VERSION ""

NS_ :

BS_:

BU_: RFA_BLEM TCU GWM _delete GENERIC TSTR

BO_ 966 Body_Info_14_FD2: 16 GWM
 SG_ NfcDevcAuthrzT_B_Rq : 33|1@0+ (1,0) [0|1] "SED"  GENERIC,_delete
 SG_ NfcDevc_D_Dsply : 47|4@0+ (1,0) [0|15] "SED"  GENERIC
 SG_ PwTrnkFrntRelay_B_Stat : 34|1@0+ (1,0) [0|1] "SED"  GENERIC
 SG_ PwTrnkFrontRleas_D_Src : 38|4@0+ (1,0) [0|15] "SED"  GENERIC
 SG_ TrnkFrontScnd_B_Falt : 39|1@0+ (1,0) [0|1] "SED"  GENERIC
 SG_ ExtLghtRear_D_RqBody : 25|2@0+ (1,0) [0|3] "SED"  GENERIC
 SG_ TrnkFrontInhbt_B_Stat : 26|1@0+ (1,0) [0|1] "SED"  GENERIC
 SG_ TrnkFrontRleas_D_Src : 20|3@0+ (1,0) [0|7] "SED"  GENERIC
 SG_ TrunkFrontRolCd_No_Actl : 7|16@0+ (1,0) [0|65535] "unitless"  GENERIC
 SG_ TrunkFrontOpen_No_Actl : 23|3@0+ (1,0) [0|7] "unitless"  GENERIC
 SG_ ScrtyHornActv_B_Rq : 27|1@0+ (1,0) [0|1] "SED"  GENERIC
 SG_ VehHorn_D_RqAlrt : 17|2@0+ (1,0) [0|3] "SED"  GENERIC
 SG_ VehHorn_D_Rq : 31|4@0+ (1,0) [0|15] "SED"  GENERIC

BO_ 119 BrakeSnData_3_FD2: 16 GWM
 SG_ VehTrvlDir_D_Stat : 23|3@0+ (1,0) [0|7] "SED"  GENERIC
 SG_ VehOverGnd_V_Est : 7|16@0+ (0.01,0) [0|655.33] "kph"  GENERIC
 SG_ VehLongComp_A_Actl : 49|10@0+ (0.035,-17.9) [-17.9|17.835] "m/s^2"  GENERIC,_delete,TCU
 SG_ VehLatComp_A_Actl : 43|10@0+ (0.035,-17.9) [-17.9|17.835] "m/s^2"  GENERIC
 SG_ VehYawComp_W_Actl : 19|12@0+ (0.03663,-75) [-75|74.92659] "deg/s"  GENERIC
 SG_ PrplWhlPrim_Tq_RqMx : 39|12@0+ (8,0) [0|32760] "Nm"  GENERIC

BO_ 517 PowertrainData_6_FD2: 16 GWM
 SG_ FapLc_B_Err : 10|1@0+ (1,0) [0|1] "SED"  GENERIC,RFA_BLEM,_delete
 SG_ BrkTot_Tq_RqFapLc : 7|13@0+ (4,0) [0|32764] "Nm"  GENERIC,_delete
 SG_ TrnAin_Pc_RqDrv : 9|10@0+ (0.1,0) [0|102.3] "percent"  GENERIC,_delete

BO_ 985 IPMA_Data2_FD2: 16 GWM
 SG_ LongCtrlEnblDRq_No_Cs : 63|8@0+ (1,0) [0|255] "Unitless"  GENERIC,RFA_BLEM,_delete
 SG_ LongCtrlEnblDRq_No_Cnt : 29|4@0+ (1,0) [0|15] "Unitless"  GENERIC,RFA_BLEM,_delete
 SG_ ClrExitAsst_D_Stat : 39|2@0+ (1,0) [0|3] "SED"  GENERIC,_delete
 SG_ ClrExitAsstMsgTxt_D_Rq : 52|4@0+ (1,0) [0|15] "SED"  GENERIC,_delete
 SG_ ClrExitAsstChime_D_Rq : 55|3@0+ (1,0) [0|7] "SED"  GENERIC,_delete
 SG_ PwSustnAdas_B_Rq : 48|1@0+ (1,0) [0|1] "SED"  GENERIC,_delete
 SG_ AdbDrvSide_B_Stat : 35|1@0+ (1,0) [0|1] "SED"  GENERIC,_delete
 SG_ LcwaMsgTxt_D_Stat : 37|2@0+ (1,0) [0|3] "SED"  GENERIC,_delete
 SG_ AdbDividedRoad_B_Stat : 30|1@0+ (1,0) [0|1] "SED"  GENERIC,_delete
 SG_ IsaVLimUnit_D_Rq : 15|2@0+ (1,0) [0|3] "SED"  GENERIC,_delete
 SG_ SblmYieldScnr_B_Stat : 31|1@0+ (1,0) [0|1] "SED"  GENERIC,_delete
 SG_ SblmStopScnr_B_Stat : 8|1@0+ (1,0) [0|1] "SED"  GENERIC,_delete
 SG_ IsaVLim_D_Rq : 7|8@0+ (1,0) [0|255] "SED"  GENERIC,_delete
 SG_ IaccVLimUnit_D_Rq : 11|2@0+ (1,0) [0|3] "SED"  GENERIC
 SG_ IaccVLim_D_Rq : 23|8@0+ (1,0) [0|255] "SED"  GENERIC
 SG_ DasAlrtInfo_D_Dsply : 13|2@0+ (1,0) [0|3] "SED"  GENERIC,_delete
 SG_ SblmRndAbtScnr_B_Stat : 9|1@0+ (1,0) [0|1] "SED"  GENERIC,_delete
 SG_ LongCtrlEnbl_D_Rq : 42|3@0+ (1,0) [0|7] "SED"  GENERIC,RFA_BLEM,_delete
 SG_ SblmPedCrossScnr_B_Stat : 33|1@0+ (1,0) [0|1] "SED"  GENERIC,_delete
 SG_ TsrRegionTxt_D_Stat : 47|5@0+ (1,0) [0|31] "SED"  GENERIC
 SG_ LongCtrlBrk_D_Rq : 25|2@0+ (1,0) [0|3] "SED"  GENERIC,_delete
 SG_ LdwChime_B_Rq : 34|1@0+ (1,0) [0|1] "SED"  GENERIC,_delete

BO_ 1927 TesterPhysicalReqWBCM: 64 TSTR
 SG_ TesterPhysicalReqWBCM : 7|64@0+ (1,0) [0|1.84467E+019] "unitless"  GENERIC

BO_ 942 ParkAid_Data2_FD2: 16 GWM
 SG_ ApaOffOptnSel_B_Avail : 51|1@0+ (1,0) [0|1] "SED"  GENERIC,_delete
 SG_ ApaSlotOption_B_Avail : 43|1@0+ (1,0) [0|1] "SED"  GENERIC,_delete
 SG_ ApaSlotAlrtSet_B_Stat : 44|1@0+ (1,0) [0|1] "SED"  GENERIC,_delete
 SG_ ApaSlotAlrt_B_Rq : 45|1@0+ (1,0) [0|1] "SED"  GENERIC,_delete
 SG_ ApaRmtFeatSel_B_Avail : 46|1@0+ (1,0) [0|1] "SED"  GENERIC,_delete
 SG_ ApaParkOutSel_B_Avail : 47|1@0+ (1,0) [0|1] "SED"  GENERIC,_delete
 SG_ ApaSys_D2_Stat : 35|4@0+ (1,0) [0|15] "SED"  GENERIC,_delete
 SG_ ApaSlotTrgt_D_Stat : 39|4@0+ (1,0) [0|15] "SED"  GENERIC,_delete
 SG_ ApaParkInSel_B_Avail : 24|1@0+ (1,0) [0|1] "SED"  GENERIC,_delete
 SG_ ApaMsgTxt_D2_Stat : 28|4@0+ (1,0) [0|15] "SED"  GENERIC,_delete
 SG_ ApaDynmcSlot_B_Stat : 29|1@0+ (1,0) [0|1] "SED"  GENERIC,_delete
 SG_ ApaDisplayMode_D_Stat : 31|2@0+ (1,0) [0|3] "SED"  GENERIC,_delete
 SG_ ApaControlMode_D_Stat : 16|1@0+ (1,0) [0|1] "SED"  GENERIC,_delete
 SG_ PrkBrkElRleas_B_RqApa : 50|1@0+ (1,0) [0|1] "SED"  GENERIC,_delete
 SG_ PrkAidAcsyRear_D_Stat : 18|2@0+ (1,0) [0|3] "SED"  GENERIC,_delete
 SG_ PrkAidAcsyFront_D_Stat : 20|2@0+ (1,0) [0|3] "SED"  GENERIC,_delete
 SG_ PrkAidRdiusRight_L_Dsply : 15|8@0+ (1,0) [0|255] "unitless"  GENERIC,_delete
 SG_ PrkAidRdiusLeft_L_Dsply : 7|8@0+ (1,0) [0|255] "unitless"  GENERIC,_delete
 SG_ PrkAidDrvDir_D_Stat : 23|3@0+ (1,0) [0|7] "SED"  GENERIC,_delete
 SG_ ApaDrvRq2MsgTxt_D_Rq : 55|4@0+ (1,0) [0|15] "SED"  GENERIC,_delete
 SG_ ApaDrvRq1MsgTxt_D_Rq : 42|3@0+ (1,0) [0|7] "SED"  GENERIC,RFA_BLEM,_delete

BO_ 1734 TesterPhysicalReqNFAM: 64 TSTR
 SG_ TesterPhysicalReqNFAM : 7|64@0+ (1,0) [0|1.84467E+019] "unitless"  GENERIC

BO_ 367 Av_ECGtoDAP: 64 GWM
 SG_ AuthctnStatIndx_No_Actl : 127|6@0+ (1,0) [0|63] "unitless"  GENERIC,_delete
 SG_ AuthctnStatId_No_Actl : 63|32@0+ (1,0) [0|4294967295] "unitless"  GENERIC,_delete
 SG_ AuthctnInfoLoc_D_Stat : 47|3@0+ (1,0) [0|7] "SED"  GENERIC,_delete
 SG_ AuthctnInfo_D_Stat : 33|2@0+ (1,0) [0|3] "SED"  GENERIC,_delete
 SG_ AuthctnInfoIndx_No_Actl : 39|6@0+ (1,0) [0|63] "unitless"  GENERIC,_delete
 SG_ AuthctnInfoId_No_Actl : 7|32@0+ (1,0) [0|4294967295] "unitless"  GENERIC,_delete
 SG_ HashNonce2_No_Res : 375|64@0+ (1,0) [0|1.84467440737096E+019] "unitless"  GENERIC,_delete
 SG_ HashNonce1_No_Res : 311|64@0+ (1,0) [0|1.84467440737096E+019] "unitless"  GENERIC,_delete
 SG_ HashSalt2_No_Res : 247|64@0+ (1,0) [0|1.84467440737096E+019] "unitless"  GENERIC,_delete
 SG_ HashSalt1_No_Res : 183|64@0+ (1,0) [0|1.84467440737096E+019] "unitless"  GENERIC,_delete
 SG_ HashIndx_D_Stat : 169|2@0+ (1,0) [0|3] "SED"  GENERIC,_delete
 SG_ HashIndx_No_Actl : 175|6@0+ (1,0) [0|63] "unitless"  GENERIC,_delete
 SG_ HashId_No_Actl : 143|32@0+ (1,0) [0|4294967295] "unitless"  GENERIC,_delete
 SG_ ApnlPsswrdType_D_Stat : 121|4@0+ (1,0) [0|15] "SED"  GENERIC,_delete
 SG_ ApnlPsswrdIndx_No_Actl : 133|6@0+ (1,0) [0|63] "unitless"  GENERIC,_delete
 SG_ ApnlPsswrdId_No_Actl : 95|32@0+ (1,0) [0|4294967295] "unitless"  GENERIC,_delete
 SG_ AuthctnStatRtry_No_Actl : 55|4@0+ (1,0) [0|15] "unitless"  GENERIC,_delete
 SG_ AuthctnStatChnl_D_Stat : 51|4@0+ (1,0) [0|15] "SED"  GENERIC,_delete
 SG_ AuthctnStat_D_Stat : 44|2@0+ (1,0) [0|3] "SED"  GENERIC,_delete

BO_ 1203 Av_PartName: 64 GWM
 SG_ ApnlNameTxt18_No_Actl : 143|8@0+ (1,0) [0|255] "unitless"  GENERIC,_delete
 SG_ ApnlNameTxt17_No_Actl : 135|8@0+ (1,0) [0|255] "unitless"  GENERIC,_delete
 SG_ ApnlNameTxt16_No_Actl : 127|8@0+ (1,0) [0|255] "unitless"  GENERIC,_delete
 SG_ ApnlNameTxt15_No_Actl : 119|8@0+ (1,0) [0|255] "unitless"  GENERIC,_delete
 SG_ ApnlNameTxt14_No_Actl : 111|8@0+ (1,0) [0|255] "unitless"  GENERIC,_delete
 SG_ ApnlNameTxt13_No_Actl : 103|8@0+ (1,0) [0|255] "unitless"  GENERIC,_delete
 SG_ ApnlNameTxt12_No_Actl : 95|8@0+ (1,0) [0|255] "unitless"  GENERIC,_delete
 SG_ ApnlNameTxt11_No_Actl : 87|8@0+ (1,0) [0|255] "unitless"  GENERIC,_delete
 SG_ ApnlNameTxt10_No_Actl : 79|8@0+ (1,0) [0|255] "unitless"  GENERIC,_delete
 SG_ ApnlNameTxt09_No_Actl : 71|8@0+ (1,0) [0|255] "unitless"  GENERIC,_delete
 SG_ ApnlNameTxt08_No_Actl : 63|8@0+ (1,0) [0|255] "unitless"  GENERIC,_delete
 SG_ ApnlNameTxt07_No_Actl : 55|8@0+ (1,0) [0|255] "unitless"  GENERIC,_delete
 SG_ ApnlNameTxt06_No_Actl : 47|8@0+ (1,0) [0|255] "unitless"  GENERIC,_delete
 SG_ ApnlNameTxt05_No_Actl : 39|8@0+ (1,0) [0|255] "unitless"  GENERIC,_delete
 SG_ ApnlNameTxt04_No_Actl : 31|8@0+ (1,0) [0|255] "unitless"  GENERIC,_delete
 SG_ ApnlNameTxt03_No_Actl : 23|8@0+ (1,0) [0|255] "unitless"  GENERIC,_delete
 SG_ ApnlNameTxt02_No_Actl : 15|8@0+ (1,0) [0|255] "unitless"  GENERIC,_delete
 SG_ ApnlNameTxt01_No_Actl : 7|8@0+ (1,0) [0|255] "unitless"  GENERIC,_delete

BO_ 948 Tire_Pressure_Stat_FD2: 16 GWM
 SG_ TlghtTestPrecnd_D2_Stat : 52|3@0+ (1,0) [0|7] "SED"  GENERIC,_delete
 SG_ TlghtTestLght_D2_Stat : 55|3@0+ (1,0) [0|7] "SED"  GENERIC,_delete
 SG_ Tire_Press_Placrd_Rear : 47|8@0+ (1,0) [0|255] "pounds/inch^2"  GENERIC,_delete
 SG_ Tire_Press_Placrd_Frnt : 39|8@0+ (1,0) [0|255] "pounds/inch^2"  GENERIC,_delete
 SG_ Tire_Press_ILR_Stat : 27|4@0+ (1,0) [0|15] "SED"  GENERIC,TCU,_delete
 SG_ Tire_Press_IRR_Stat : 31|4@0+ (1,0) [0|15] "SED"  GENERIC,TCU,_delete
 SG_ Tire_Press_LR_OLR_Stat : 19|4@0+ (1,0) [0|15] "SED"  GENERIC,TCU,_delete
 SG_ Tire_Press_RR_ORR_Stat : 23|4@0+ (1,0) [0|15] "SED"  GENERIC,TCU,_delete
 SG_ Tire_Press_RF_Stat : 11|4@0+ (1,0) [0|15] "SED"  GENERIC,TCU,_delete
 SG_ Tire_Press_LF_Stat : 15|4@0+ (1,0) [0|15] "SED"  GENERIC,TCU,_delete
 SG_ Tire_Press_System_Stat : 7|4@0+ (1,0) [0|15] "SED"  GENERIC,_delete
 SG_ Tire_Press_Telltale : 3|2@0+ (1,0) [0|3] "SED"  GENERIC,_delete
 SG_ TirePReset_D_Stat : 1|2@0+ (1,0) [0|3] "Discrete"  GENERIC,_delete

BO_ 131 Steering_Data_FD2: 8 GWM
 SG_ TurnLghtSwtch_D_Arb : 55|4@0+ (1,0) [0|15] "SED"  GENERIC
 SG_ ElPwAsstSte_B_RqDactv : 7|1@0+ (1,0) [0|1] "SED"  GENERIC
 SG_ HeadLghtHiCtrl_D_RqAhb : 43|3@0+ (1,0) [0|7] "SED"  GENERIC,_delete
 SG_ AhbStat_B_Dsply : 33|1@0+ (1,0) [0|1] "SED"  GENERIC,_delete
 SG_ WiprFrontSwtch_D_Stat : 47|4@0+ (1,0) [0|15] "SED"  GENERIC,_delete
 SG_ HeadLghtHiOn_B_StatAhb : 34|1@0+ (1,0) [0|1] "SED"  GENERIC,_delete
 SG_ HeadLghtHiFlash_D_Actl : 36|2@0+ (1,0) [0|3] "SED"  GENERIC,_delete
 SG_ TjaButtnOnOffPress : 40|1@0+ (1,0) [0|1] "SED"  GENERIC,_delete
 SG_ AccButtnGapTogglePress : 32|1@0+ (1,0) [0|1] "SED"  GENERIC,_delete
 SG_ WiprFront_D_Stat : 3|4@0+ (1,0) [0|15] "SED"  GENERIC,TCU,_delete
 SG_ TurnLghtSwtch_D_Stat : 5|2@0+ (1,0) [0|3] "SED"  GENERIC,_delete
 SG_ LghtAmb_D_Sns : 15|3@0+ (1,0) [0|7] "SED"  GENERIC,_delete
 SG_ AccButtnGapIncPress : 11|1@0+ (1,0) [0|1] "SED"  GENERIC,_delete
 SG_ AccButtnGapDecPress : 12|1@0+ (1,0) [0|1] "SED"  GENERIC,_delete
 SG_ AslButtnOnOffPress : 9|1@0+ (1,0) [0|1] "SED"  GENERIC,_delete
 SG_ AslButtnOnOffCnclPress : 10|1@0+ (1,0) [0|1] "SED"  GENERIC,_delete
 SG_ CcButtnOnPress : 37|1@0+ (1,0) [0|1] "SED"  GENERIC,_delete
 SG_ CcButtnOnOffPress : 38|1@0+ (1,0) [0|1] "SED"  GENERIC,_delete
 SG_ CcButtnOnOffCnclPress : 39|1@0+ (1,0) [0|1] "SED"  GENERIC,_delete
 SG_ CcButtnOffPress : 24|1@0+ (1,0) [0|1] "SED"  GENERIC,_delete
 SG_ CcAsllButtnResPress : 25|1@0+ (1,0) [0|1] "SED"  GENERIC,_delete
 SG_ CcAslButtnSetPress : 26|1@0+ (1,0) [0|1] "SED"  GENERIC,_delete
 SG_ CcAslButtnSetIncPress : 27|1@0+ (1,0) [0|1] "SED"  GENERIC,_delete
 SG_ CcAslButtnSetDecPress : 28|1@0+ (1,0) [0|1] "SED"  GENERIC,_delete
 SG_ CcAslButtnResIncPress : 29|1@0+ (1,0) [0|1] "SED"  GENERIC,_delete
 SG_ CcAslButtnResDecPress : 30|1@0+ (1,0) [0|1] "SED"  GENERIC,_delete
 SG_ CcAslButtnOnPress : 31|1@0+ (1,0) [0|1] "SED"  GENERIC,_delete
 SG_ CcAslButtnOnOffCncl : 16|1@0+ (1,0) [0|1] "SED"  GENERIC,_delete
 SG_ CcAslButtnOffCnclPress : 17|1@0+ (1,0) [0|1] "SED"  GENERIC,_delete
 SG_ CcAslButtnIndxIncPress : 18|1@0+ (1,0) [0|1] "SED"  GENERIC,_delete
 SG_ CcAslButtnIndxDecPress : 19|1@0+ (1,0) [0|1] "SED"  GENERIC,_delete
 SG_ CcAslButtnDeny_B_Actl : 20|1@0+ (1,0) [0|1] "SED"  GENERIC,_delete
 SG_ CcAslButtnCnclResPress : 21|1@0+ (1,0) [0|1] "SED"  GENERIC,_delete
 SG_ CcAslButtnCnclPress : 8|1@0+ (1,0) [0|1] "SED"  GENERIC,_delete
 SG_ LaSwtchPos_D_Stat : 23|2@0+ (1,0) [0|3] "SED"  GENERIC,_delete

BO_ 963 BCM_Lamp_Stat_FD2: 16 GWM
 SG_ Illuminated_Entry_Stat : 63|2@0+ (1,0) [0|3] "SED"  GENERIC,_delete
 SG_ Dr_Courtesy_Light_Stat : 49|2@0+ (1,0) [0|3] "SED"  GENERIC,_delete
 SG_ Courtesy_Delay_Status : 51|2@0+ (1,0) [0|3] "SED"  GENERIC,_delete
 SG_ ImpactEvntFdbck_D_Stat : 53|2@0+ (1,0) [0|3] "SED"  GENERIC,_delete
 SG_ WrlssAcsyChrgInhbt_B_Rq : 40|1@0+ (1,0) [0|1] "SED"  GENERIC,_delete
 SG_ PudLampPsngr_D_Rq : 57|2@0+ (1,0) [0|3] "SED"  GENERIC
 SG_ HeadLampLoOut_B_Stat : 32|1@0+ (1,0) [0|1] "SED"  GENERIC,_delete
 SG_ CrnrLghtRight_Pc_Rq : 47|7@0+ (1,0) [0|100] "percent"  GENERIC,_delete
 SG_ CrnrLghtLeft_Pc_Rq : 39|7@0+ (1,0) [0|100] "percent"  GENERIC,_delete
 SG_ HeadLghtHiFdbck_D_Stat : 55|2@0+ (1,0) [0|3] "SED"  GENERIC,_delete
 SG_ PudLampDrv_D_Rq : 59|2@0+ (1,0) [0|3] "SED"  GENERIC
 SG_ TrnNotInPrkChime_B_Rq : 24|1@0+ (1,0) [0|1] "SED"  GENERIC,_delete
 SG_ PrkLightChime_B_Rq : 25|1@0+ (1,0) [0|1] "SED"  GENERIC,_delete
 SG_ KeyInIgnWarn_B_Cmd : 27|1@0+ (1,0) [0|1] "SED"  GENERIC,_delete
 SG_ HomeSafeLtChime_B_Rq : 28|1@0+ (1,0) [0|1] "SED"  GENERIC,_delete
 SG_ StopLghtOn_B_Stat : 8|1@0+ (1,0) [0|1] "SED"  GENERIC,_delete
 SG_ RvrseLghtOn_B_Stat : 9|1@0+ (1,0) [0|1] "SED"  GENERIC,_delete
 SG_ PrkLght_D_Stat : 13|2@0+ (1,0) [0|3] "SED"  GENERIC,_delete
 SG_ HeadLghtSwtch_D_Stat : 15|2@0+ (1,0) [0|3] "SED"  GENERIC,_delete
 SG_ HeadLampLoFrOn_B_Stat : 2|1@0+ (1,0) [0|1] "SED"  GENERIC,_delete
 SG_ HeadLampLoFlOn_B_Stat : 3|1@0+ (1,0) [0|1] "SED"  GENERIC,_delete
 SG_ HeadLampLoActv_B_Stat : 4|1@0+ (1,0) [0|1] "SED"  GENERIC,TCU,_delete
 SG_ Headlamp_On_Wrning_Cmd : 29|1@0+ (1,0) [0|1] "SED"  GENERIC,_delete
 SG_ Park_Brake_Chime_Rqst : 26|1@0+ (1,0) [0|1] "SED"  GENERIC,_delete
 SG_ HeadLghtHiOn_B_Stat : 1|1@0+ (1,0) [0|1] "SED"  GENERIC,TCU,_delete
 SG_ BrkWarnInd_B_Rq : 20|1@0+ (1,0) [0|1] "SED"  GENERIC,_delete
 SG_ Brk_Fluid_Lvl_Low : 31|2@0+ (1,0) [0|3] "SED"  GENERIC,_delete
 SG_ ReducedGuard_D_Stat : 19|2@0+ (1,0) [0|3] "SED"  GENERIC,_delete
 SG_ Perimeter_Alarm_Status : 17|2@0+ (1,0) [0|3] "SED"  GENERIC,_delete
 SG_ Courtesy_BSave_Stat : 7|2@0+ (1,0) [0|3] "SED"  GENERIC,_delete
 SG_ DrTgateLck_D_Stat : 61|2@0+ (1,0) [0|3] "SED"  GENERIC,_delete
 SG_ WndwGlbl_D_Cmd : 23|3@0+ (1,0) [0|7] "SED"  GENERIC,_delete
 SG_ PudLamp_D_Rq : 11|2@0+ (1,0) [0|3] "SED"  GENERIC
 SG_ DayRnngLampOn_B_Stat : 5|1@0+ (1,0) [0|1] "SED"  GENERIC,TCU,_delete
 SG_ PerimeterAlarmChimeRq : 0|1@0+ (1,0) [0|1] "SED"  GENERIC,_delete

BO_ 908 DisplayFileID: 8 GWM
 SG_ ApnlLogoId_No_Actl : 7|56@0+ (1,0) [0|7.20575940379279E+016] "unitless"  GENERIC,_delete

BO_ 2609983704 OTAPhysGWM_ECGtoRFA_BLEM: 64 GWM
 SG_ OTAPhysGWM_ECGtoRFA_BLEM : 7|29@0+ (1,0) [0|536870911] "unitless"  GENERIC,RFA_BLEM

BO_ 2610126924 OTAPhysRFA_BLEMtoGWM_ECG: 64 RFA_BLEM
 SG_ OTAPhysRFA_BLEMtoGWM_ECG : 7|29@0+ (1,0) [0|536870911] "unitless"  GENERIC,GWM

BO_ 2611032280 PARSEDPhysGWM_ECGtoRFA_BLEM: 64 GWM
 SG_ PARSEDPhysGWM_ECGtoRFA_BLEM : 7|29@0+ (1,0) [0|536870911] "unitless"  GENERIC,RFA_BLEM

BO_ 2611175500 PARSEDPhysRFA_BLEMtoGWM_ECG: 64 RFA_BLEM
 SG_ PARSEDPhysRFA_BLEMtoGWM_ECG : 7|29@0+ (1,0) [0|536870911] "unitless"  GENERIC,GWM

BO_ 2612080856 PARSEDPushFcGWM_ECGtoRFA_BLEM: 8 GWM
 SG_ PARSEDPushFcGWM_ECGtoRFA_BLEM : 7|29@0+ (1,0) [0|536870911] "unitless"  GENERIC,RFA_BLEM

BO_ 2612224076 PARSEDPushRFA_BLEMtoGWM_ECG: 8 RFA_BLEM
 SG_ PARSEDPushRFA_BLEMtoGWM_ECG : 7|29@0+ (1,0) [0|536870911] "unitless"  GENERIC,GWM

BO_ 2613129432 SymKeyPhysGWM_ECGtoRFA_BLEM: 64 GWM
 SG_ SymKeyPhysGWM_ECGtoRFA_BLEM : 7|29@0+ (1,0) [0|536870911] "unitless"  GENERIC,RFA_BLEM

BO_ 2613272652 SymKeyPhysRFA_BLEMtoGWM_ECG: 64 RFA_BLEM
 SG_ SymKeyPhysRFA_BLEMtoGWM_ECG : 7|29@0+ (1,0) [0|536870911] "unitless"  GENERIC,GWM

BO_ 932 Body_Info_13_FD2: 16 GWM
 SG_ CanMsg3A4_UNUSED_8bit_4 : 63|8@0+ (1,0) [255|255] "unitless"  GENERIC
 SG_ CanMsg3A4_UNUSED_8bit_3 : 55|8@0+ (1,0) [255|255] "unitless"  GENERIC
 SG_ CanMsg3A4_UNUSED_8bit_2 : 47|8@0+ (1,0) [255|255] "unitless"  GENERIC
 SG_ CanMsg3A4_UNUSED_8bit_1 : 39|8@0+ (1,0) [255|255] "unitless"  GENERIC
 SG_ CanMsg3A4_UNUSED_7bit_1 : 30|7@0+ (1,0) [127|127] "unitless"  GENERIC
 SG_ RmtCtlBattMntr_B_Falt : 31|1@0+ (1,0) [0|1] "SED"  GENERIC,RFA_BLEM
 SG_ VehStrtInhbt_D_Stat : 23|1@0+ (1,0) [0|1] "SED"  GENERIC
 SG_ VehOnCtl_D_Stat : 22|2@0+ (1,0) [0|3] "SED"  GENERIC
 SG_ VehOnSrc2_D_Stat : 15|4@0+ (1,0) [0|15] "SED"  GENERIC
 SG_ CanMsg3A4_No_Crc : 7|8@0+ (1,0) [0|255] "unitless"  GENERIC
 SG_ CanMsg3A4_No_Cnt : 11|4@0+ (1,0) [0|15] "unitless"  GENERIC
 SG_ VehInhbtMde_D_Stat : 20|3@0+ (1,0) [0|7] "SED"  GENERIC
 SG_ ChildLck_D_Dsply : 17|2@0+ (1,0) [0|3] "SED"  GENERIC,_delete

BO_ 118 BrakeSnData_5_FD2: 16 GWM
 SG_ BrkCtrFnd_B_Stat : 39|1@0+ (1,0) [0|1] "SED"  GENERIC,_delete
 SG_ BrkTerrMdeChng_D_Rdy : 54|3@0+ (1,0) [0|7] "SED"  GENERIC,_delete
 SG_ BrkTerrMde_D_Actl : 38|3@0+ (1,0) [0|7] "SED"  GENERIC,_delete
 SG_ DrvSte_D_Stat : 19|4@0+ (1,0) [0|15] "SED"  GENERIC,_delete
 SG_ DrvSte_Tq_Rq : 31|8@0+ (0.0625,-8) [-8|7.8125] "Nm"  GENERIC,_delete
 SG_ EmgcyBrkLamp_D_Rq : 21|2@0+ (1,0) [0|3] "SED"  GENERIC,_delete
 SG_ StopLamp_B_RqBrk : 7|1@0+ (1,0) [0|1] "SED"  GENERIC,_delete
 SG_ SteWhlCompAnEst_D_Qf : 23|2@0+ (1,0) [0|3] "SED"  GENERIC
 SG_ SteWhlComp_An_Est : 6|15@0+ (0.1,-1600) [-1600|1676.7] "degrees"  GENERIC

BO_ 1968 TesterPhysicalReqRDAPM: 64 TSTR
 SG_ TesterPhysicalReqRDAPM : 7|64@0+ (1,0) [0|1.84467E+019] "unitless"  GENERIC

BO_ 1936 TesterPhysicalReqLDAPM: 64 TSTR
 SG_ TesterPhysicalReqLDAPM : 7|64@0+ (1,0) [0|1.84467E+019] "unitless"  GENERIC

BO_ 132 GlobalClock_Data_FD2: 16 GWM
 SG_ GlblClkYr_No_Actl : 7|8@0+ (1,2000) [2000|2255] "year"  GENERIC,TCU
 SG_ GlblClkScnd_No_Actl : 47|8@0+ (1,0) [0|255] "second"  GENERIC,TCU
 SG_ GlblClkMnte_No_Actl : 39|8@0+ (1,0) [0|255] "minute"  GENERIC,TCU
 SG_ GlblClkHr_No_Actl : 55|8@0+ (1,0) [0|255] "hour"  GENERIC,TCU
 SG_ GlblClkDay_No_Actl : 23|16@0+ (1,0) [0|65535] "julian day"  GENERIC,TCU

BO_ 1045 BrakeSysFeatures_FD2: 16 GWM
 SG_ VehStab_D_Stat : 55|4@0+ (1,0) [0|15] "SED"  GENERIC,_delete
 SG_ BrkFluidLvl_D_Stat : 17|2@0+ (1,0) [0|3] "SED"  GENERIC,_delete
 SG_ LsmcBrkDecel_D_Stat : 39|3@0+ (1,0) [0|7] "SED"  GENERIC
 SG_ VehYawNonLin_W_Rq : 51|12@0+ (0.03663,-75) [-75|74.92659] "deg/s"  GENERIC,_delete
 SG_ VehYawLin_W_Rq : 35|12@0+ (0.03663,-75) [-75|74.92659] "deg/s"  GENERIC,_delete
 SG_ VehVActlBrk_No_Cs : 31|8@0+ (1,0) [0|255] "unitless"  GENERIC,RFA_BLEM
 SG_ Veh_V_ActlBrk : 7|16@0+ (0.01,0) [0|655.35] "kph"  GENERIC,RFA_BLEM
 SG_ VehVActlBrk_No_Cnt : 21|4@0+ (1,0) [0|15] "unitless"  GENERIC,RFA_BLEM
 SG_ VehVActlBrk_D_Qf : 23|2@0+ (1,0) [0|3] "SED"  GENERIC,RFA_BLEM

BO_ 947 BodyInfo_3_FD2: 16 GWM
 SG_ ValetMode_D_Mem : 16|1@0+ (1,0) [0|1] "SED"  GENERIC
 SG_ DimmingLvlEvnt_No_Actl : 18|2@0+ (1,0) [0|3] "unitless"  GENERIC
 SG_ DrStatDrvErrCnt_B_Stat : 19|1@0+ (1,0) [0|1] "SED"  GENERIC
 SG_ TurnLghtRight_D_Rq : 63|2@0+ (1,0) [0|3] "SED"  GENERIC,TCU
 SG_ TurnLghtRightOn_B_Stat : 35|1@0+ (1,0) [0|1] "SED"  GENERIC,TCU,_delete
 SG_ TurnLghtLeftOn_B_Stat : 54|1@0+ (1,0) [0|1] "SED"  GENERIC,TCU,_delete
 SG_ FogLghtRearOn_B_Stat : 1|1@0+ (1,0) [0|1] "SED"  GENERIC,TCU,_delete
 SG_ Backlit_LED_Status : 23|4@0+ (1,0) [0|15] "SED"  GENERIC
 SG_ TurnLghtLeft_D_Rq : 9|2@0+ (1,0) [0|3] "SED"  GENERIC,TCU
 SG_ FogLghtFrontOn_B_Stat : 56|1@0+ (1,0) [0|1] "SED"  GENERIC,TCU,_delete
 SG_ IgnKeyType_D_Actl : 39|4@0+ (1,0) [0|15] "SED"  GENERIC
 SG_ Parklamp_Status : 3|2@0+ (1,0) [0|3] "SED"  GENERIC,TCU
 SG_ Litval : 47|8@0+ (1,0) [0|253] "SED"  GENERIC
 SG_ Key_In_Ignition_Stat : 11|1@0+ (1,0) [0|1] "SED"  GENERIC
 SG_ Ignition_Status : 7|4@0+ (1,0) [0|15] "SED"  GENERIC,RFA_BLEM,TCU
 SG_ Dimming_Lvl : 31|8@0+ (1,0) [0|253] "SED"  GENERIC,TCU
 SG_ Day_Night_Status : 15|2@0+ (1,0) [0|3] "SED"  GENERIC,TCU
 SG_ Remote_Start_Status : 13|2@0+ (1,0) [0|3] "SED"  GENERIC,RFA_BLEM
 SG_ DrStatTgate_B_Actl : 0|1@0+ (1,0) [0|1] "SED"  GENERIC,TCU,RFA_BLEM
 SG_ DrStatRr_B_Actl : 49|1@0+ (1,0) [0|1] "SED"  GENERIC,TCU,RFA_BLEM
 SG_ DrStatRl_B_Actl : 48|1@0+ (1,0) [0|1] "SED"  GENERIC,TCU,RFA_BLEM
 SG_ DrStatPsngr_B_Actl : 60|1@0+ (1,0) [0|1] "SED"  GENERIC,TCU,RFA_BLEM
 SG_ DrStatInnrTgate_B_Actl : 58|1@0+ (1,0) [0|1] "SED"  GENERIC,TCU,RFA_BLEM
 SG_ DrStatHood_B_Actl : 59|1@0+ (1,0) [0|1] "SED"  GENERIC,TCU,RFA_BLEM
 SG_ DrStatDrv_B_Actl : 61|1@0+ (1,0) [0|1] "SED"  GENERIC,TCU,RFA_BLEM
 SG_ PrkBrkActv_B_Actl : 55|1@0+ (1,0) [0|1] "SED"  GENERIC,TCU,_delete
 SG_ LifeCycMde_D_Actl : 53|4@0+ (1,0) [0|15] "SED"  GENERIC,RFA_BLEM,TCU
 SG_ Delay_Accy : 57|1@0+ (1,0) [0|1] "SED"  GENERIC,TCU
 SG_ CrashEvnt_D_Stat : 34|2@0+ (1,0) [0|3] "SED"  GENERIC
 SG_ FuelPmpInhbt_B_Stat : 32|1@0+ (1,0) [0|1] "SED"  GENERIC
 SG_ BodySrvcRqd_B_Rq : 10|1@0+ (1,0) [0|1] "SED"  GENERIC

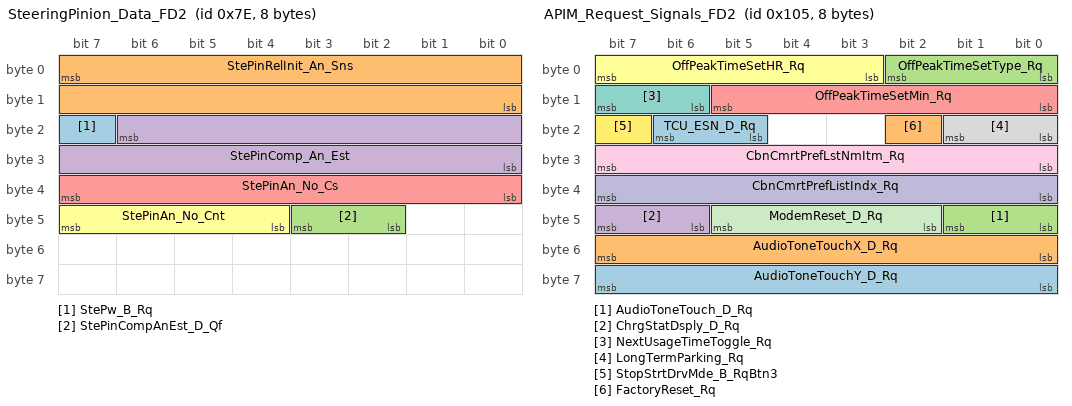
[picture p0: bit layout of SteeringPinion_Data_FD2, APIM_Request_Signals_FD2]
BO_ 126 SteeringPinion_Data_FD2: 8 GWM
 SG_ StePw_B_Rq : 23|1@0+ (1,0) [0|1] "SED"  GENERIC,_delete
 SG_ StePinRelInit_An_Sns : 7|16@0+ (0.1,-3200) [-3200|3353.3] "degrees"  GENERIC,_delete
 SG_ StePinCompAnEst_D_Qf : 43|2@0+ (1,0) [0|3] "SED"  GENERIC,_delete
 SG_ StePinComp_An_Est : 22|15@0+ (0.1,-1600) [-1600|1676.7] "degrees"  GENERIC,TCU,_delete
 SG_ StePinAn_No_Cs : 39|8@0+ (1,0) [0|255] "unitless"  GENERIC,_delete
 SG_ StePinAn_No_Cnt : 47|4@0+ (1,0) [0|15] "unitless"  GENERIC,_delete

BO_ 1766 TesterPhysicalReqTCUB: 64 TSTR
 SG_ TesterPhysicalReqTCUB : 7|64@0+ (1,0) [0|1.84467E+019] "unitless"  GENERIC

BO_ 357 EngBrakeData_FD2: 16 GWM
 SG_ BPedDrvAppl_D_Qf : 15|2@0+ (1,0) [0|3] "SED"  GENERIC,_delete
 SG_ CmbbDeny_B_ActlPrpl : 3|1@0+ (1,0) [0|1] "SED"  GENERIC,_delete
 SG_ BpedDrvAppl_No_Cs : 31|8@0+ (1,0) [0|255] "unitless"  GENERIC,_delete
 SG_ PrplTqMnSat_B_Actl : 41|1@0+ (1,0) [0|1] "SED"  GENERIC,_delete
 SG_ VehStrtStop_D_Rq : 44|2@0+ (1,0) [0|3] "SED"  GENERIC,_delete
 SG_ BpedDrvAppl_No_Cnt : 35|4@0+ (1,0) [0|15] "unitless"  GENERIC,_delete
 SG_ BpedDrvAppl_D_Actl : 5|2@0+ (1,0) [0|3] "SED"  GENERIC,TCU,RFA_BLEM
 SG_ CmbbEngTqMn_B_Actl : 7|1@0+ (1,0) [0|1] "SED"  GENERIC,_delete
 SG_ Veh_V_DsplyCcSet : 23|8@0+ (1,0) [0|253] "unitless"  GENERIC
 SG_ AccEngStat_D_Actl : 2|3@0+ (1,0) [0|7] "SED"  GENERIC,_delete
 SG_ CcMde_D_Actl : 13|3@0+ (1,0) [0|7] "SED"  GENERIC,_delete
 SG_ CcStat_D_Actl : 10|3@0+ (1,0) [0|7] "SED"  GENERIC
 SG_ EngAout_N_MnAllw : 52|13@0+ (2,0) [0|16382] "rpm"  GENERIC,_delete
 SG_ CcOvrrdActv_B_Actl : 6|1@0+ (1,0) [0|1] "SED"  GENERIC
 SG_ AccStopMde_D_Rq : 39|2@0+ (1,0) [0|3] "SED"  GENERIC,_delete

BO_ 651 TCU_Send_Signals: 16 TCU
 SG_ CrnkInhbtSrvcHlth_B_St : 36|1@0+ (1,0) [0|1] "SED"  GENERIC,GWM
 SG_ TelematicsSrvc_D_St : 47|3@0+ (1,0) [0|7] "SED"  GENERIC,GWM
 SG_ EmgcyCallMute_D_Stat : 39|3@0+ (1,0) [0|7] "SED"  GENERIC,GWM

BO_ 261 APIM_Request_Signals_FD2: 8 GWM
 SG_ AudioToneTouchY_D_Rq : 63|8@0+ (1,0) [0|255] "SED"  GENERIC
 SG_ AudioToneTouchX_D_Rq : 55|8@0+ (1,0) [0|255] "SED"  GENERIC
 SG_ AudioToneTouch_D_Rq : 41|2@0+ (1,0) [0|3] "SED"  GENERIC
 SG_ ChrgStatDsply_D_Rq : 47|2@0+ (1,0) [0|3] "SED"  GENERIC
 SG_ OffPeakTimeSetMin_Rq : 13|6@0+ (1,0) [0|63] "unitless"  GENERIC
 SG_ OffPeakTimeSetHR_Rq : 7|5@0+ (1,0) [0|31] "unitless"  GENERIC
 SG_ NextUsageTimeToggle_Rq : 15|2@0+ (1,0) [0|3] "SED"  GENERIC
 SG_ LongTermParking_Rq : 17|2@0+ (1,0) [0|3] "SED"  GENERIC
 SG_ CbnCmrtPrefLstNmItm_Rq : 31|8@0+ (1,0) [0|255] "unitless"  GENERIC
 SG_ CbnCmrtPrefListIndx_Rq : 39|8@0+ (1,0) [0|255] "unitless"  GENERIC
 SG_ ModemReset_D_Rq : 45|4@0+ (1,0) [0|15] "SED"  GENERIC,RFA_BLEM
 SG_ StopStrtDrvMde_B_RqBtn3 : 23|1@0+ (1,0) [0|1] "SED"  GENERIC
 SG_ TCU_ESN_D_Rq : 22|2@0+ (1,0) [0|3] "SED"  GENERIC,TCU
 SG_ FactoryReset_Rq : 18|1@0+ (1,0) [0|1] "SED"  GENERIC,RFA_BLEM
 SG_ OffPeakTimeSetType_Rq : 2|3@0+ (1,0) [0|7] "SED"  GENERIC

BO_ 600 APIM_RFA_BLEM_Tx_FD2: 8 GWM
 SG_ APIM_RFA_BLEM_Tx : 7|64@0+ (1,0) [0|1.84467440737096E+019] "unitless"  GENERIC,_delete,RFA_BLEM

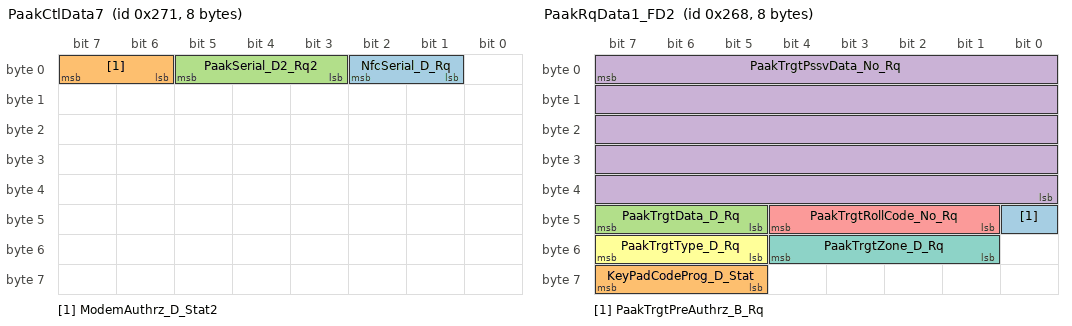
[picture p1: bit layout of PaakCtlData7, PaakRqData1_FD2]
BO_ 625 PaakCtlData7: 8 GWM
 SG_ NfcSerial_D_Rq : 2|2@0+ (1,0) [0|3] "SED"  GENERIC,_delete
 SG_ ModemAuthrz_D_Stat2 : 7|2@0+ (1,0) [0|3] "SED"  GENERIC,_delete,RFA_BLEM
 SG_ PaakSerial_D2_Rq2 : 5|3@0+ (1,0) [0|7] "SED"  GENERIC,_delete,RFA_BLEM

BO_ 616 PaakRqData1_FD2: 8 GWM
 SG_ PaakTrgtPreAuthrz_B_Rq : 40|1@0+ (1,0) [0|1] "SED"  GENERIC,_delete,RFA_BLEM
 SG_ KeyPadCodeProg_D_Stat : 63|3@0+ (1,0) [0|7] "SED"  GENERIC,_delete,RFA_BLEM
 SG_ PaakTrgtData_D_Rq : 47|3@0+ (1,0) [0|7] "SED"  GENERIC,_delete,RFA_BLEM
 SG_ PaakTrgtPssvData_No_Rq : 7|40@0+ (1,0) [0|1099511627775] "unitless"  GENERIC,_delete,RFA_BLEM
 SG_ PaakTrgtRollCode_No_Rq : 44|4@0+ (1,0) [0|15] "unitless"  GENERIC,_delete,RFA_BLEM
 SG_ PaakTrgtType_D_Rq : 55|3@0+ (1,0) [0|7] "SED"  GENERIC,_delete,RFA_BLEM
 SG_ PaakTrgtZone_D_Rq : 52|4@0+ (1,0) [0|15] "SED"  GENERIC,_delete,RFA_BLEM

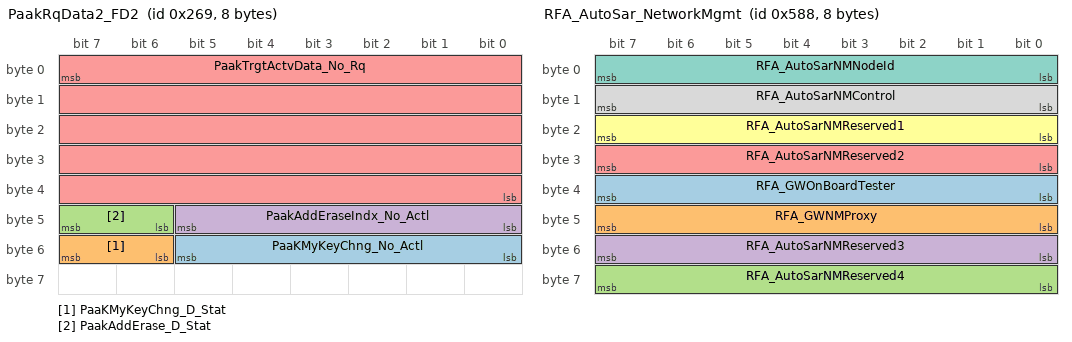
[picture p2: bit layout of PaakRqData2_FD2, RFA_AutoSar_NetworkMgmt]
BO_ 617 PaakRqData2_FD2: 8 GWM
 SG_ PaaKMyKeyChng_No_Actl : 53|6@0+ (1,0) [0|63] "unitless"  GENERIC,RFA_BLEM,_delete
 SG_ PaaKMyKeyChng_D_Stat : 55|2@0+ (1,0) [0|3] "SED"  GENERIC,RFA_BLEM,_delete
 SG_ PaakAddErase_D_Stat : 47|2@0+ (1,0) [0|3] "SED"  GENERIC,_delete,RFA_BLEM
 SG_ PaakAddEraseIndx_No_Actl : 45|6@0+ (1,0) [0|63] "unitless"  GENERIC,_delete,RFA_BLEM
 SG_ PaakTrgtActvData_No_Rq : 7|40@0+ (1,0) [0|1099511627775] "unitless"  GENERIC,_delete,RFA_BLEM

BO_ 1119 LocationServices_Data2_FD2: 8 GWM
 SG_ LocationServices_2 : 7|64@0+ (1,0) [0|1.84467440737096E+019] "unitless"  GENERIC,_delete,RFA_BLEM

BO_ 622 Body_Info_12_FD2: 16 GWM
 SG_ FobCtlType_D_Stat : 43|2@0+ (1,0) [0|3] "SED"  GENERIC,_delete,RFA_BLEM
 SG_ FobCtlRollCode_No_Stat : 47|4@0+ (1,0) [0|15] "unitless"  GENERIC,_delete,RFA_BLEM
 SG_ FobCtlPssvData_No_Actl : 7|40@0+ (1,0) [0|1099511627775] "Encrypted"  GENERIC,_delete,RFA_BLEM

BO_ 1118 LocationServices_Data1_FD2: 8 GWM
 SG_ LocationServices_1 : 7|64@0+ (1,0) [0|1.84467440737096E+019] "unitless"  GENERIC,TCU,RFA_BLEM

BO_ 592 RFA_BLEM_APIM_Tx: 8 RFA_BLEM
 SG_ RFA_BLEM_APIM_Tx : 7|64@0+ (1,0) [0|1.84467440737096E+019] "unitless"  GENERIC,GWM

BO_ 895 RemoteParkAssistReq: 16 RFA_BLEM
 SG_ TurnLght_D_RqRmtCtl : 1|2@0+ (1,0) [0|3] "SED"  GENERIC,GWM
 SG_ RmtCtlRngSet_D_Rq : 3|2@0+ (1,0) [0|3] "SED"  GENERIC,GWM
 SG_ RmtCtlRes_D_Stat : 31|40@0+ (1,0) [0|1099511627775] "unitless"  GENERIC,GWM
 SG_ RmtCtlKeyPoll_D_Rq : 18|2@0+ (1,0) [0|3] "SED"  GENERIC,GWM
 SG_ RmtCtlDStat_No_Cs : 15|8@0+ (1,0) [0|255] "unitless"  GENERIC,GWM
 SG_ RmtCtlDStat_No_Cnt : 23|4@0+ (1,0) [0|15] "unitless"  GENERIC,GWM
 SG_ RmtCtlCntnsIn_B_Stat : 19|1@0+ (1,0) [0|1] "SED"  GENERIC,GWM
 SG_ RmtCtl_D_Stat : 7|4@0+ (1,0) [0|15] "SED"  GENERIC,GWM

BO_ 1416 RFA_AutoSar_NetworkMgmt: 8 RFA_BLEM
 SG_ RFA_GWOnBoardTester : 39|8@0+ (1,0) [0|255] "unitless"  GENERIC
 SG_ RFA_GWNMProxy : 47|8@0+ (1,0) [0|255] "unitless"  GENERIC
 SG_ RFA_AutoSarNMReserved4 : 63|8@0+ (1,0) [0|255] "unitless"  GENERIC
 SG_ RFA_AutoSarNMReserved3 : 55|8@0+ (1,0) [0|255] "unitless"  GENERIC
 SG_ RFA_AutoSarNMReserved2 : 31|8@0+ (1,0) [0|255] "unitless"  GENERIC
 SG_ RFA_AutoSarNMReserved1 : 23|8@0+ (1,0) [0|255] "unitless"  GENERIC
 SG_ RFA_AutoSarNMNodeId : 7|8@0+ (1,0) [0|255] "unitless"  GENERIC
 SG_ RFA_AutoSarNMControl : 15|8@0+ (1,0) [0|255] "unitless"  GENERIC

BO_ 1849 TesterPhysicalResRFA_FD2: 64 RFA_BLEM
 SG_ TesterPhysicalResRFA : 7|64@0+ (1,0) [0|1.84467E+019] "unitless"  GENERIC,TSTR

BO_ 624 PaakCtlData6: 8 RFA_BLEM
 SG_ PaakAddEraseIndx_No_Rq : 5|6@0+ (1,0) [0|63] "unitless"  GENERIC,GWM
 SG_ PaakAddErase_D_Rq : 7|2@0+ (1,0) [0|3] "SED"  GENERIC,GWM

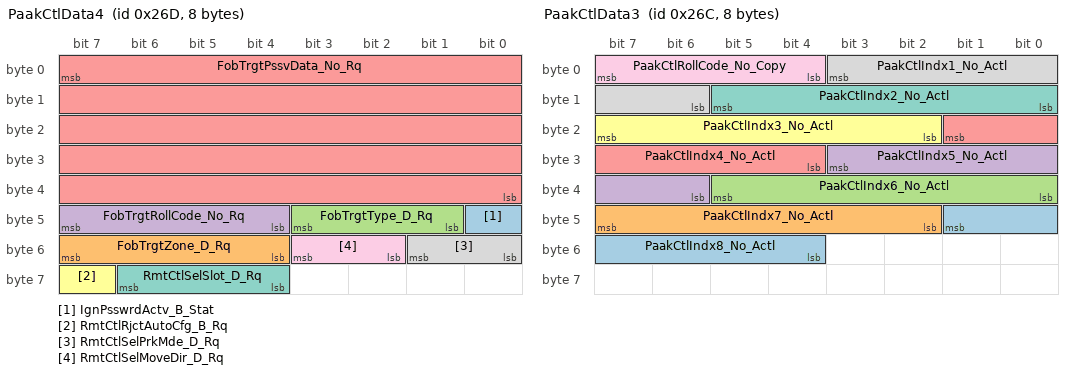
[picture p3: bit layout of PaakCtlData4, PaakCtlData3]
BO_ 621 PaakCtlData4: 8 RFA_BLEM
 SG_ IgnPsswrdActv_B_Stat : 40|1@0+ (1,0) [0|1] "SED"  GENERIC,GWM
 SG_ FobTrgtZone_D_Rq : 55|4@0+ (1,0) [0|15] "SED"  GENERIC,GWM
 SG_ FobTrgtType_D_Rq : 43|3@0+ (1,0) [0|7] "SED"  GENERIC,GWM
 SG_ FobTrgtRollCode_No_Rq : 47|4@0+ (1,0) [0|15] "unitless"  GENERIC,GWM
 SG_ FobTrgtPssvData_No_Rq : 7|40@0+ (1,0) [0|1099511627775] "Encrypted"  GENERIC,GWM
 SG_ RmtCtlRjctAutoCfg_B_Rq : 63|1@0+ (1,0) [0|1] "SED"  GENERIC,_delete,GWM
 SG_ RmtCtlSelSlot_D_Rq : 62|3@0+ (1,0) [0|7] "SED"  GENERIC,_delete,GWM
 SG_ RmtCtlSelPrkMde_D_Rq : 49|2@0+ (1,0) [0|3] "SED"  GENERIC,_delete,GWM
 SG_ RmtCtlSelMoveDir_D_Rq : 51|2@0+ (1,0) [0|3] "SED"  GENERIC,_delete,GWM

BO_ 620 PaakCtlData3: 8 RFA_BLEM
 SG_ PaakCtlIndx8_No_Actl : 41|6@0+ (1,0) [0|63] "unitless"  GENERIC,GWM
 SG_ PaakCtlIndx7_No_Actl : 47|6@0+ (1,0) [0|63] "unitless"  GENERIC,GWM
 SG_ PaakCtlIndx6_No_Actl : 37|6@0+ (1,0) [0|63] "unitless"  GENERIC,GWM
 SG_ PaakCtlIndx5_No_Actl : 27|6@0+ (1,0) [0|63] "unitless"  GENERIC,GWM
 SG_ PaakCtlIndx4_No_Actl : 17|6@0+ (1,0) [0|63] "unitless"  GENERIC,GWM
 SG_ PaakCtlIndx3_No_Actl : 23|6@0+ (1,0) [0|63] "unitless"  GENERIC,GWM
 SG_ PaakCtlIndx2_No_Actl : 13|6@0+ (1,0) [0|63] "unitless"  GENERIC,GWM
 SG_ PaakCtlIndx1_No_Actl : 3|6@0+ (1,0) [0|63] "unitless"  GENERIC,GWM
 SG_ PaakCtlRollCode_No_Copy : 7|4@0+ (1,0) [0|15] "unitless"  GENERIC,GWM

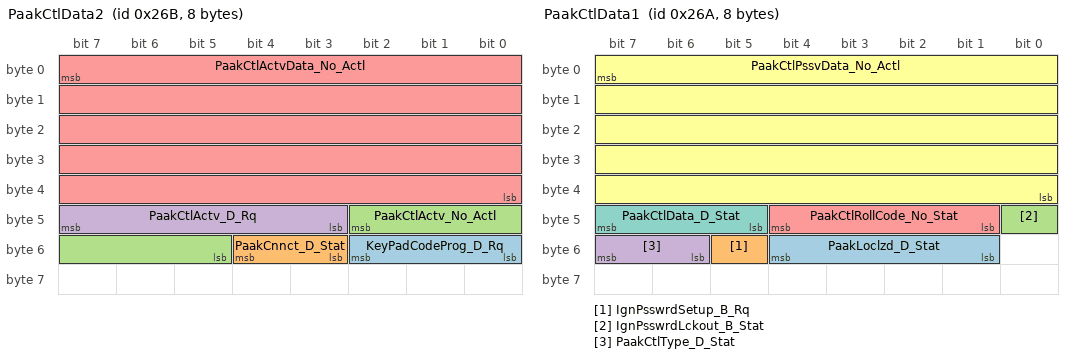
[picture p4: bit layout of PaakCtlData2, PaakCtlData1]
BO_ 619 PaakCtlData2: 8 RFA_BLEM
 SG_ KeyPadCodeProg_D_Rq : 50|3@0+ (1,0) [0|7] "SED"  GENERIC,GWM
 SG_ PaakCnnct_D_Stat : 52|2@0+ (1,0) [0|3] "SED"  GENERIC,GWM
 SG_ PaakCtlActv_No_Actl : 42|6@0+ (1,0) [0|63] "unitless"  GENERIC,GWM
 SG_ PaakCtlActv_D_Rq : 47|5@0+ (1,0) [0|31] "SED"  GENERIC,GWM
 SG_ PaakCtlActvData_No_Actl : 7|40@0+ (1,0) [0|1099511627775] "unitless"  GENERIC,GWM

BO_ 618 PaakCtlData1: 8 RFA_BLEM
 SG_ PaakLoclzd_D_Stat : 52|4@0+ (1,0) [0|15] "SED"  GENERIC,GWM
 SG_ IgnPsswrdSetup_B_Rq : 53|1@0+ (1,0) [0|1] "SED"  GENERIC,GWM
 SG_ IgnPsswrdLckout_B_Stat : 40|1@0+ (1,0) [0|1] "SED"  GENERIC,GWM
 SG_ PaakCtlType_D_Stat : 55|2@0+ (1,0) [0|3] "SED"  GENERIC,GWM
 SG_ PaakCtlRollCode_No_Stat : 44|4@0+ (1,0) [0|15] "unitless"  GENERIC,GWM
 SG_ PaakCtlPssvData_No_Actl : 7|40@0+ (1,0) [0|1099511627775] "unitless"  GENERIC,GWM
 SG_ PaakCtlData_D_Stat : 47|3@0+ (1,0) [0|7] "SED"  GENERIC,GWM

BO_ 154 TripResetSyncMessage_FD2: 12 GWM
 SG_ TronTripCnt_No_Actl : 7|23@0+ (1,0) [0|8388605] "unitless"  GENERIC,TCU,RFA_BLEM
 SG_ TronResetCnt_No_Actl : 16|22@0+ (1,0) [0|4194301] "unitless"  GENERIC,TCU,RFA_BLEM

BO_ 2614099160 SymKeyFuncGWM_ECG_FD2: 64 GWM
 SG_ SymKeyFuncGWM_ECG : 7|29@0+ (1,0) [0|536870911] "unitless"  GENERIC,RFA_BLEM,TCU

BO_ 2613272721 SymKeyPhysTCUtoGWM_ECG: 64 TCU
 SG_ SymKeyPhysTCUtoGWM_ECG : 7|29@0+ (1,0) [0|536870911] "unitless"  GENERIC,GWM

BO_ 2613200088 SymKeyPhysGWM_ECGtoTCU: 64 GWM
 SG_ SymKeyPhysGWM_ECGtoTCU : 7|29@0+ (1,0) [0|536870911] "unitless"  GENERIC,TCU

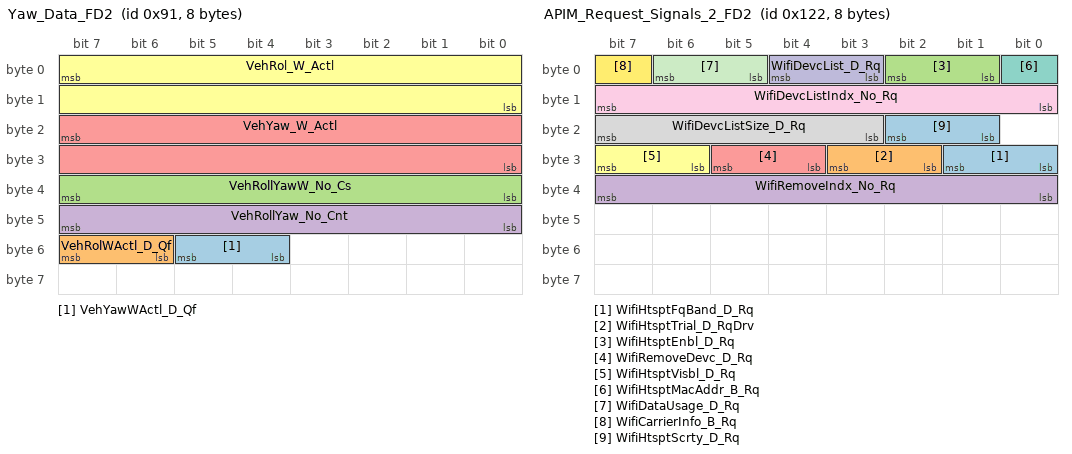
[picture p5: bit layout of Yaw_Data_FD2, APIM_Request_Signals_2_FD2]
BO_ 145 Yaw_Data_FD2: 8 GWM
 SG_ VehYawWActl_D_Qf : 53|2@0+ (1,0) [0|3] "SED"  GENERIC,TCU
 SG_ VehRolWActl_D_Qf : 55|2@0+ (1,0) [0|3] "SED"  GENERIC,_delete
 SG_ VehRollYawW_No_Cs : 39|8@0+ (1,0) [0|255] "unitless"  GENERIC,_delete
 SG_ VehRollYaw_No_Cnt : 47|8@0+ (1,0) [0|255] "unitless"  GENERIC,TCU
 SG_ VehYaw_W_Actl : 23|16@0+ (0.0002,-6.5) [-6.5|6.6066] "rad/s"  GENERIC,TCU
 SG_ VehRol_W_Actl : 7|16@0+ (0.0002,-6.5) [-6.5|6.6066] "rad/s"  GENERIC,_delete,TCU

BO_ 1090 MtrTrac_Data2_FD2: 16 GWM
 SG_ VehElRnge_L_Dsply : 28|12@0+ (0.1,0) [0|409.3] "kilometer"  GENERIC,TCU
 SG_ Mtr2State_D_ActlMntr : 31|3@0+ (1,0) [0|7] "SED"  GENERIC,_delete
 SG_ Inv1Ain_I_ActlMntr : 7|15@0+ (0.1,-1000) [-1000|2276.5] "ampere"  GENERIC,_delete
 SG_ HybVehMde_D_ActlMntr : 20|3@0+ (1,0) [0|7] "SED"  GENERIC,_delete
 SG_ ChrgStat_D_ActlMntr : 23|3@0+ (1,0) [0|7] "SED"  GENERIC,_delete
 SG_ MtrTotNum_No_ActlMntr : 63|3@0+ (1,0) [0|7] "unitless"  GENERIC,_delete

BO_ 2612224145 PARSEDPushTCUtoGWM_ECG: 8 TCU
 SG_ PARSEDPushTCUtoGWM_ECG : 7|29@0+ (1,0) [0|536870911] "unitless"  GENERIC,_delete,GWM

BO_ 1192 APIM_TCU_Word_Tx_FD2: 8 GWM
 SG_ APIM_TCU_Word_Tx : 7|64@0+ (1,0) [0|1.84467440737096E+019] "unitless"  GENERIC,TCU

BO_ 2611175569 PARSEDPhysTCUtoGWM_ECG: 64 TCU
 SG_ PARSEDPhysTCUtoGWM_ECG : 7|29@0+ (1,0) [0|536870911] "unitless"  GENERIC,_delete,GWM

BO_ 2611102936 PARSEDPhysGWM_ECGtoTCU: 64 GWM
 SG_ PARSEDPhysGWM_ECGtoTCU : 7|29@0+ (1,0) [0|536870911] "unitless"  GENERIC,TCU

BO_ 2610126993 OTAPhysTCUtoGWM_ECG: 64 TCU
 SG_ OTAPhysTCUtoGWM_ECG : 7|29@0+ (1,0) [0|536870911] "unitless"  GENERIC,_delete,GWM

BO_ 2610054360 OTAPhysGWM_ECGtoTCU: 64 GWM
 SG_ OTAPhysGWM_ECGtoTCU : 7|29@0+ (1,0) [0|536870911] "unitless"  GENERIC,TCU

BO_ 589 TRAFFIC_RDISP_WORD_Rx_FD2: 8 GWM
 SG_ TRAFFIC_RDISP_WORD_Rx : 7|64@0+ (1,0) [0|1.84467440737096E+019] "unitless"  GENERIC,TCU,_delete

BO_ 2612151512 PARSEDPushFcGWM_ECGtoTCU: 8 GWM
 SG_ PARSEDPushFcGWM_ECGtoTCU : 7|29@0+ (1,0) [0|536870911] "unitless"  GENERIC,TCU

BO_ 945 Body_Info_7_FD2: 16 GWM
 SG_ PaseKeySearch_Stat : 62|1@0+ (1,0) [0|1] "SED"  GENERIC
 SG_ DelvrAsstMsgTxt_D_Rq : 51|4@0+ (1,0) [0|15] "SED"  GENERIC
 SG_ AdasRelay_B_Stat2 : 35|1@0+ (1,0) [0|1] "SED"  GENERIC
 SG_ StrtrMtrCtlMsgTxt_D_Rq2 : 55|4@0+ (1,0) [0|15] "SED"  GENERIC,_delete
 SG_ PrkLckCtlMsgTxt_D2_Rq : 2|3@0+ (1,0) [0|7] "SED"  GENERIC
 SG_ PwLoApim_T_Actl : 34|11@0+ (1,0) [0|2047] "minute"  GENERIC,_delete
 SG_ KeyOffMde_D_Actl : 7|4@0+ (1,0) [0|15] "SED"  GENERIC,RFA_BLEM,TCU
 SG_ PrkLckCtlLatch_B_Rq : 3|1@0+ (1,0) [0|1] "SED"  GENERIC
 SG_ KeyPadCodeDgt7_D_Dsply : 39|4@0+ (1,0) [0|15] "SED"  GENERIC
 SG_ KeyPadCodeDgt6_D_Dsply : 27|4@0+ (1,0) [0|15] "SED"  GENERIC
 SG_ KeyPadCodeDgt5_D_Dsply : 31|4@0+ (1,0) [0|15] "SED"  GENERIC
 SG_ KeyPadCodeDgt4_D_Dsply : 19|4@0+ (1,0) [0|15] "SED"  GENERIC
 SG_ KeyPadCodeDgt3_D_Dsply : 23|4@0+ (1,0) [0|15] "SED"  GENERIC
 SG_ KeyPadCodeDgt2_D_Dsply : 11|4@0+ (1,0) [0|15] "SED"  GENERIC
 SG_ KeyPadCodeDgt1_D_Dsply : 15|4@0+ (1,0) [0|15] "SED"  GENERIC

BO_ 290 APIM_Request_Signals_2_FD2: 8 GWM
 SG_ WifiHtsptFqBand_D_Rq : 25|2@0+ (1,0) [0|3] "SED"  GENERIC,TCU
 SG_ WifiHtsptTrial_D_RqDrv : 27|2@0+ (1,0) [0|3] "SED"  GENERIC,TCU
 SG_ WifiHtsptEnbl_D_Rq : 2|2@0+ (1,0) [0|3] "SED"  GENERIC,TCU
 SG_ WifiRemoveIndx_No_Rq : 39|8@0+ (1,0) [0|255] "unitless"  GENERIC,TCU
 SG_ WifiRemoveDevc_D_Rq : 29|2@0+ (1,0) [0|3] "SED"  GENERIC,TCU
 SG_ WifiHtsptVisbl_D_Rq : 31|2@0+ (1,0) [0|3] "SED"  GENERIC,TCU
 SG_ WifiHtsptMacAddr_B_Rq : 0|1@0+ (1,0) [0|1] "SED"  GENERIC,TCU
 SG_ WifiDevcListSize_D_Rq : 23|5@0+ (1,0) [0|31] "unitless"  GENERIC,TCU
 SG_ WifiDevcListIndx_No_Rq : 15|8@0+ (1,0) [0|255] "unitless"  GENERIC,TCU
 SG_ WifiDevcList_D_Rq : 4|2@0+ (1,0) [0|3] "SED"  GENERIC,TCU
 SG_ WifiDataUsage_D_Rq : 6|2@0+ (1,0) [0|3] "SED"  GENERIC,TCU
 SG_ WifiCarrierInfo_B_Rq : 7|1@0+ (1,0) [0|1] "SED"  GENERIC,TCU
 SG_ WifiHtsptScrty_D_Rq : 18|2@0+ (1,0) [0|3] "SED"  GENERIC,TCU

BO_ 542 LocationServices_3: 8 TCU
 SG_ LocationServices_3 : 7|64@0+ (1,0) [0|1.84467440737096E+019] "unitless"  GENERIC,RFA_BLEM,GWM

BO_ 636 TCU_Send_Signals_3: 8 TCU
 SG_ WifiHtsptFqBand_D_Stat : 60|2@0+ (1,0) [0|3] "SED"  GENERIC,GWM
 SG_ WifiHtspt_D_Falt : 51|4@0+ (1,0) [0|15] "SED"  GENERIC,GWM
 SG_ WifiNoDevcCnnct_No_Actl : 47|8@0+ (1,0) [0|255] "unitless"  GENERIC,GWM
 SG_ WifiHtsptCnnct_D_Stat : 26|2@0+ (1,0) [0|3] "SED"  GENERIC,GWM
 SG_ Telematics_D_Falt : 39|3@0+ (1,0) [0|7] "SED"  GENERIC,GWM
 SG_ WifiEnbl_D_Stat : 4|2@0+ (1,0) [0|3] "SED"  GENERIC,GWM
 SG_ WifiHtsptVisbl_D_Stat : 13|2@0+ (1,0) [0|3] "SED"  GENERIC,GWM
 SG_ WifiHtsptScrty_D_Stat : 15|2@0+ (1,0) [0|3] "SED"  GENERIC,GWM
 SG_ WifiHtsptEnbl_D_Stat : 2|2@0+ (1,0) [0|3] "SED"  GENERIC,GWM
 SG_ WifiDevcListNew_B_Stat : 5|1@0+ (1,0) [0|1] "SED"  GENERIC,GWM
 SG_ WifiDataUsage_Pc_Actl : 20|4@0+ (5,50) [50|125] "percent"  GENERIC,GWM
 SG_ WifiDataUsage_D_Stat : 7|2@0+ (1,0) [0|3] "SED"  GENERIC,GWM
 SG_ ModemSigStren_D_Stat : 11|3@0+ (1,0) [0|7] "SED"  GENERIC,GWM
 SG_ WifiHtsptCrdntl_B_Stat : 0|1@0+ (1,0) [0|1] "SED"  GENERIC,GWM
 SG_ WifiHtsptFq_D_Avail : 63|3@0+ (1,0) [0|7] "SED"  GENERIC,GWM
 SG_ WifiDataUsageOn_D_Stat : 28|2@0+ (1,0) [0|3] "SED"  GENERIC,GWM
 SG_ ModemTechnology_D2_Stat : 31|3@0+ (1,0) [0|7] "SED"  GENERIC,GWM

BO_ 1087 Powertrain_Data_5_FD2: 16 GWM
 SG_ CrnkInhbtActv_B_Stat : 11|1@0+ (1,0) [0|1] "SED"  GENERIC
 SG_ CrnkInhbtHlthRate_B_Rq : 10|1@0+ (1,0) [0|1] "SED"  GENERIC,TCU
 SG_ TrlrRngeDsply_B_Stat : 16|1@0+ (1,0) [0|1] "SED"  GENERIC
 SG_ StopStrtImccTxt_D_Dspl : 63|4@0+ (1,0) [0|15] "SED"  GENERIC
 SG_ StopStrtImccTxt_D_Rq : 55|3@0+ (1,0) [0|7] "SED"  GENERIC
 SG_ StopStrtImccActv_D_St : 52|3@0+ (1,0) [0|7] "SED"  GENERIC
 SG_ EngIdlShutDownT_D_Stat : 47|8@0+ (1,0) [0|255] "SED"  GENERIC
 SG_ StopStrtCstm_D_Stat : 26|2@0+ (1,0) [0|3] "SED"  GENERIC,_delete
 SG_ SelDrvMdeCstmPt_D_Stat : 31|5@0+ (1,0) [0|31] "SED"  GENERIC,_delete
 SG_ RepaLcGrdInhbt_B_Stat : 17|1@0+ (1,0) [0|1] "SED"  GENERIC,_delete,RFA_BLEM
 SG_ FapLcInhbt_B_Rq : 1|1@0+ (1,0) [0|1] "SED"  GENERIC,_delete
 SG_ StrtInGearMsgTxt_D_Rq : 23|4@0+ (1,0) [0|15] "SED"  GENERIC,_delete
 SG_ IgnOffInhbt_B_Stat : 9|1@0+ (1,0) [0|1] "SED"  GENERIC,_delete
 SG_ FapLcStopHold_B_Rq : 2|1@0+ (1,0) [0|1] "SED"  GENERIC,_delete
 SG_ FapLcPrchgBrk_B_Rq : 3|1@0+ (1,0) [0|1] "SED"  GENERIC,_delete
 SG_ FapLcObstcl_B_Stat : 4|1@0+ (1,0) [0|1] "SED"  GENERIC,_delete
 SG_ FapLcMaxGrdInhbt_B_Stat : 5|1@0+ (1,0) [0|1] "SED"  GENERIC,_delete
 SG_ FapLcMaxGrdAbrt_B_Stat : 6|1@0+ (1,0) [0|1] "SED"  GENERIC,_delete,RFA_BLEM
 SG_ FapLcActv_B_Stat : 7|1@0+ (1,0) [0|1] "SED"  GENERIC,_delete,RFA_BLEM
 SG_ BattRgenLoDChrg_D_RqEng : 13|2@0+ (1,0) [0|3] "SED"  GENERIC,_delete
 SG_ BattRgenLoChrg_D_RqEng : 15|2@0+ (1,0) [0|3] "SED"  GENERIC,_delete
 SG_ AdasLcObtclAbrt_B_Stat : 0|1@0+ (1,0) [0|1] "SED"  GENERIC,_delete,RFA_BLEM

BO_ 831 Pass_Mirror_Sw_StatM_FD2: 16 GWM
 SG_ MirrorTelescopic_D_Rq : 9|2@0+ (1,0) [0|3] "SED"  GENERIC,RFA_BLEM
 SG_ RearPassWindowLockCmd : 0|1@0+ (1,0) [0|1] "SED"  GENERIC,_delete
 SG_ RearPassWindowCmd : 20|3@0+ (1,0) [0|7] "SED"  GENERIC,_delete
 SG_ PassWindowCmd : 12|3@0+ (1,0) [0|7] "SED"  GENERIC,_delete
 SG_ PassMirrorCmd : 15|3@0+ (1,0) [0|7] "SED"  GENERIC,_delete
 SG_ DipMirrorPosPassenger : 4|1@0+ (1,0) [0|1] "SED"  GENERIC,_delete
 SG_ ActiveStoragePassenger : 7|3@0+ (1,0) [0|7] "SED"  GENERIC,_delete
 SG_ RearDriverWindowPos : 23|3@0+ (1,0) [0|7] "SED"  GENERIC,_delete
 SG_ DriverWindowPosition : 3|3@0+ (1,0) [0|7] "SED"  GENERIC

CM_ SG_ 985 LongCtrlEnblDRq_No_Cs "Signal not transmitted on gas and diesel variants.";
CM_ SG_ 985 LongCtrlEnblDRq_No_Cnt "Signal not transmitted on gas and diesel variants.";
CM_ SG_ 942 PrkAidRdiusRight_L_Dsply "MSGDCR 679, set all signals to OnChange";
CM_ SG_ 942 PrkAidRdiusLeft_L_Dsply "MSGDCR 679, set all signals to OnChange";
CM_ SG_ 942 PrkAidDrvDir_D_Stat "MSGDCR 679, set all signals to OnChange";
CM_ BO_ 948 "$3B4 used by CGEA SPDJB";
CM_ BO_ 932 "NOTE: START BITS 8-11 MUST BE OPEN SPEC REQUIREMENT";
CM_ SG_ 932 CanMsg3A4_No_Crc "Signal not transmitted on gas and HEV variants.";
CM_ SG_ 932 CanMsg3A4_No_Cnt "Signal not transmitted on gas and HEV variants.";
CM_ SG_ 118 SteWhlCompAnEst_D_Qf "Legacy signal not supported, reserving bit locations for commodity BCM, PAM, RCM, APIM dbc files.  GWM to Tx Init value, no valid data. ";
CM_ SG_ 118 SteWhlComp_An_Est "Legacy signal not supported, reserving bit locations for commodity BCM, PAM, RCM, APIM dbc files.  GWM to Tx Init value, no valid data. ";
CM_ SG_ 947 Dimming_Lvl "Refer to Vehicle Interior Illum Dimming Ctrl Sys Eng Spec, Table 2

";
CM_ SG_ 947 PrkBrkActv_B_Actl "Signal not transmitted on vehicles with electric park brake. ";
CM_ SG_ 126 StePinRelInit_An_Sns "SASM will transmit these signals on vehicles with SASM and without PSCM.  SCCM will not Tx this signal when SASM is present.";
CM_ SG_ 126 StePinAn_No_Cs "Signal not transmitted on gas variants.";
CM_ SG_ 357 BpedDrvAppl_D_Actl "CCMGenSigTimeoutTime=1000";
CM_ SG_ 357 CcStat_D_Actl "ABSGenSigTimeoutTime=1000";
CM_ SG_ 357 AccStopMde_D_Rq "ABSGenSigTimeoutTime=1000";
CM_ BO_ 651 "TCU CPPM Tx";
CM_ SG_ 261 OffPeakTimeSetType_Rq "Object:OffPeakTimeSet_Rq";
CM_ BO_ 600 "Tx by HS3 APIM";
CM_ SG_ 600 APIM_RFA_BLEM_Tx "Tx by HS3 APIM";
CM_ SG_ 616 PaakTrgtPssvData_No_Rq "Not transmitted on all vehicle variants";
CM_ SG_ 617 PaakTrgtActvData_No_Rq "Not transmitted on all vehicle variants";
CM_ SG_ 1119 LocationServices_2 "Tx by HS3 APIM";
CM_ SG_ 1118 LocationServices_1 "Tx by HS3 APIM";
CM_ SG_ 619 PaakCtlActvData_No_Actl "Not transmitted on all vehicle variants";
CM_ SG_ 618 IgnPsswrdSetup_B_Rq "ABSGenSigTimeoutTime=1000";
CM_ SG_ 618 IgnPsswrdLckout_B_Stat "ABSGenSigTimeoutTime=1000";
CM_ SG_ 618 PaakCtlPssvData_No_Actl "Not transmitted on all vehicle variants";
CM_ SG_ 145 VehYaw_W_Actl "CCMGenSigTimeoutTime=1000";
CM_ BO_ 1192 "TP message";
CM_ SG_ 1192 APIM_TCU_Word_Tx "Tx by HS3 APIM";
CM_ SG_ 542 LocationServices_3 "Tx by HS3 APIM";
BA_DEF_ BO_  "VFrameFormat" ENUM  "StandardCAN","ExtendedCAN","reserved","reserved","reserved","reserved","reserved","reserved","reserved","reserved","reserved","reserved","reserved","reserved","StandardCAN_FD","ExtendedCAN_FD";
BA_DEF_ BO_  "FrameRouting" STRING ;
BA_DEF_ BO_  "NetworkInitialization" ENUM  "No","Yes";
BA_DEF_ BO_  "GenMsgStartDelayTime" INT 0 10000;
BA_DEF_ BO_  "GenMsgNrOfRepetition" INT 0 100;
BA_DEF_ BO_  "GenMsgDelayTime" INT 0 1000;
BA_DEF_ BO_  "GenMsgCycleTime" INT 0 100000;
BA_DEF_ BO_  "GenMsgSendType" ENUM  "FixedPeriodic","Event","EnabledPeriodic","NotUsed","NotUsed","EventPeriodic","NotUsed","NotUsed","NoMsgSendType";
BA_DEF_ SG_  "U_P702_MY2024_Tx" ENUM  "No","Yes";
BA_DEF_ SG_  "U_V710_MY2023_Tx" ENUM  "No","Yes";
BA_DEF_ SG_  "U_CDX74X_MY2024_Tx" ENUM  "No","Yes";
BA_DEF_ SG_  "U_CDX707_MY2023_Tx" ENUM  "No","Yes";
BA_DEF_ SG_  "U_P708_MY2023_Tx" ENUM  "No","Yes";
BA_DEF_ SG_  "U_V713AV_MY2022_Tx" ENUM  "No","Yes";
BA_DEF_ SG_  "U_V713N_MY2022_Tx" ENUM  "No","Yes";
BA_DEF_ SG_  "ECGUsedTxSignal" ENUM  "No","Yes";
BA_DEF_ SG_  "U_P702_MY2024_Rx" ENUM  "No","Yes";
BA_DEF_ SG_  "U_V710_MY2023_Rx" ENUM  "No","Yes";
BA_DEF_ SG_  "U_CDX74X_MY2024_Rx" ENUM  "No","Yes";
BA_DEF_ SG_  "U_CDX707_MY2023_Rx" ENUM  "No","Yes";
BA_DEF_ SG_  "U_P708_MY2023_Rx" ENUM  "No","Yes";
BA_DEF_ SG_  "U_V713AV_MY2022_Rx" ENUM  "No","Yes";
BA_DEF_ SG_  "U_V713N_MY2022_Rx" ENUM  "No","Yes";
BA_DEF_ SG_  "ECGUsedRxSignal" ENUM  "No","Yes";
BA_DEF_ SG_  "UsedOnPgmDBC" ENUM  "No","Yes";
BA_DEF_ SG_  "ContentDependant" ENUM  "No","Yes";
BA_DEF_ SG_  "GenSigStartValue" HEX 0 268435455;
BA_DEF_ SG_  "MetaData" ENUM  "No","Yes";
BA_DEF_ SG_  "WakeupSignal" ENUM  "No","Yes";
BA_DEF_ SG_  "GenSigInactiveValue" INT 0 100000;
BA_DEF_ SG_  "GenSigSendType" ENUM  "Cyclic","OnWrite","vector_leerstring","OnChange","vector_leerstring","IfActive","vector_leerstring","NoSigSendType";
BA_DEF_ BO_  "TpTxIndex" INT 0 536870911;
BA_DEF_ BO_  "OvtpPushApplication" ENUM  "FALSE","TRUE";
BA_DEF_ BO_  "SCP_FreshnessValueLength" INT 0 512;
BA_DEF_ BO_  "SCP_DataId" INT 0 17663;
BA_DEF_ BO_  "SCP_FreshnessValueTxLength" INT 0 512;
BA_DEF_ BO_  "SCP_AuthInfoTxLength" INT 0 512;
BA_DEF_ BO_  "SC_Message" ENUM  "No","Yes";
BA_DEF_ BO_  "GenMsgRoutingTimeoutTime" INT 0 5000;
BA_DEF_ BO_  "NmAsrMessage" ENUM  "No","Yes";
BA_DEF_ BO_  "DiagState" ENUM  "No","Yes";
BA_DEF_ BO_  "DiagRequest" ENUM  "No","Yes";
BA_DEF_ BO_  "DiagResponse" ENUM  "No","Yes";
BA_DEF_ BO_  "GenMsgILSupport" ENUM  "No","Yes";
BA_DEF_REL_ BU_SG_REL_  "SC_Verification" ENUM  "No","Yes";
BA_DEF_DEF_  "VFrameFormat" "ExtendedCAN_FD";
BA_DEF_DEF_  "FrameRouting" "";
BA_DEF_DEF_  "NetworkInitialization" "Yes";
BA_DEF_DEF_  "GenMsgStartDelayTime" 0;
BA_DEF_DEF_  "GenMsgNrOfRepetition" 1;
BA_DEF_DEF_  "GenMsgDelayTime" 20;
BA_DEF_DEF_  "GenMsgCycleTime" 0;
BA_DEF_DEF_  "GenMsgSendType" "NoMsgSendType";
BA_DEF_DEF_  "U_P702_MY2024_Tx" "No";
BA_DEF_DEF_  "U_V710_MY2023_Tx" "No";
BA_DEF_DEF_  "U_CDX74X_MY2024_Tx" "No";
BA_DEF_DEF_  "U_CDX707_MY2023_Tx" "No";
BA_DEF_DEF_  "U_P708_MY2023_Tx" "No";
BA_DEF_DEF_  "U_V713AV_MY2022_Tx" "No";
BA_DEF_DEF_  "U_V713N_MY2022_Tx" "No";
BA_DEF_DEF_  "ECGUsedTxSignal" "No";
BA_DEF_DEF_  "U_P702_MY2024_Rx" "No";
BA_DEF_DEF_  "U_V710_MY2023_Rx" "No";
BA_DEF_DEF_  "U_CDX74X_MY2024_Rx" "No";
BA_DEF_DEF_  "U_CDX707_MY2023_Rx" "No";
BA_DEF_DEF_  "U_P708_MY2023_Rx" "No";
BA_DEF_DEF_  "U_V713AV_MY2022_Rx" "No";
BA_DEF_DEF_  "U_V713N_MY2022_Rx" "No";
BA_DEF_DEF_  "ECGUsedRxSignal" "No";
BA_DEF_DEF_  "UsedOnPgmDBC" "Yes";
BA_DEF_DEF_  "ContentDependant" "No";
BA_DEF_DEF_  "GenSigStartValue" 0;
BA_DEF_DEF_  "MetaData" "No";
BA_DEF_DEF_  "WakeupSignal" "No";
BA_DEF_DEF_  "GenSigInactiveValue" 0;
BA_DEF_DEF_  "GenSigSendType" "NoSigSendType";
BA_DEF_DEF_  "TpTxIndex" 0;
BA_DEF_DEF_  "OvtpPushApplication" "FALSE";
BA_DEF_DEF_  "SCP_FreshnessValueLength" 64;
BA_DEF_DEF_  "SCP_DataId" 0;
BA_DEF_DEF_  "SCP_FreshnessValueTxLength" 11;
BA_DEF_DEF_  "SCP_AuthInfoTxLength" 53;
BA_DEF_DEF_  "SC_Message" "No";
BA_DEF_DEF_  "GenMsgRoutingTimeoutTime" 0;
BA_DEF_DEF_  "NmAsrMessage" "No";
BA_DEF_DEF_  "DiagState" "No";
BA_DEF_DEF_  "DiagRequest" "No";
BA_DEF_DEF_  "DiagResponse" "No";
BA_DEF_DEF_  "GenMsgILSupport" "Yes";
BA_DEF_DEF_REL_ "SC_Verification" "No";
BA_ "SC_Message" BO_ 966 1;
BA_ "SCP_DataId" BO_ 966 5062;
BA_ "FrameRouting" BO_ 966 "FD1_CAN,0x3C6;";
BA_ "VFrameFormat" BO_ 966 14;
BA_ "SC_Message" BO_ 119 1;
BA_ "SCP_DataId" BO_ 119 4215;
BA_ "FrameRouting" BO_ 119 "FD1_CAN,0x77;";
BA_ "VFrameFormat" BO_ 119 14;
BA_ "SC_Message" BO_ 517 1;
BA_ "SCP_DataId" BO_ 517 4613;
BA_ "FrameRouting" BO_ 517 "FD1_CAN,0x205;";
BA_ "VFrameFormat" BO_ 517 14;
BA_ "SC_Message" BO_ 985 1;
BA_ "SCP_DataId" BO_ 985 5081;
BA_ "FrameRouting" BO_ 985 "FD3_CAN,0x3D9";
BA_ "VFrameFormat" BO_ 985 14;
BA_ "GenMsgILSupport" BO_ 1927 0;
BA_ "DiagRequest" BO_ 1927 1;
BA_ "GenMsgSendType" BO_ 1927 1;
BA_ "GenMsgDelayTime" BO_ 1927 0;
BA_ "NetworkInitialization" BO_ 1927 0;
BA_ "VFrameFormat" BO_ 1927 14;
BA_ "SC_Message" BO_ 942 1;
BA_ "SCP_DataId" BO_ 942 5038;
BA_ "FrameRouting" BO_ 942 "FD3_CAN,0x3AE";
BA_ "VFrameFormat" BO_ 942 14;
BA_ "GenMsgILSupport" BO_ 1734 0;
BA_ "DiagRequest" BO_ 1734 1;
BA_ "GenMsgSendType" BO_ 1734 1;
BA_ "GenMsgDelayTime" BO_ 1734 0;
BA_ "NetworkInitialization" BO_ 1734 0;
BA_ "VFrameFormat" BO_ 1734 14;
BA_ "GenMsgSendType" BO_ 367 5;
BA_ "GenMsgCycleTime" BO_ 367 1000;
BA_ "VFrameFormat" BO_ 367 14;
BA_ "GenMsgSendType" BO_ 1203 5;
BA_ "GenMsgCycleTime" BO_ 1203 1000;
BA_ "VFrameFormat" BO_ 1203 14;
BA_ "SC_Message" BO_ 948 1;
BA_ "SCP_DataId" BO_ 948 9140;
BA_ "FrameRouting" BO_ 948 "FD1_CAN,0x3B4;";
BA_ "VFrameFormat" BO_ 948 14;
BA_ "FrameRouting" BO_ 131 "HS2_CAN,0x83;";
BA_ "VFrameFormat" BO_ 131 14;
BA_ "SC_Message" BO_ 963 1;
BA_ "SCP_DataId" BO_ 963 5059;
BA_ "FrameRouting" BO_ 963 "FD1_CAN,0x3C3;";
BA_ "VFrameFormat" BO_ 963 14;
BA_ "GenMsgSendType" BO_ 908 5;
BA_ "GenMsgCycleTime" BO_ 908 1000;
BA_ "VFrameFormat" BO_ 908 14;
BA_ "TpTxIndex" BO_ 2609983704 462500056;
BA_ "GenMsgSendType" BO_ 2609983704 1;
BA_ "GenMsgDelayTime" BO_ 2609983704 0;
BA_ "NetworkInitialization" BO_ 2609983704 0;
BA_ "TpTxIndex" BO_ 2610126924 462500056;
BA_ "GenMsgSendType" BO_ 2610126924 1;
BA_ "GenMsgDelayTime" BO_ 2610126924 0;
BA_ "NetworkInitialization" BO_ 2610126924 0;
BA_ "TpTxIndex" BO_ 2611032280 463548632;
BA_ "GenMsgSendType" BO_ 2611032280 1;
BA_ "GenMsgDelayTime" BO_ 2611032280 0;
BA_ "NetworkInitialization" BO_ 2611032280 0;
BA_ "TpTxIndex" BO_ 2611175500 463548632;
BA_ "GenMsgSendType" BO_ 2611175500 1;
BA_ "GenMsgDelayTime" BO_ 2611175500 0;
BA_ "NetworkInitialization" BO_ 2611175500 0;
BA_ "OvtpPushApplication" BO_ 2612080856 1;
BA_ "TpTxIndex" BO_ 2612080856 464597208;
BA_ "GenMsgSendType" BO_ 2612080856 1;
BA_ "GenMsgDelayTime" BO_ 2612080856 0;
BA_ "NetworkInitialization" BO_ 2612080856 0;
BA_ "OvtpPushApplication" BO_ 2612224076 1;
BA_ "TpTxIndex" BO_ 2612224076 464597208;
BA_ "GenMsgSendType" BO_ 2612224076 1;
BA_ "GenMsgDelayTime" BO_ 2612224076 0;
BA_ "NetworkInitialization" BO_ 2612224076 0;
BA_ "TpTxIndex" BO_ 2613129432 465645784;
BA_ "GenMsgSendType" BO_ 2613129432 1;
BA_ "GenMsgDelayTime" BO_ 2613129432 0;
BA_ "NetworkInitialization" BO_ 2613129432 0;
BA_ "TpTxIndex" BO_ 2613272652 465645784;
BA_ "GenMsgSendType" BO_ 2613272652 1;
BA_ "GenMsgDelayTime" BO_ 2613272652 0;
BA_ "NetworkInitialization" BO_ 2613272652 0;
BA_ "SC_Message" BO_ 932 1;
BA_ "SCP_DataId" BO_ 932 5028;
BA_ "FrameRouting" BO_ 932 "FD1_CAN,0x3A4;";
BA_ "VFrameFormat" BO_ 932 14;
BA_ "SC_Message" BO_ 118 1;
BA_ "SCP_DataId" BO_ 118 4214;
BA_ "FrameRouting" BO_ 118 "FD1_CAN,0x76;";
BA_ "VFrameFormat" BO_ 118 14;
BA_ "GenMsgILSupport" BO_ 1968 0;
BA_ "DiagRequest" BO_ 1968 1;
BA_ "GenMsgSendType" BO_ 1968 1;
BA_ "GenMsgDelayTime" BO_ 1968 0;
BA_ "NetworkInitialization" BO_ 1968 0;
BA_ "VFrameFormat" BO_ 1968 14;
BA_ "GenMsgILSupport" BO_ 1936 0;
BA_ "DiagRequest" BO_ 1936 1;
BA_ "GenMsgSendType" BO_ 1936 1;
BA_ "GenMsgDelayTime" BO_ 1936 0;
BA_ "NetworkInitialization" BO_ 1936 0;
BA_ "VFrameFormat" BO_ 1936 14;
BA_ "SC_Message" BO_ 132 1;
BA_ "SCP_DataId" BO_ 132 12420;
BA_ "FrameRouting" BO_ 132 "FD1_CAN,0x84;";
BA_ "VFrameFormat" BO_ 132 14;
BA_ "SC_Message" BO_ 1045 1;
BA_ "SCP_DataId" BO_ 1045 5141;
BA_ "FrameRouting" BO_ 1045 "FD1_CAN,0x415;";
BA_ "VFrameFormat" BO_ 1045 14;
BA_ "SC_Message" BO_ 947 1;
BA_ "SCP_DataId" BO_ 947 5043;
BA_ "FrameRouting" BO_ 947 "FD1_CAN,0x3B3;";
BA_ "VFrameFormat" BO_ 947 14;
BA_ "GenMsgRoutingTimeoutTime" BO_ 126 30;
BA_ "FrameRouting" BO_ 126 "FD3_CAN,0x7E";
BA_ "VFrameFormat" BO_ 126 14;
BA_ "GenMsgILSupport" BO_ 1766 0;
BA_ "DiagRequest" BO_ 1766 1;
BA_ "GenMsgSendType" BO_ 1766 1;
BA_ "GenMsgDelayTime" BO_ 1766 0;
BA_ "NetworkInitialization" BO_ 1766 0;
BA_ "VFrameFormat" BO_ 1766 14;
BA_ "SC_Message" BO_ 357 1;
BA_ "SCP_DataId" BO_ 357 4453;
BA_ "FrameRouting" BO_ 357 "FD1_CAN,0x165;";
BA_ "VFrameFormat" BO_ 357 14;
BA_ "SC_Message" BO_ 651 1;
BA_ "SCP_DataId" BO_ 651 17035;
BA_ "GenMsgSendType" BO_ 651 5;
BA_ "GenMsgCycleTime" BO_ 651 1000;
BA_ "VFrameFormat" BO_ 651 14;
BA_ "FrameRouting" BO_ 261 "HS3_CAN,0x105;";
BA_ "VFrameFormat" BO_ 261 14;
BA_ "TpTxIndex" BO_ 600 50;
BA_ "FrameRouting" BO_ 600 "HS3_CAN,0x258;";
BA_ "VFrameFormat" BO_ 600 14;
BA_ "GenMsgSendType" BO_ 625 5;
BA_ "GenMsgCycleTime" BO_ 625 1000;
BA_ "VFrameFormat" BO_ 625 14;
BA_ "FrameRouting" BO_ 616 "FD1_CAN,0x268;";
BA_ "VFrameFormat" BO_ 616 14;
BA_ "FrameRouting" BO_ 617 "FD1_CAN,0x269;";
BA_ "VFrameFormat" BO_ 617 14;
BA_ "FrameRouting" BO_ 1119 "HS3_CAN,0x45F;";
BA_ "VFrameFormat" BO_ 1119 14;
BA_ "SC_Message" BO_ 622 1;
BA_ "SCP_DataId" BO_ 622 12910;
BA_ "FrameRouting" BO_ 622 "FD1_CAN,0x26E;";
BA_ "VFrameFormat" BO_ 622 14;
BA_ "FrameRouting" BO_ 1118 "HS3_CAN,0x45E;";
BA_ "VFrameFormat" BO_ 1118 14;
BA_ "TpTxIndex" BO_ 592 50;
BA_ "VFrameFormat" BO_ 592 14;
BA_ "SC_Message" BO_ 895 1;
BA_ "SCP_DataId" BO_ 895 4991;
BA_ "GenMsgSendType" BO_ 895 0;
BA_ "GenMsgCycleTime" BO_ 895 60;
BA_ "VFrameFormat" BO_ 895 14;
BA_ "GenMsgILSupport" BO_ 1416 0;
BA_ "NmAsrMessage" BO_ 1416 1;
BA_ "GenMsgSendType" BO_ 1416 0;
BA_ "GenMsgCycleTime" BO_ 1416 1000;
BA_ "NetworkInitialization" BO_ 1416 0;
BA_ "VFrameFormat" BO_ 1416 14;
BA_ "GenMsgILSupport" BO_ 1849 0;
BA_ "DiagResponse" BO_ 1849 1;
BA_ "GenMsgSendType" BO_ 1849 1;
BA_ "GenMsgDelayTime" BO_ 1849 0;
BA_ "NetworkInitialization" BO_ 1849 0;
BA_ "VFrameFormat" BO_ 1849 14;
BA_ "GenMsgSendType" BO_ 624 5;
BA_ "GenMsgCycleTime" BO_ 624 1000;
BA_ "VFrameFormat" BO_ 624 14;
BA_ "GenMsgSendType" BO_ 621 5;
BA_ "GenMsgCycleTime" BO_ 621 200;
BA_ "VFrameFormat" BO_ 621 14;
BA_ "GenMsgSendType" BO_ 620 5;
BA_ "GenMsgCycleTime" BO_ 620 200;
BA_ "VFrameFormat" BO_ 620 14;
BA_ "GenMsgSendType" BO_ 619 5;
BA_ "GenMsgCycleTime" BO_ 619 200;
BA_ "VFrameFormat" BO_ 619 14;
BA_ "GenMsgSendType" BO_ 618 5;
BA_ "GenMsgCycleTime" BO_ 618 200;
BA_ "VFrameFormat" BO_ 618 14;
BA_ "SC_Message" BO_ 154 1;
BA_ "SCP_AuthInfoTxLength" BO_ 154 51;
BA_ "SCP_FreshnessValueTxLength" BO_ 154 45;
BA_ "SCP_DataId" BO_ 154 16538;
BA_ "SCP_FreshnessValueLength" BO_ 154 48;
BA_ "GenMsgSendType" BO_ 154 0;
BA_ "GenMsgCycleTime" BO_ 154 50;
BA_ "VFrameFormat" BO_ 154 14;
BA_ "TpTxIndex" BO_ 2614099160 466615512;
BA_ "GenMsgSendType" BO_ 2614099160 1;
BA_ "GenMsgDelayTime" BO_ 2614099160 0;
BA_ "NetworkInitialization" BO_ 2614099160 0;
BA_ "TpTxIndex" BO_ 2613272721 465716440;
BA_ "GenMsgSendType" BO_ 2613272721 1;
BA_ "GenMsgDelayTime" BO_ 2613272721 0;
BA_ "NetworkInitialization" BO_ 2613272721 0;
BA_ "TpTxIndex" BO_ 2613200088 465716440;
BA_ "GenMsgSendType" BO_ 2613200088 1;
BA_ "GenMsgDelayTime" BO_ 2613200088 0;
BA_ "NetworkInitialization" BO_ 2613200088 0;
BA_ "FrameRouting" BO_ 145 "HS2_CAN,0x91";
BA_ "VFrameFormat" BO_ 145 14;
BA_ "SC_Message" BO_ 1090 1;
BA_ "SCP_DataId" BO_ 1090 17474;
BA_ "FrameRouting" BO_ 1090 "FD1_CAN,0x442;";
BA_ "VFrameFormat" BO_ 1090 14;
BA_ "OvtpPushApplication" BO_ 2612224145 1;
BA_ "TpTxIndex" BO_ 2612224145 464667864;
BA_ "GenMsgSendType" BO_ 2612224145 1;
BA_ "GenMsgDelayTime" BO_ 2612224145 0;
BA_ "NetworkInitialization" BO_ 2612224145 0;
BA_ "TpTxIndex" BO_ 1192 20;
BA_ "FrameRouting" BO_ 1192 "HS3_CAN,0x4A8;";
BA_ "VFrameFormat" BO_ 1192 14;
BA_ "TpTxIndex" BO_ 2611175569 463619288;
BA_ "GenMsgSendType" BO_ 2611175569 1;
BA_ "GenMsgDelayTime" BO_ 2611175569 0;
BA_ "NetworkInitialization" BO_ 2611175569 0;
BA_ "TpTxIndex" BO_ 2611102936 463619288;
BA_ "GenMsgSendType" BO_ 2611102936 1;
BA_ "GenMsgDelayTime" BO_ 2611102936 0;
BA_ "NetworkInitialization" BO_ 2611102936 0;
BA_ "TpTxIndex" BO_ 2610126993 462570712;
BA_ "GenMsgSendType" BO_ 2610126993 1;
BA_ "GenMsgDelayTime" BO_ 2610126993 0;
BA_ "NetworkInitialization" BO_ 2610126993 0;
BA_ "TpTxIndex" BO_ 2610054360 462570712;
BA_ "GenMsgSendType" BO_ 2610054360 1;
BA_ "GenMsgDelayTime" BO_ 2610054360 0;
BA_ "NetworkInitialization" BO_ 2610054360 0;
BA_ "TpTxIndex" BO_ 589 30;
BA_ "FrameRouting" BO_ 589 "HS3_CAN,0x24D;";
BA_ "VFrameFormat" BO_ 589 14;
BA_ "OvtpPushApplication" BO_ 2612151512 1;
BA_ "TpTxIndex" BO_ 2612151512 464667864;
BA_ "GenMsgSendType" BO_ 2612151512 1;
BA_ "GenMsgDelayTime" BO_ 2612151512 0;
BA_ "NetworkInitialization" BO_ 2612151512 0;
BA_ "SC_Message" BO_ 945 1;
BA_ "SCP_DataId" BO_ 945 5041;
BA_ "FrameRouting" BO_ 945 "FD1_CAN,0x3B1;";
BA_ "VFrameFormat" BO_ 945 14;
BA_ "FrameRouting" BO_ 290 "HS3_CAN,0x122;";
BA_ "VFrameFormat" BO_ 290 14;
BA_ "GenMsgSendType" BO_ 542 1;
BA_ "NetworkInitialization" BO_ 542 0;
BA_ "VFrameFormat" BO_ 542 14;
BA_ "GenMsgSendType" BO_ 636 5;
BA_ "GenMsgCycleTime" BO_ 636 1000;
BA_ "VFrameFormat" BO_ 636 14;
BA_ "SC_Message" BO_ 1087 1;
BA_ "SCP_DataId" BO_ 1087 5183;
BA_ "FrameRouting" BO_ 1087 "FD1_CAN,0x43F;";
BA_ "VFrameFormat" BO_ 1087 14;
BA_ "SC_Message" BO_ 831 1;
BA_ "SCP_DataId" BO_ 831 17215;
BA_ "FrameRouting" BO_ 831 "FD3_CAN,0x33F;";
BA_ "VFrameFormat" BO_ 831 14;
BA_ "WakeupSignal" SG_ 966 TrunkFrontRolCd_No_Actl 1;
BA_ "WakeupSignal" SG_ 966 TrunkFrontOpen_No_Actl 1;
BA_ "WakeupSignal" SG_ 966 ScrtyHornActv_B_Rq 1;
BA_ "WakeupSignal" SG_ 966 VehHorn_D_RqAlrt 1;
BA_ "WakeupSignal" SG_ 966 VehHorn_D_Rq 1;
BA_ "GenSigStartValue" SG_ 119 VehTrvlDir_D_Stat 6;
BA_ "GenSigStartValue" SG_ 119 VehLongComp_A_Actl 1022;
BA_ "U_P708_MY2023_Rx" SG_ 119 VehLongComp_A_Actl 1;
BA_ "U_CDX74X_MY2024_Rx" SG_ 119 VehLongComp_A_Actl 1;
BA_ "GenSigStartValue" SG_ 119 VehLatComp_A_Actl 1022;
BA_ "GenSigStartValue" SG_ 119 VehYawComp_W_Actl 4094;
BA_ "MetaData" SG_ 985 LongCtrlEnblDRq_No_Cs 1;
BA_ "ContentDependant" SG_ 985 LongCtrlEnblDRq_No_Cs 1;
BA_ "MetaData" SG_ 985 LongCtrlEnblDRq_No_Cnt 1;
BA_ "ContentDependant" SG_ 985 LongCtrlEnblDRq_No_Cnt 1;
BA_ "GenSigStartValue" SG_ 985 IsaVLim_D_Rq 254;
BA_ "GenSigStartValue" SG_ 985 IaccVLimUnit_D_Rq 3;
BA_ "GenSigStartValue" SG_ 985 IaccVLim_D_Rq 254;
BA_ "GenSigSendType" SG_ 1927 TesterPhysicalReqWBCM 3;
BA_ "GenSigStartValue" SG_ 942 ApaOffOptnSel_B_Avail 1;
BA_ "GenSigSendType" SG_ 1734 TesterPhysicalReqNFAM 3;
BA_ "GenSigSendType" SG_ 367 AuthctnStatIndx_No_Actl 3;
BA_ "ECGUsedTxSignal" SG_ 367 AuthctnStatIndx_No_Actl 1;
BA_ "GenSigSendType" SG_ 367 AuthctnStatId_No_Actl 3;
BA_ "ECGUsedTxSignal" SG_ 367 AuthctnStatId_No_Actl 1;
BA_ "GenSigSendType" SG_ 367 AuthctnInfoLoc_D_Stat 3;
BA_ "ECGUsedTxSignal" SG_ 367 AuthctnInfoLoc_D_Stat 1;
BA_ "GenSigSendType" SG_ 367 AuthctnInfo_D_Stat 3;
BA_ "ECGUsedTxSignal" SG_ 367 AuthctnInfo_D_Stat 1;
BA_ "GenSigSendType" SG_ 367 AuthctnInfoIndx_No_Actl 3;
BA_ "ECGUsedTxSignal" SG_ 367 AuthctnInfoIndx_No_Actl 1;
BA_ "GenSigSendType" SG_ 367 AuthctnInfoId_No_Actl 3;
BA_ "ECGUsedTxSignal" SG_ 367 AuthctnInfoId_No_Actl 1;
BA_ "GenSigSendType" SG_ 367 HashNonce2_No_Res 3;
BA_ "ECGUsedTxSignal" SG_ 367 HashNonce2_No_Res 1;
BA_ "GenSigSendType" SG_ 367 HashNonce1_No_Res 3;
BA_ "ECGUsedTxSignal" SG_ 367 HashNonce1_No_Res 1;
BA_ "GenSigSendType" SG_ 367 HashSalt2_No_Res 3;
BA_ "ECGUsedTxSignal" SG_ 367 HashSalt2_No_Res 1;
BA_ "GenSigSendType" SG_ 367 HashSalt1_No_Res 3;
BA_ "ECGUsedTxSignal" SG_ 367 HashSalt1_No_Res 1;
BA_ "GenSigSendType" SG_ 367 HashIndx_D_Stat 3;
BA_ "ECGUsedTxSignal" SG_ 367 HashIndx_D_Stat 1;
BA_ "GenSigSendType" SG_ 367 HashIndx_No_Actl 3;
BA_ "ECGUsedTxSignal" SG_ 367 HashIndx_No_Actl 1;
BA_ "GenSigSendType" SG_ 367 HashId_No_Actl 3;
BA_ "ECGUsedTxSignal" SG_ 367 HashId_No_Actl 1;
BA_ "GenSigSendType" SG_ 367 ApnlPsswrdType_D_Stat 3;
BA_ "ECGUsedTxSignal" SG_ 367 ApnlPsswrdType_D_Stat 1;
BA_ "GenSigSendType" SG_ 367 ApnlPsswrdIndx_No_Actl 3;
BA_ "ECGUsedTxSignal" SG_ 367 ApnlPsswrdIndx_No_Actl 1;
BA_ "GenSigSendType" SG_ 367 ApnlPsswrdId_No_Actl 3;
BA_ "ECGUsedTxSignal" SG_ 367 ApnlPsswrdId_No_Actl 1;
BA_ "GenSigSendType" SG_ 367 AuthctnStatRtry_No_Actl 3;
BA_ "ECGUsedTxSignal" SG_ 367 AuthctnStatRtry_No_Actl 1;
BA_ "GenSigSendType" SG_ 367 AuthctnStatChnl_D_Stat 3;
BA_ "ECGUsedTxSignal" SG_ 367 AuthctnStatChnl_D_Stat 1;
BA_ "GenSigSendType" SG_ 367 AuthctnStat_D_Stat 3;
BA_ "ECGUsedTxSignal" SG_ 367 AuthctnStat_D_Stat 1;
BA_ "GenSigSendType" SG_ 1203 ApnlNameTxt18_No_Actl 3;
BA_ "ECGUsedTxSignal" SG_ 1203 ApnlNameTxt18_No_Actl 1;
BA_ "GenSigSendType" SG_ 1203 ApnlNameTxt17_No_Actl 3;
BA_ "ECGUsedTxSignal" SG_ 1203 ApnlNameTxt17_No_Actl 1;
BA_ "GenSigSendType" SG_ 1203 ApnlNameTxt16_No_Actl 3;
BA_ "ECGUsedTxSignal" SG_ 1203 ApnlNameTxt16_No_Actl 1;
BA_ "GenSigSendType" SG_ 1203 ApnlNameTxt15_No_Actl 3;
BA_ "ECGUsedTxSignal" SG_ 1203 ApnlNameTxt15_No_Actl 1;
BA_ "GenSigSendType" SG_ 1203 ApnlNameTxt14_No_Actl 3;
BA_ "ECGUsedTxSignal" SG_ 1203 ApnlNameTxt14_No_Actl 1;
BA_ "GenSigSendType" SG_ 1203 ApnlNameTxt13_No_Actl 3;
BA_ "ECGUsedTxSignal" SG_ 1203 ApnlNameTxt13_No_Actl 1;
BA_ "GenSigSendType" SG_ 1203 ApnlNameTxt12_No_Actl 3;
BA_ "ECGUsedTxSignal" SG_ 1203 ApnlNameTxt12_No_Actl 1;
BA_ "GenSigSendType" SG_ 1203 ApnlNameTxt11_No_Actl 3;
BA_ "ECGUsedTxSignal" SG_ 1203 ApnlNameTxt11_No_Actl 1;
BA_ "GenSigSendType" SG_ 1203 ApnlNameTxt10_No_Actl 3;
BA_ "ECGUsedTxSignal" SG_ 1203 ApnlNameTxt10_No_Actl 1;
BA_ "GenSigSendType" SG_ 1203 ApnlNameTxt09_No_Actl 3;
BA_ "ECGUsedTxSignal" SG_ 1203 ApnlNameTxt09_No_Actl 1;
BA_ "GenSigSendType" SG_ 1203 ApnlNameTxt08_No_Actl 3;
BA_ "ECGUsedTxSignal" SG_ 1203 ApnlNameTxt08_No_Actl 1;
BA_ "GenSigSendType" SG_ 1203 ApnlNameTxt07_No_Actl 3;
BA_ "ECGUsedTxSignal" SG_ 1203 ApnlNameTxt07_No_Actl 1;
BA_ "GenSigSendType" SG_ 1203 ApnlNameTxt06_No_Actl 3;
BA_ "ECGUsedTxSignal" SG_ 1203 ApnlNameTxt06_No_Actl 1;
BA_ "GenSigSendType" SG_ 1203 ApnlNameTxt05_No_Actl 3;
BA_ "ECGUsedTxSignal" SG_ 1203 ApnlNameTxt05_No_Actl 1;
BA_ "GenSigSendType" SG_ 1203 ApnlNameTxt04_No_Actl 3;
BA_ "ECGUsedTxSignal" SG_ 1203 ApnlNameTxt04_No_Actl 1;
BA_ "GenSigSendType" SG_ 1203 ApnlNameTxt03_No_Actl 3;
BA_ "ECGUsedTxSignal" SG_ 1203 ApnlNameTxt03_No_Actl 1;
BA_ "GenSigSendType" SG_ 1203 ApnlNameTxt02_No_Actl 3;
BA_ "ECGUsedTxSignal" SG_ 1203 ApnlNameTxt02_No_Actl 1;
BA_ "GenSigSendType" SG_ 1203 ApnlNameTxt01_No_Actl 3;
BA_ "ECGUsedTxSignal" SG_ 1203 ApnlNameTxt01_No_Actl 1;
BA_ "GenSigStartValue" SG_ 948 Tire_Press_Placrd_Rear 255;
BA_ "GenSigStartValue" SG_ 948 Tire_Press_Placrd_Frnt 255;
BA_ "U_P708_MY2023_Rx" SG_ 948 Tire_Press_ILR_Stat 1;
BA_ "U_CDX74X_MY2024_Rx" SG_ 948 Tire_Press_ILR_Stat 1;
BA_ "U_P708_MY2023_Rx" SG_ 948 Tire_Press_IRR_Stat 1;
BA_ "U_CDX74X_MY2024_Rx" SG_ 948 Tire_Press_IRR_Stat 1;
BA_ "U_P708_MY2023_Rx" SG_ 948 Tire_Press_LR_OLR_Stat 1;
BA_ "U_CDX74X_MY2024_Rx" SG_ 948 Tire_Press_LR_OLR_Stat 1;
BA_ "U_P708_MY2023_Rx" SG_ 948 Tire_Press_RR_ORR_Stat 1;
BA_ "U_CDX74X_MY2024_Rx" SG_ 948 Tire_Press_RR_ORR_Stat 1;
BA_ "U_P708_MY2023_Rx" SG_ 948 Tire_Press_RF_Stat 1;
BA_ "U_CDX74X_MY2024_Rx" SG_ 948 Tire_Press_RF_Stat 1;
BA_ "U_P708_MY2023_Rx" SG_ 948 Tire_Press_LF_Stat 1;
BA_ "U_CDX74X_MY2024_Rx" SG_ 948 Tire_Press_LF_Stat 1;
BA_ "GenSigSendType" SG_ 131 TurnLghtSwtch_D_Arb 3;
BA_ "U_P702_MY2024_Tx" SG_ 131 ElPwAsstSte_B_RqDactv 1;
BA_ "WakeupSignal" SG_ 131 ElPwAsstSte_B_RqDactv 1;
BA_ "GenSigSendType" SG_ 131 ElPwAsstSte_B_RqDactv 3;
BA_ "WakeupSignal" SG_ 131 HeadLghtHiCtrl_D_RqAhb 1;
BA_ "GenSigStartValue" SG_ 131 WiprFrontSwtch_D_Stat 9;
BA_ "WakeupSignal" SG_ 131 HeadLghtHiOn_B_StatAhb 1;
BA_ "GenSigStartValue" SG_ 131 WiprFront_D_Stat 15;
BA_ "U_P708_MY2023_Rx" SG_ 131 WiprFront_D_Stat 1;
BA_ "U_CDX74X_MY2024_Rx" SG_ 131 WiprFront_D_Stat 1;
BA_ "WakeupSignal" SG_ 131 TurnLghtSwtch_D_Stat 1;
BA_ "GenSigStartValue" SG_ 131 LghtAmb_D_Sns 7;
BA_ "WakeupSignal" SG_ 963 ImpactEvntFdbck_D_Stat 1;
BA_ "WakeupSignal" SG_ 963 KeyInIgnWarn_B_Cmd 1;
BA_ "WakeupSignal" SG_ 963 HomeSafeLtChime_B_Rq 1;
BA_ "WakeupSignal" SG_ 963 StopLghtOn_B_Stat 1;
BA_ "WakeupSignal" SG_ 963 PrkLght_D_Stat 1;
BA_ "WakeupSignal" SG_ 963 HeadLghtSwtch_D_Stat 1;
BA_ "GenSigStartValue" SG_ 963 HeadLghtSwtch_D_Stat 2;
BA_ "GenSigStartValue" SG_ 963 HeadLampLoFrOn_B_Stat 1;
BA_ "GenSigStartValue" SG_ 963 HeadLampLoFlOn_B_Stat 1;
BA_ "GenSigStartValue" SG_ 963 HeadLampLoActv_B_Stat 1;
BA_ "U_P708_MY2023_Rx" SG_ 963 HeadLampLoActv_B_Stat 1;
BA_ "U_CDX74X_MY2024_Rx" SG_ 963 HeadLampLoActv_B_Stat 1;
BA_ "WakeupSignal" SG_ 963 Headlamp_On_Wrning_Cmd 1;
BA_ "WakeupSignal" SG_ 963 HeadLghtHiOn_B_Stat 1;
BA_ "U_P708_MY2023_Rx" SG_ 963 HeadLghtHiOn_B_Stat 1;
BA_ "U_CDX74X_MY2024_Rx" SG_ 963 HeadLghtHiOn_B_Stat 1;
BA_ "WakeupSignal" SG_ 963 Perimeter_Alarm_Status 1;
BA_ "WakeupSignal" SG_ 963 Courtesy_BSave_Stat 1;
BA_ "GenSigStartValue" SG_ 963 Courtesy_BSave_Stat 1;
BA_ "WakeupSignal" SG_ 963 WndwGlbl_D_Cmd 1;
BA_ "WakeupSignal" SG_ 963 PudLamp_D_Rq 1;
BA_ "U_P708_MY2023_Rx" SG_ 963 DayRnngLampOn_B_Stat 1;
BA_ "WakeupSignal" SG_ 963 PerimeterAlarmChimeRq 1;
BA_ "GenSigSendType" SG_ 908 ApnlLogoId_No_Actl 3;
BA_ "ECGUsedTxSignal" SG_ 908 ApnlLogoId_No_Actl 1;
BA_ "GenSigSendType" SG_ 2609983704 OTAPhysGWM_ECGtoRFA_BLEM 3;
BA_ "ECGUsedTxSignal" SG_ 2609983704 OTAPhysGWM_ECGtoRFA_BLEM 1;
BA_ "U_CDX74X_MY2024_Tx" SG_ 2609983704 OTAPhysGWM_ECGtoRFA_BLEM 1;
BA_ "GenSigSendType" SG_ 2610126924 OTAPhysRFA_BLEMtoGWM_ECG 3;
BA_ "ECGUsedRxSignal" SG_ 2610126924 OTAPhysRFA_BLEMtoGWM_ECG 1;
BA_ "U_CDX74X_MY2024_Rx" SG_ 2610126924 OTAPhysRFA_BLEMtoGWM_ECG 1;
BA_ "GenSigSendType" SG_ 2611032280 PARSEDPhysGWM_ECGtoRFA_BLEM 3;
BA_ "ECGUsedTxSignal" SG_ 2611032280 PARSEDPhysGWM_ECGtoRFA_BLEM 1;
BA_ "U_CDX74X_MY2024_Tx" SG_ 2611032280 PARSEDPhysGWM_ECGtoRFA_BLEM 1;
BA_ "GenSigSendType" SG_ 2611175500 PARSEDPhysRFA_BLEMtoGWM_ECG 3;
BA_ "ECGUsedRxSignal" SG_ 2611175500 PARSEDPhysRFA_BLEMtoGWM_ECG 1;
BA_ "U_CDX74X_MY2024_Rx" SG_ 2611175500 PARSEDPhysRFA_BLEMtoGWM_ECG 1;
BA_ "GenSigSendType" SG_ 2612080856 PARSEDPushFcGWM_ECGtoRFA_BLEM 3;
BA_ "ECGUsedTxSignal" SG_ 2612080856 PARSEDPushFcGWM_ECGtoRFA_BLEM 1;
BA_ "U_CDX74X_MY2024_Tx" SG_ 2612080856 PARSEDPushFcGWM_ECGtoRFA_BLEM 1;
BA_ "GenSigSendType" SG_ 2612224076 PARSEDPushRFA_BLEMtoGWM_ECG 3;
BA_ "ECGUsedRxSignal" SG_ 2612224076 PARSEDPushRFA_BLEMtoGWM_ECG 1;
BA_ "U_CDX74X_MY2024_Rx" SG_ 2612224076 PARSEDPushRFA_BLEMtoGWM_ECG 1;
BA_ "GenSigSendType" SG_ 2613129432 SymKeyPhysGWM_ECGtoRFA_BLEM 3;
BA_ "ECGUsedTxSignal" SG_ 2613129432 SymKeyPhysGWM_ECGtoRFA_BLEM 1;
BA_ "U_CDX74X_MY2024_Tx" SG_ 2613129432 SymKeyPhysGWM_ECGtoRFA_BLEM 1;
BA_ "GenSigSendType" SG_ 2613272652 SymKeyPhysRFA_BLEMtoGWM_ECG 3;
BA_ "ECGUsedRxSignal" SG_ 2613272652 SymKeyPhysRFA_BLEMtoGWM_ECG 1;
BA_ "U_CDX74X_MY2024_Rx" SG_ 2613272652 SymKeyPhysRFA_BLEMtoGWM_ECG 1;
BA_ "ECGUsedRxSignal" SG_ 932 CanMsg3A4_UNUSED_8bit_4 1;
BA_ "GenSigStartValue" SG_ 932 CanMsg3A4_UNUSED_8bit_4 255;
BA_ "GenSigInactiveValue" SG_ 932 CanMsg3A4_UNUSED_8bit_4 255;
BA_ "ECGUsedRxSignal" SG_ 932 CanMsg3A4_UNUSED_8bit_3 1;
BA_ "GenSigStartValue" SG_ 932 CanMsg3A4_UNUSED_8bit_3 255;
BA_ "GenSigInactiveValue" SG_ 932 CanMsg3A4_UNUSED_8bit_3 255;
BA_ "ECGUsedRxSignal" SG_ 932 CanMsg3A4_UNUSED_8bit_2 1;
BA_ "GenSigStartValue" SG_ 932 CanMsg3A4_UNUSED_8bit_2 255;
BA_ "GenSigInactiveValue" SG_ 932 CanMsg3A4_UNUSED_8bit_2 255;
BA_ "ECGUsedRxSignal" SG_ 932 CanMsg3A4_UNUSED_8bit_1 1;
BA_ "GenSigStartValue" SG_ 932 CanMsg3A4_UNUSED_8bit_1 255;
BA_ "GenSigInactiveValue" SG_ 932 CanMsg3A4_UNUSED_8bit_1 255;
BA_ "ECGUsedRxSignal" SG_ 932 CanMsg3A4_UNUSED_7bit_1 1;
BA_ "GenSigStartValue" SG_ 932 CanMsg3A4_UNUSED_7bit_1 127;
BA_ "GenSigInactiveValue" SG_ 932 CanMsg3A4_UNUSED_7bit_1 127;
BA_ "U_V710_MY2023_Tx" SG_ 932 VehStrtInhbt_D_Stat 1;
BA_ "U_CDX74X_MY2024_Tx" SG_ 932 VehStrtInhbt_D_Stat 1;
BA_ "U_CDX707_MY2023_Tx" SG_ 932 VehStrtInhbt_D_Stat 1;
BA_ "U_P708_MY2023_Tx" SG_ 932 VehStrtInhbt_D_Stat 1;
BA_ "U_V713AV_MY2022_Tx" SG_ 932 VehStrtInhbt_D_Stat 1;
BA_ "U_V713N_MY2022_Tx" SG_ 932 VehStrtInhbt_D_Stat 1;
BA_ "U_P702_MY2024_Rx" SG_ 932 VehStrtInhbt_D_Stat 1;
BA_ "U_V710_MY2023_Rx" SG_ 932 VehStrtInhbt_D_Stat 1;
BA_ "U_CDX74X_MY2024_Rx" SG_ 932 VehStrtInhbt_D_Stat 1;
BA_ "U_CDX707_MY2023_Rx" SG_ 932 VehStrtInhbt_D_Stat 1;
BA_ "U_P708_MY2023_Rx" SG_ 932 VehStrtInhbt_D_Stat 1;
BA_ "U_V713AV_MY2022_Rx" SG_ 932 VehStrtInhbt_D_Stat 1;
BA_ "U_V713N_MY2022_Rx" SG_ 932 VehStrtInhbt_D_Stat 1;
BA_ "ECGUsedRxSignal" SG_ 932 VehStrtInhbt_D_Stat 1;
BA_ "U_V710_MY2023_Tx" SG_ 932 VehOnCtl_D_Stat 1;
BA_ "U_CDX74X_MY2024_Tx" SG_ 932 VehOnCtl_D_Stat 1;
BA_ "U_CDX707_MY2023_Tx" SG_ 932 VehOnCtl_D_Stat 1;
BA_ "U_P708_MY2023_Tx" SG_ 932 VehOnCtl_D_Stat 1;
BA_ "U_V713AV_MY2022_Tx" SG_ 932 VehOnCtl_D_Stat 1;
BA_ "U_V713N_MY2022_Tx" SG_ 932 VehOnCtl_D_Stat 1;
BA_ "U_P702_MY2024_Rx" SG_ 932 VehOnCtl_D_Stat 1;
BA_ "U_V710_MY2023_Rx" SG_ 932 VehOnCtl_D_Stat 1;
BA_ "U_CDX74X_MY2024_Rx" SG_ 932 VehOnCtl_D_Stat 1;
BA_ "U_CDX707_MY2023_Rx" SG_ 932 VehOnCtl_D_Stat 1;
BA_ "U_P708_MY2023_Rx" SG_ 932 VehOnCtl_D_Stat 1;
BA_ "U_V713AV_MY2022_Rx" SG_ 932 VehOnCtl_D_Stat 1;
BA_ "U_V713N_MY2022_Rx" SG_ 932 VehOnCtl_D_Stat 1;
BA_ "ECGUsedRxSignal" SG_ 932 VehOnCtl_D_Stat 1;
BA_ "U_V710_MY2023_Tx" SG_ 932 VehOnSrc2_D_Stat 1;
BA_ "U_CDX74X_MY2024_Tx" SG_ 932 VehOnSrc2_D_Stat 1;
BA_ "U_CDX707_MY2023_Tx" SG_ 932 VehOnSrc2_D_Stat 1;
BA_ "U_P708_MY2023_Tx" SG_ 932 VehOnSrc2_D_Stat 1;
BA_ "U_V713AV_MY2022_Tx" SG_ 932 VehOnSrc2_D_Stat 1;
BA_ "U_V713N_MY2022_Tx" SG_ 932 VehOnSrc2_D_Stat 1;
BA_ "U_P702_MY2024_Rx" SG_ 932 VehOnSrc2_D_Stat 1;
BA_ "U_V710_MY2023_Rx" SG_ 932 VehOnSrc2_D_Stat 1;
BA_ "U_CDX74X_MY2024_Rx" SG_ 932 VehOnSrc2_D_Stat 1;
BA_ "U_CDX707_MY2023_Rx" SG_ 932 VehOnSrc2_D_Stat 1;
BA_ "U_P708_MY2023_Rx" SG_ 932 VehOnSrc2_D_Stat 1;
BA_ "U_V713AV_MY2022_Rx" SG_ 932 VehOnSrc2_D_Stat 1;
BA_ "U_V713N_MY2022_Rx" SG_ 932 VehOnSrc2_D_Stat 1;
BA_ "ECGUsedRxSignal" SG_ 932 VehOnSrc2_D_Stat 1;
BA_ "MetaData" SG_ 932 CanMsg3A4_No_Crc 1;
BA_ "U_V710_MY2023_Tx" SG_ 932 CanMsg3A4_No_Crc 1;
BA_ "U_CDX74X_MY2024_Tx" SG_ 932 CanMsg3A4_No_Crc 1;
BA_ "U_CDX707_MY2023_Tx" SG_ 932 CanMsg3A4_No_Crc 1;
BA_ "U_P708_MY2023_Tx" SG_ 932 CanMsg3A4_No_Crc 1;
BA_ "U_V713AV_MY2022_Tx" SG_ 932 CanMsg3A4_No_Crc 1;
BA_ "U_V713N_MY2022_Tx" SG_ 932 CanMsg3A4_No_Crc 1;
BA_ "U_V710_MY2023_Rx" SG_ 932 CanMsg3A4_No_Crc 1;
BA_ "U_CDX74X_MY2024_Rx" SG_ 932 CanMsg3A4_No_Crc 1;
BA_ "U_P708_MY2023_Rx" SG_ 932 CanMsg3A4_No_Crc 1;
BA_ "U_V713AV_MY2022_Rx" SG_ 932 CanMsg3A4_No_Crc 1;
BA_ "U_V713N_MY2022_Rx" SG_ 932 CanMsg3A4_No_Crc 1;
BA_ "ECGUsedRxSignal" SG_ 932 CanMsg3A4_No_Crc 1;
BA_ "MetaData" SG_ 932 CanMsg3A4_No_Cnt 1;
BA_ "U_V710_MY2023_Tx" SG_ 932 CanMsg3A4_No_Cnt 1;
BA_ "U_CDX74X_MY2024_Tx" SG_ 932 CanMsg3A4_No_Cnt 1;
BA_ "U_CDX707_MY2023_Tx" SG_ 932 CanMsg3A4_No_Cnt 1;
BA_ "U_P708_MY2023_Tx" SG_ 932 CanMsg3A4_No_Cnt 1;
BA_ "U_V713AV_MY2022_Tx" SG_ 932 CanMsg3A4_No_Cnt 1;
BA_ "U_V713N_MY2022_Tx" SG_ 932 CanMsg3A4_No_Cnt 1;
BA_ "U_V710_MY2023_Rx" SG_ 932 CanMsg3A4_No_Cnt 1;
BA_ "U_CDX74X_MY2024_Rx" SG_ 932 CanMsg3A4_No_Cnt 1;
BA_ "U_P708_MY2023_Rx" SG_ 932 CanMsg3A4_No_Cnt 1;
BA_ "U_V713AV_MY2022_Rx" SG_ 932 CanMsg3A4_No_Cnt 1;
BA_ "U_V713N_MY2022_Rx" SG_ 932 CanMsg3A4_No_Cnt 1;
BA_ "ECGUsedRxSignal" SG_ 932 CanMsg3A4_No_Cnt 1;
BA_ "U_V710_MY2023_Tx" SG_ 932 VehInhbtMde_D_Stat 1;
BA_ "U_CDX74X_MY2024_Tx" SG_ 932 VehInhbtMde_D_Stat 1;
BA_ "U_CDX707_MY2023_Tx" SG_ 932 VehInhbtMde_D_Stat 1;
BA_ "U_P708_MY2023_Tx" SG_ 932 VehInhbtMde_D_Stat 1;
BA_ "U_V713AV_MY2022_Tx" SG_ 932 VehInhbtMde_D_Stat 1;
BA_ "U_V713N_MY2022_Tx" SG_ 932 VehInhbtMde_D_Stat 1;
BA_ "WakeupSignal" SG_ 932 ChildLck_D_Dsply 1;
BA_ "GenSigStartValue" SG_ 932 ChildLck_D_Dsply 1;
BA_ "MetaData" SG_ 118 SteWhlCompAnEst_D_Qf 1;
BA_ "GenSigSendType" SG_ 1968 TesterPhysicalReqRDAPM 3;
BA_ "GenSigSendType" SG_ 1936 TesterPhysicalReqLDAPM 3;
BA_ "U_V713N_MY2022_Rx" SG_ 132 GlblClkYr_No_Actl 1;
BA_ "U_V713AV_MY2022_Rx" SG_ 132 GlblClkYr_No_Actl 1;
BA_ "U_P708_MY2023_Rx" SG_ 132 GlblClkYr_No_Actl 1;
BA_ "U_CDX74X_MY2024_Rx" SG_ 132 GlblClkYr_No_Actl 1;
BA_ "U_V710_MY2023_Rx" SG_ 132 GlblClkYr_No_Actl 1;
BA_ "U_V713N_MY2022_Rx" SG_ 132 GlblClkScnd_No_Actl 1;
BA_ "U_V713AV_MY2022_Rx" SG_ 132 GlblClkScnd_No_Actl 1;
BA_ "U_P708_MY2023_Rx" SG_ 132 GlblClkScnd_No_Actl 1;
BA_ "U_CDX74X_MY2024_Rx" SG_ 132 GlblClkScnd_No_Actl 1;
BA_ "U_V710_MY2023_Rx" SG_ 132 GlblClkScnd_No_Actl 1;
BA_ "U_V713N_MY2022_Rx" SG_ 132 GlblClkMnte_No_Actl 1;
BA_ "U_V713AV_MY2022_Rx" SG_ 132 GlblClkMnte_No_Actl 1;
BA_ "U_P708_MY2023_Rx" SG_ 132 GlblClkMnte_No_Actl 1;
BA_ "U_CDX74X_MY2024_Rx" SG_ 132 GlblClkMnte_No_Actl 1;
BA_ "U_V710_MY2023_Rx" SG_ 132 GlblClkMnte_No_Actl 1;
BA_ "U_V713N_MY2022_Rx" SG_ 132 GlblClkHr_No_Actl 1;
BA_ "U_V713AV_MY2022_Rx" SG_ 132 GlblClkHr_No_Actl 1;
BA_ "U_P708_MY2023_Rx" SG_ 132 GlblClkHr_No_Actl 1;
BA_ "U_CDX74X_MY2024_Rx" SG_ 132 GlblClkHr_No_Actl 1;
BA_ "U_V710_MY2023_Rx" SG_ 132 GlblClkHr_No_Actl 1;
BA_ "U_V713N_MY2022_Rx" SG_ 132 GlblClkDay_No_Actl 1;
BA_ "U_V713AV_MY2022_Rx" SG_ 132 GlblClkDay_No_Actl 1;
BA_ "U_P708_MY2023_Rx" SG_ 132 GlblClkDay_No_Actl 1;
BA_ "U_CDX74X_MY2024_Rx" SG_ 132 GlblClkDay_No_Actl 1;
BA_ "U_V710_MY2023_Rx" SG_ 132 GlblClkDay_No_Actl 1;
BA_ "GenSigStartValue" SG_ 1045 VehStab_D_Stat 14;
BA_ "GenSigStartValue" SG_ 1045 VehYawNonLin_W_Rq 4094;
BA_ "GenSigStartValue" SG_ 1045 VehYawLin_W_Rq 4094;
BA_ "MetaData" SG_ 1045 VehVActlBrk_No_Cs 1;
BA_ "MetaData" SG_ 1045 VehVActlBrk_No_Cnt 1;
BA_ "MetaData" SG_ 1045 VehVActlBrk_D_Qf 1;
BA_ "WakeupSignal" SG_ 947 DimmingLvlEvnt_No_Actl 1;
BA_ "WakeupSignal" SG_ 947 TurnLghtRight_D_Rq 1;
BA_ "U_P708_MY2023_Rx" SG_ 947 FogLghtRearOn_B_Stat 1;
BA_ "U_CDX74X_MY2024_Rx" SG_ 947 FogLghtRearOn_B_Stat 1;
BA_ "WakeupSignal" SG_ 947 Backlit_LED_Status 1;
BA_ "WakeupSignal" SG_ 947 TurnLghtLeft_D_Rq 1;
BA_ "U_P708_MY2023_Rx" SG_ 947 FogLghtFrontOn_B_Stat 1;
BA_ "U_CDX74X_MY2024_Rx" SG_ 947 FogLghtFrontOn_B_Stat 1;
BA_ "GenSigStartValue" SG_ 947 IgnKeyType_D_Actl 14;
BA_ "WakeupSignal" SG_ 947 Parklamp_Status 1;
BA_ "GenSigStartValue" SG_ 947 Parklamp_Status 1;
BA_ "U_V713AV_MY2022_Rx" SG_ 947 Parklamp_Status 1;
BA_ "U_P708_MY2023_Rx" SG_ 947 Parklamp_Status 1;
BA_ "U_CDX74X_MY2024_Rx" SG_ 947 Parklamp_Status 1;
BA_ "U_V710_MY2023_Rx" SG_ 947 Parklamp_Status 1;
BA_ "WakeupSignal" SG_ 947 Litval 1;
BA_ "WakeupSignal" SG_ 947 Key_In_Ignition_Stat 1;
BA_ "WakeupSignal" SG_ 947 Ignition_Status 1;
BA_ "U_V713N_MY2022_Rx" SG_ 947 Ignition_Status 1;
BA_ "U_V713AV_MY2022_Rx" SG_ 947 Ignition_Status 1;
BA_ "U_P708_MY2023_Rx" SG_ 947 Ignition_Status 1;
BA_ "U_CDX74X_MY2024_Rx" SG_ 947 Ignition_Status 1;
BA_ "U_V710_MY2023_Rx" SG_ 947 Ignition_Status 1;
BA_ "WakeupSignal" SG_ 947 Dimming_Lvl 1;
BA_ "GenSigStartValue" SG_ 947 Dimming_Lvl 12;
BA_ "U_V713AV_MY2022_Rx" SG_ 947 Dimming_Lvl 1;
BA_ "U_P708_MY2023_Rx" SG_ 947 Dimming_Lvl 1;
BA_ "U_CDX74X_MY2024_Rx" SG_ 947 Dimming_Lvl 1;
BA_ "U_V710_MY2023_Rx" SG_ 947 Dimming_Lvl 1;
BA_ "WakeupSignal" SG_ 947 Day_Night_Status 1;
BA_ "U_V713AV_MY2022_Rx" SG_ 947 Day_Night_Status 1;
BA_ "U_P708_MY2023_Rx" SG_ 947 Day_Night_Status 1;
BA_ "U_CDX74X_MY2024_Rx" SG_ 947 Day_Night_Status 1;
BA_ "U_V710_MY2023_Rx" SG_ 947 Day_Night_Status 1;
BA_ "WakeupSignal" SG_ 947 Remote_Start_Status 1;
BA_ "U_V713AV_MY2022_Rx" SG_ 947 Remote_Start_Status 1;
BA_ "WakeupSignal" SG_ 947 DrStatTgate_B_Actl 1;
BA_ "U_CDX74X_MY2024_Rx" SG_ 947 DrStatTgate_B_Actl 1;
BA_ "WakeupSignal" SG_ 947 DrStatRr_B_Actl 1;
BA_ "U_V713AV_MY2022_Rx" SG_ 947 DrStatRr_B_Actl 1;
BA_ "U_CDX74X_MY2024_Rx" SG_ 947 DrStatRr_B_Actl 1;
BA_ "WakeupSignal" SG_ 947 DrStatRl_B_Actl 1;
BA_ "U_V713AV_MY2022_Rx" SG_ 947 DrStatRl_B_Actl 1;
BA_ "U_CDX74X_MY2024_Rx" SG_ 947 DrStatRl_B_Actl 1;
BA_ "WakeupSignal" SG_ 947 DrStatPsngr_B_Actl 1;
BA_ "U_V713AV_MY2022_Rx" SG_ 947 DrStatPsngr_B_Actl 1;
BA_ "U_CDX74X_MY2024_Rx" SG_ 947 DrStatPsngr_B_Actl 1;
BA_ "WakeupSignal" SG_ 947 DrStatInnrTgate_B_Actl 1;
BA_ "U_V713AV_MY2022_Rx" SG_ 947 DrStatInnrTgate_B_Actl 1;
BA_ "U_CDX74X_MY2024_Rx" SG_ 947 DrStatInnrTgate_B_Actl 1;
BA_ "WakeupSignal" SG_ 947 DrStatHood_B_Actl 1;
BA_ "U_V713AV_MY2022_Rx" SG_ 947 DrStatHood_B_Actl 1;
BA_ "U_CDX74X_MY2024_Rx" SG_ 947 DrStatHood_B_Actl 1;
BA_ "WakeupSignal" SG_ 947 DrStatDrv_B_Actl 1;
BA_ "U_V713AV_MY2022_Rx" SG_ 947 DrStatDrv_B_Actl 1;
BA_ "U_CDX74X_MY2024_Rx" SG_ 947 DrStatDrv_B_Actl 1;
BA_ "WakeupSignal" SG_ 947 PrkBrkActv_B_Actl 1;
BA_ "U_P708_MY2023_Rx" SG_ 947 PrkBrkActv_B_Actl 1;
BA_ "U_CDX74X_MY2024_Rx" SG_ 947 PrkBrkActv_B_Actl 1;
BA_ "U_V713N_MY2022_Rx" SG_ 947 LifeCycMde_D_Actl 1;
BA_ "U_V713AV_MY2022_Rx" SG_ 947 LifeCycMde_D_Actl 1;
BA_ "U_P708_MY2023_Rx" SG_ 947 LifeCycMde_D_Actl 1;
BA_ "U_CDX74X_MY2024_Rx" SG_ 947 LifeCycMde_D_Actl 1;
BA_ "U_V710_MY2023_Rx" SG_ 947 LifeCycMde_D_Actl 1;
BA_ "WakeupSignal" SG_ 947 Delay_Accy 1;
BA_ "U_V713N_MY2022_Rx" SG_ 947 Delay_Accy 1;
BA_ "U_V713AV_MY2022_Rx" SG_ 947 Delay_Accy 1;
BA_ "U_CDX74X_MY2024_Rx" SG_ 947 Delay_Accy 1;
BA_ "U_V710_MY2023_Rx" SG_ 947 Delay_Accy 1;
BA_ "WakeupSignal" SG_ 947 CrashEvnt_D_Stat 1;
BA_ "GenSigStartValue" SG_ 947 CrashEvnt_D_Stat 3;
BA_ "GenSigStartValue" SG_ 126 StePinRelInit_An_Sns 65535;
BA_ "MetaData" SG_ 126 StePinCompAnEst_D_Qf 1;
BA_ "GenSigStartValue" SG_ 126 StePinCompAnEst_D_Qf 1;
BA_ "U_P708_MY2023_Rx" SG_ 126 StePinComp_An_Est 1;
BA_ "U_CDX74X_MY2024_Rx" SG_ 126 StePinComp_An_Est 1;
BA_ "MetaData" SG_ 126 StePinAn_No_Cs 1;
BA_ "MetaData" SG_ 126 StePinAn_No_Cnt 1;
BA_ "GenSigSendType" SG_ 1766 TesterPhysicalReqTCUB 3;
BA_ "MetaData" SG_ 357 BPedDrvAppl_D_Qf 1;
BA_ "GenSigStartValue" SG_ 357 BPedDrvAppl_D_Qf 1;
BA_ "MetaData" SG_ 357 BpedDrvAppl_No_Cs 1;
BA_ "MetaData" SG_ 357 BpedDrvAppl_No_Cnt 1;
BA_ "GenSigStartValue" SG_ 357 BpedDrvAppl_D_Actl 1;
BA_ "GenSigSendType" SG_ 651 CrnkInhbtSrvcHlth_B_St 3;
BA_ "GenSigStartValue" SG_ 651 CrnkInhbtSrvcHlth_B_St 1;
BA_ "GenSigSendType" SG_ 651 TelematicsSrvc_D_St 3;
BA_ "U_V713AV_MY2022_Tx" SG_ 651 TelematicsSrvc_D_St 1;
BA_ "U_P708_MY2023_Tx" SG_ 651 TelematicsSrvc_D_St 1;
BA_ "U_CDX74X_MY2024_Tx" SG_ 651 TelematicsSrvc_D_St 1;
BA_ "U_V710_MY2023_Tx" SG_ 651 TelematicsSrvc_D_St 1;
BA_ "GenSigSendType" SG_ 651 EmgcyCallMute_D_Stat 3;
BA_ "U_V713AV_MY2022_Tx" SG_ 651 EmgcyCallMute_D_Stat 1;
BA_ "U_P708_MY2023_Tx" SG_ 651 EmgcyCallMute_D_Stat 1;
BA_ "U_CDX74X_MY2024_Tx" SG_ 651 EmgcyCallMute_D_Stat 1;
BA_ "U_V710_MY2023_Tx" SG_ 651 EmgcyCallMute_D_Stat 1;
BA_ "GenSigStartValue" SG_ 261 ChrgStatDsply_D_Rq 1;
BA_ "U_V713AV_MY2022_Rx" SG_ 261 ModemReset_D_Rq 1;
BA_ "U_V713N_MY2022_Rx" SG_ 261 TCU_ESN_D_Rq 1;
BA_ "U_V713AV_MY2022_Rx" SG_ 261 TCU_ESN_D_Rq 1;
BA_ "U_P708_MY2023_Rx" SG_ 261 TCU_ESN_D_Rq 1;
BA_ "U_CDX74X_MY2024_Rx" SG_ 261 TCU_ESN_D_Rq 1;
BA_ "U_V710_MY2023_Rx" SG_ 261 TCU_ESN_D_Rq 1;
BA_ "U_V713AV_MY2022_Rx" SG_ 261 FactoryReset_Rq 1;
BA_ "U_V713AV_MY2022_Rx" SG_ 600 APIM_RFA_BLEM_Tx 1;
BA_ "GenSigSendType" SG_ 625 NfcSerial_D_Rq 3;
BA_ "ECGUsedTxSignal" SG_ 625 NfcSerial_D_Rq 1;
BA_ "GenSigStartValue" SG_ 625 ModemAuthrz_D_Stat2 3;
BA_ "U_V713AV_MY2022_Rx" SG_ 625 ModemAuthrz_D_Stat2 1;
BA_ "ECGUsedTxSignal" SG_ 625 ModemAuthrz_D_Stat2 1;
BA_ "U_V713N_MY2022_Tx" SG_ 625 ModemAuthrz_D_Stat2 1;
BA_ "U_V713AV_MY2022_Tx" SG_ 625 ModemAuthrz_D_Stat2 1;
BA_ "U_CDX74X_MY2024_Tx" SG_ 625 ModemAuthrz_D_Stat2 1;
BA_ "U_V710_MY2023_Tx" SG_ 625 ModemAuthrz_D_Stat2 1;
BA_ "U_V713AV_MY2022_Rx" SG_ 625 PaakSerial_D2_Rq2 1;
BA_ "ECGUsedTxSignal" SG_ 625 PaakSerial_D2_Rq2 1;
BA_ "U_V713N_MY2022_Tx" SG_ 625 PaakSerial_D2_Rq2 1;
BA_ "U_V713AV_MY2022_Tx" SG_ 625 PaakSerial_D2_Rq2 1;
BA_ "U_CDX74X_MY2024_Tx" SG_ 625 PaakSerial_D2_Rq2 1;
BA_ "U_V710_MY2023_Tx" SG_ 625 PaakSerial_D2_Rq2 1;
BA_ "WakeupSignal" SG_ 616 PaakTrgtPreAuthrz_B_Rq 1;
BA_ "U_V713AV_MY2022_Rx" SG_ 616 PaakTrgtPreAuthrz_B_Rq 1;
BA_ "U_V713AV_MY2022_Rx" SG_ 616 KeyPadCodeProg_D_Stat 1;
BA_ "U_V713AV_MY2022_Rx" SG_ 616 PaakTrgtData_D_Rq 1;
BA_ "U_V713AV_MY2022_Rx" SG_ 616 PaakTrgtPssvData_No_Rq 1;
BA_ "U_V713AV_MY2022_Rx" SG_ 616 PaakTrgtRollCode_No_Rq 1;
BA_ "WakeupSignal" SG_ 616 PaakTrgtType_D_Rq 1;
BA_ "U_V713AV_MY2022_Rx" SG_ 616 PaakTrgtType_D_Rq 1;
BA_ "U_V713AV_MY2022_Rx" SG_ 616 PaakTrgtZone_D_Rq 1;
BA_ "U_V713AV_MY2022_Rx" SG_ 617 PaakAddErase_D_Stat 1;
BA_ "U_V713AV_MY2022_Rx" SG_ 617 PaakAddEraseIndx_No_Actl 1;
BA_ "U_V713AV_MY2022_Rx" SG_ 617 PaakTrgtActvData_No_Rq 1;
BA_ "U_V713AV_MY2022_Rx" SG_ 1119 LocationServices_2 1;
BA_ "U_V713AV_MY2022_Rx" SG_ 622 FobCtlType_D_Stat 1;
BA_ "U_V713AV_MY2022_Rx" SG_ 622 FobCtlRollCode_No_Stat 1;
BA_ "U_V713AV_MY2022_Rx" SG_ 622 FobCtlPssvData_No_Actl 1;
BA_ "U_V713AV_MY2022_Rx" SG_ 1118 LocationServices_1 1;
BA_ "U_V713N_MY2022_Rx" SG_ 1118 LocationServices_1 1;
BA_ "U_P708_MY2023_Rx" SG_ 1118 LocationServices_1 1;
BA_ "U_CDX74X_MY2024_Rx" SG_ 1118 LocationServices_1 1;
BA_ "U_V710_MY2023_Rx" SG_ 1118 LocationServices_1 1;
BA_ "U_V713AV_MY2022_Tx" SG_ 592 RFA_BLEM_APIM_Tx 1;
BA_ "U_V713AV_MY2022_Tx" SG_ 895 TurnLght_D_RqRmtCtl 1;
BA_ "U_V713AV_MY2022_Tx" SG_ 895 RmtCtlRngSet_D_Rq 1;
BA_ "U_V713AV_MY2022_Tx" SG_ 895 RmtCtlRes_D_Stat 1;
BA_ "U_V713AV_MY2022_Tx" SG_ 895 RmtCtlKeyPoll_D_Rq 1;
BA_ "MetaData" SG_ 895 RmtCtlDStat_No_Cs 1;
BA_ "U_V713AV_MY2022_Tx" SG_ 895 RmtCtlDStat_No_Cs 1;
BA_ "MetaData" SG_ 895 RmtCtlDStat_No_Cnt 1;
BA_ "U_V713AV_MY2022_Tx" SG_ 895 RmtCtlDStat_No_Cnt 1;
BA_ "U_V713AV_MY2022_Tx" SG_ 895 RmtCtlCntnsIn_B_Stat 1;
BA_ "WakeupSignal" SG_ 895 RmtCtl_D_Stat 1;
BA_ "U_V713AV_MY2022_Tx" SG_ 895 RmtCtl_D_Stat 1;
BA_ "GenSigStartValue" SG_ 1416 RFA_GWOnBoardTester 255;
BA_ "U_V713AV_MY2022_Tx" SG_ 1416 RFA_GWOnBoardTester 1;
BA_ "GenSigStartValue" SG_ 1416 RFA_GWNMProxy 255;
BA_ "U_V713AV_MY2022_Tx" SG_ 1416 RFA_GWNMProxy 1;
BA_ "GenSigStartValue" SG_ 1416 RFA_AutoSarNMReserved4 255;
BA_ "U_V713AV_MY2022_Tx" SG_ 1416 RFA_AutoSarNMReserved4 1;
BA_ "GenSigStartValue" SG_ 1416 RFA_AutoSarNMReserved3 255;
BA_ "U_V713AV_MY2022_Tx" SG_ 1416 RFA_AutoSarNMReserved3 1;
BA_ "GenSigStartValue" SG_ 1416 RFA_AutoSarNMReserved2 255;
BA_ "U_V713AV_MY2022_Tx" SG_ 1416 RFA_AutoSarNMReserved2 1;
BA_ "GenSigStartValue" SG_ 1416 RFA_AutoSarNMReserved1 255;
BA_ "U_V713AV_MY2022_Tx" SG_ 1416 RFA_AutoSarNMReserved1 1;
BA_ "GenSigStartValue" SG_ 1416 RFA_AutoSarNMNodeId 136;
BA_ "U_V713AV_MY2022_Tx" SG_ 1416 RFA_AutoSarNMNodeId 1;
BA_ "U_V713AV_MY2022_Tx" SG_ 1416 RFA_AutoSarNMControl 1;
BA_ "GenSigSendType" SG_ 1849 TesterPhysicalResRFA 3;
BA_ "U_V713AV_MY2022_Tx" SG_ 1849 TesterPhysicalResRFA 1;
BA_ "U_V713AV_MY2022_Tx" SG_ 624 PaakAddEraseIndx_No_Rq 1;
BA_ "GenSigSendType" SG_ 624 PaakAddErase_D_Rq 3;
BA_ "U_V713AV_MY2022_Tx" SG_ 624 PaakAddErase_D_Rq 1;
BA_ "GenSigSendType" SG_ 621 IgnPsswrdActv_B_Stat 3;
BA_ "U_V713AV_MY2022_Tx" SG_ 621 IgnPsswrdActv_B_Stat 1;
BA_ "GenSigSendType" SG_ 621 FobTrgtZone_D_Rq 3;
BA_ "U_V713AV_MY2022_Tx" SG_ 621 FobTrgtZone_D_Rq 1;
BA_ "GenSigSendType" SG_ 621 FobTrgtType_D_Rq 3;
BA_ "U_V713AV_MY2022_Tx" SG_ 621 FobTrgtType_D_Rq 1;
BA_ "GenSigSendType" SG_ 621 FobTrgtRollCode_No_Rq 3;
BA_ "U_V713AV_MY2022_Tx" SG_ 621 FobTrgtRollCode_No_Rq 1;
BA_ "U_V713AV_MY2022_Tx" SG_ 621 FobTrgtPssvData_No_Rq 1;
BA_ "GenSigSendType" SG_ 621 RmtCtlRjctAutoCfg_B_Rq 3;
BA_ "U_V713AV_MY2022_Tx" SG_ 621 RmtCtlRjctAutoCfg_B_Rq 1;
BA_ "GenSigSendType" SG_ 621 RmtCtlSelSlot_D_Rq 3;
BA_ "U_V713AV_MY2022_Tx" SG_ 621 RmtCtlSelSlot_D_Rq 1;
BA_ "GenSigSendType" SG_ 621 RmtCtlSelPrkMde_D_Rq 3;
BA_ "U_V713AV_MY2022_Tx" SG_ 621 RmtCtlSelPrkMde_D_Rq 1;
BA_ "GenSigSendType" SG_ 621 RmtCtlSelMoveDir_D_Rq 3;
BA_ "U_V713AV_MY2022_Tx" SG_ 621 RmtCtlSelMoveDir_D_Rq 1;
BA_ "GenSigSendType" SG_ 620 PaakCtlIndx8_No_Actl 3;
BA_ "U_V713AV_MY2022_Tx" SG_ 620 PaakCtlIndx8_No_Actl 1;
BA_ "GenSigSendType" SG_ 620 PaakCtlIndx7_No_Actl 3;
BA_ "U_V713AV_MY2022_Tx" SG_ 620 PaakCtlIndx7_No_Actl 1;
BA_ "GenSigSendType" SG_ 620 PaakCtlIndx6_No_Actl 3;
BA_ "U_V713AV_MY2022_Tx" SG_ 620 PaakCtlIndx6_No_Actl 1;
BA_ "GenSigSendType" SG_ 620 PaakCtlIndx5_No_Actl 3;
BA_ "U_V713AV_MY2022_Tx" SG_ 620 PaakCtlIndx5_No_Actl 1;
BA_ "GenSigSendType" SG_ 620 PaakCtlIndx4_No_Actl 3;
BA_ "U_V713AV_MY2022_Tx" SG_ 620 PaakCtlIndx4_No_Actl 1;
BA_ "GenSigSendType" SG_ 620 PaakCtlIndx3_No_Actl 3;
BA_ "U_V713AV_MY2022_Tx" SG_ 620 PaakCtlIndx3_No_Actl 1;
BA_ "GenSigSendType" SG_ 620 PaakCtlIndx2_No_Actl 3;
BA_ "U_V713AV_MY2022_Tx" SG_ 620 PaakCtlIndx2_No_Actl 1;
BA_ "GenSigSendType" SG_ 620 PaakCtlIndx1_No_Actl 3;
BA_ "U_V713AV_MY2022_Tx" SG_ 620 PaakCtlIndx1_No_Actl 1;
BA_ "GenSigSendType" SG_ 620 PaakCtlRollCode_No_Copy 3;
BA_ "U_V713AV_MY2022_Tx" SG_ 620 PaakCtlRollCode_No_Copy 1;
BA_ "GenSigSendType" SG_ 619 KeyPadCodeProg_D_Rq 3;
BA_ "U_V713AV_MY2022_Tx" SG_ 619 KeyPadCodeProg_D_Rq 1;
BA_ "GenSigSendType" SG_ 619 PaakCnnct_D_Stat 3;
BA_ "U_V713AV_MY2022_Tx" SG_ 619 PaakCnnct_D_Stat 1;
BA_ "U_V713AV_MY2022_Tx" SG_ 619 PaakCtlActv_No_Actl 1;
BA_ "WakeupSignal" SG_ 619 PaakCtlActv_D_Rq 1;
BA_ "GenSigSendType" SG_ 619 PaakCtlActv_D_Rq 3;
BA_ "U_V713AV_MY2022_Tx" SG_ 619 PaakCtlActv_D_Rq 1;
BA_ "U_V713AV_MY2022_Tx" SG_ 619 PaakCtlActvData_No_Actl 1;
BA_ "WakeupSignal" SG_ 618 PaakLoclzd_D_Stat 1;
BA_ "GenSigSendType" SG_ 618 PaakLoclzd_D_Stat 3;
BA_ "U_V713AV_MY2022_Tx" SG_ 618 PaakLoclzd_D_Stat 1;
BA_ "GenSigSendType" SG_ 618 IgnPsswrdSetup_B_Rq 3;
BA_ "U_V713AV_MY2022_Tx" SG_ 618 IgnPsswrdSetup_B_Rq 1;
BA_ "GenSigSendType" SG_ 618 IgnPsswrdLckout_B_Stat 3;
BA_ "U_V713AV_MY2022_Tx" SG_ 618 IgnPsswrdLckout_B_Stat 1;
BA_ "WakeupSignal" SG_ 618 PaakCtlType_D_Stat 1;
BA_ "GenSigSendType" SG_ 618 PaakCtlType_D_Stat 3;
BA_ "U_V713AV_MY2022_Tx" SG_ 618 PaakCtlType_D_Stat 1;
BA_ "WakeupSignal" SG_ 618 PaakCtlRollCode_No_Stat 1;
BA_ "U_V713AV_MY2022_Tx" SG_ 618 PaakCtlRollCode_No_Stat 1;
BA_ "WakeupSignal" SG_ 618 PaakCtlPssvData_No_Actl 1;
BA_ "U_V713AV_MY2022_Tx" SG_ 618 PaakCtlPssvData_No_Actl 1;
BA_ "WakeupSignal" SG_ 618 PaakCtlData_D_Stat 1;
BA_ "GenSigSendType" SG_ 618 PaakCtlData_D_Stat 3;
BA_ "U_V713AV_MY2022_Tx" SG_ 618 PaakCtlData_D_Stat 1;
BA_ "U_V713AV_MY2022_Rx" SG_ 154 TronTripCnt_No_Actl 1;
BA_ "ECGUsedTxSignal" SG_ 154 TronTripCnt_No_Actl 1;
BA_ "U_V713N_MY2022_Tx" SG_ 154 TronTripCnt_No_Actl 1;
BA_ "U_V713AV_MY2022_Tx" SG_ 154 TronTripCnt_No_Actl 1;
BA_ "U_P708_MY2023_Tx" SG_ 154 TronTripCnt_No_Actl 1;
BA_ "U_CDX74X_MY2024_Tx" SG_ 154 TronTripCnt_No_Actl 1;
BA_ "U_V710_MY2023_Tx" SG_ 154 TronTripCnt_No_Actl 1;
BA_ "U_V713AV_MY2022_Rx" SG_ 154 TronResetCnt_No_Actl 1;
BA_ "ECGUsedTxSignal" SG_ 154 TronResetCnt_No_Actl 1;
BA_ "U_V713N_MY2022_Tx" SG_ 154 TronResetCnt_No_Actl 1;
BA_ "U_V713AV_MY2022_Tx" SG_ 154 TronResetCnt_No_Actl 1;
BA_ "U_P708_MY2023_Tx" SG_ 154 TronResetCnt_No_Actl 1;
BA_ "U_CDX74X_MY2024_Tx" SG_ 154 TronResetCnt_No_Actl 1;
BA_ "U_V710_MY2023_Tx" SG_ 154 TronResetCnt_No_Actl 1;
BA_ "GenSigSendType" SG_ 2614099160 SymKeyFuncGWM_ECG 3;
BA_ "ECGUsedTxSignal" SG_ 2614099160 SymKeyFuncGWM_ECG 1;
BA_ "U_V713N_MY2022_Tx" SG_ 2614099160 SymKeyFuncGWM_ECG 1;
BA_ "U_V713AV_MY2022_Tx" SG_ 2614099160 SymKeyFuncGWM_ECG 1;
BA_ "U_P708_MY2023_Tx" SG_ 2614099160 SymKeyFuncGWM_ECG 1;
BA_ "U_CDX74X_MY2024_Tx" SG_ 2614099160 SymKeyFuncGWM_ECG 1;
BA_ "U_V710_MY2023_Tx" SG_ 2614099160 SymKeyFuncGWM_ECG 1;
BA_ "GenSigSendType" SG_ 2613272721 SymKeyPhysTCUtoGWM_ECG 3;
BA_ "ECGUsedRxSignal" SG_ 2613272721 SymKeyPhysTCUtoGWM_ECG 1;
BA_ "U_V713N_MY2022_Rx" SG_ 2613272721 SymKeyPhysTCUtoGWM_ECG 1;
BA_ "U_V713AV_MY2022_Rx" SG_ 2613272721 SymKeyPhysTCUtoGWM_ECG 1;
BA_ "U_P708_MY2023_Rx" SG_ 2613272721 SymKeyPhysTCUtoGWM_ECG 1;
BA_ "U_CDX74X_MY2024_Rx" SG_ 2613272721 SymKeyPhysTCUtoGWM_ECG 1;
BA_ "U_V710_MY2023_Rx" SG_ 2613272721 SymKeyPhysTCUtoGWM_ECG 1;
BA_ "GenSigSendType" SG_ 2613200088 SymKeyPhysGWM_ECGtoTCU 3;
BA_ "ECGUsedTxSignal" SG_ 2613200088 SymKeyPhysGWM_ECGtoTCU 1;
BA_ "U_V713N_MY2022_Tx" SG_ 2613200088 SymKeyPhysGWM_ECGtoTCU 1;
BA_ "U_V713AV_MY2022_Tx" SG_ 2613200088 SymKeyPhysGWM_ECGtoTCU 1;
BA_ "U_P708_MY2023_Tx" SG_ 2613200088 SymKeyPhysGWM_ECGtoTCU 1;
BA_ "U_CDX74X_MY2024_Tx" SG_ 2613200088 SymKeyPhysGWM_ECGtoTCU 1;
BA_ "U_V710_MY2023_Tx" SG_ 2613200088 SymKeyPhysGWM_ECGtoTCU 1;
BA_ "MetaData" SG_ 145 VehYawWActl_D_Qf 1;
BA_ "GenSigStartValue" SG_ 145 VehYawWActl_D_Qf 1;
BA_ "U_V713AV_MY2022_Rx" SG_ 145 VehYawWActl_D_Qf 1;
BA_ "U_P708_MY2023_Rx" SG_ 145 VehYawWActl_D_Qf 1;
BA_ "U_CDX74X_MY2024_Rx" SG_ 145 VehYawWActl_D_Qf 1;
BA_ "U_V710_MY2023_Rx" SG_ 145 VehYawWActl_D_Qf 1;
BA_ "MetaData" SG_ 145 VehRolWActl_D_Qf 1;
BA_ "GenSigStartValue" SG_ 145 VehRolWActl_D_Qf 1;
BA_ "MetaData" SG_ 145 VehRollYawW_No_Cs 1;
BA_ "MetaData" SG_ 145 VehRollYaw_No_Cnt 1;
BA_ "U_V713AV_MY2022_Rx" SG_ 145 VehRollYaw_No_Cnt 1;
BA_ "U_P708_MY2023_Rx" SG_ 145 VehRollYaw_No_Cnt 1;
BA_ "U_CDX74X_MY2024_Rx" SG_ 145 VehRollYaw_No_Cnt 1;
BA_ "U_V710_MY2023_Rx" SG_ 145 VehRollYaw_No_Cnt 1;
BA_ "GenSigStartValue" SG_ 145 VehYaw_W_Actl 65534;
BA_ "U_V713AV_MY2022_Rx" SG_ 145 VehYaw_W_Actl 1;
BA_ "U_P708_MY2023_Rx" SG_ 145 VehYaw_W_Actl 1;
BA_ "U_CDX74X_MY2024_Rx" SG_ 145 VehYaw_W_Actl 1;
BA_ "U_V710_MY2023_Rx" SG_ 145 VehYaw_W_Actl 1;
BA_ "GenSigStartValue" SG_ 145 VehRol_W_Actl 65534;
BA_ "U_V713AV_MY2022_Rx" SG_ 145 VehRol_W_Actl 1;
BA_ "U_V710_MY2023_Rx" SG_ 145 VehRol_W_Actl 1;
BA_ "GenSigStartValue" SG_ 1090 VehElRnge_L_Dsply 4093;
BA_ "U_V713AV_MY2022_Rx" SG_ 1090 VehElRnge_L_Dsply 1;
BA_ "GenSigStartValue" SG_ 1090 Inv1Ain_I_ActlMntr 32765;
BA_ "GenSigSendType" SG_ 2612224145 PARSEDPushTCUtoGWM_ECG 3;
BA_ "ECGUsedRxSignal" SG_ 2612224145 PARSEDPushTCUtoGWM_ECG 1;
BA_ "U_V713N_MY2022_Rx" SG_ 2612224145 PARSEDPushTCUtoGWM_ECG 1;
BA_ "U_V713AV_MY2022_Rx" SG_ 2612224145 PARSEDPushTCUtoGWM_ECG 1;
BA_ "U_P708_MY2023_Rx" SG_ 2612224145 PARSEDPushTCUtoGWM_ECG 1;
BA_ "U_CDX74X_MY2024_Rx" SG_ 2612224145 PARSEDPushTCUtoGWM_ECG 1;
BA_ "U_V710_MY2023_Rx" SG_ 2612224145 PARSEDPushTCUtoGWM_ECG 1;
BA_ "U_V713N_MY2022_Rx" SG_ 1192 APIM_TCU_Word_Tx 1;
BA_ "U_V713AV_MY2022_Rx" SG_ 1192 APIM_TCU_Word_Tx 1;
BA_ "U_P708_MY2023_Rx" SG_ 1192 APIM_TCU_Word_Tx 1;
BA_ "U_CDX74X_MY2024_Rx" SG_ 1192 APIM_TCU_Word_Tx 1;
BA_ "U_V710_MY2023_Rx" SG_ 1192 APIM_TCU_Word_Tx 1;
BA_ "GenSigSendType" SG_ 2611175569 PARSEDPhysTCUtoGWM_ECG 3;
BA_ "ECGUsedRxSignal" SG_ 2611175569 PARSEDPhysTCUtoGWM_ECG 1;
BA_ "U_V713N_MY2022_Rx" SG_ 2611175569 PARSEDPhysTCUtoGWM_ECG 1;
BA_ "U_V713AV_MY2022_Rx" SG_ 2611175569 PARSEDPhysTCUtoGWM_ECG 1;
BA_ "U_P708_MY2023_Rx" SG_ 2611175569 PARSEDPhysTCUtoGWM_ECG 1;
BA_ "U_CDX74X_MY2024_Rx" SG_ 2611175569 PARSEDPhysTCUtoGWM_ECG 1;
BA_ "U_V710_MY2023_Rx" SG_ 2611175569 PARSEDPhysTCUtoGWM_ECG 1;
BA_ "GenSigSendType" SG_ 2611102936 PARSEDPhysGWM_ECGtoTCU 3;
BA_ "ECGUsedTxSignal" SG_ 2611102936 PARSEDPhysGWM_ECGtoTCU 1;
BA_ "U_V713N_MY2022_Tx" SG_ 2611102936 PARSEDPhysGWM_ECGtoTCU 1;
BA_ "U_V713AV_MY2022_Tx" SG_ 2611102936 PARSEDPhysGWM_ECGtoTCU 1;
BA_ "U_P708_MY2023_Tx" SG_ 2611102936 PARSEDPhysGWM_ECGtoTCU 1;
BA_ "U_CDX74X_MY2024_Tx" SG_ 2611102936 PARSEDPhysGWM_ECGtoTCU 1;
BA_ "U_V710_MY2023_Tx" SG_ 2611102936 PARSEDPhysGWM_ECGtoTCU 1;
BA_ "GenSigSendType" SG_ 2610126993 OTAPhysTCUtoGWM_ECG 3;
BA_ "ECGUsedRxSignal" SG_ 2610126993 OTAPhysTCUtoGWM_ECG 1;
BA_ "U_V713N_MY2022_Rx" SG_ 2610126993 OTAPhysTCUtoGWM_ECG 1;
BA_ "U_V713AV_MY2022_Rx" SG_ 2610126993 OTAPhysTCUtoGWM_ECG 1;
BA_ "U_P708_MY2023_Rx" SG_ 2610126993 OTAPhysTCUtoGWM_ECG 1;
BA_ "U_CDX74X_MY2024_Rx" SG_ 2610126993 OTAPhysTCUtoGWM_ECG 1;
BA_ "U_V710_MY2023_Rx" SG_ 2610126993 OTAPhysTCUtoGWM_ECG 1;
BA_ "GenSigSendType" SG_ 2610054360 OTAPhysGWM_ECGtoTCU 3;
BA_ "ECGUsedTxSignal" SG_ 2610054360 OTAPhysGWM_ECGtoTCU 1;
BA_ "U_V713N_MY2022_Tx" SG_ 2610054360 OTAPhysGWM_ECGtoTCU 1;
BA_ "U_V713AV_MY2022_Tx" SG_ 2610054360 OTAPhysGWM_ECGtoTCU 1;
BA_ "U_P708_MY2023_Tx" SG_ 2610054360 OTAPhysGWM_ECGtoTCU 1;
BA_ "U_CDX74X_MY2024_Tx" SG_ 2610054360 OTAPhysGWM_ECGtoTCU 1;
BA_ "U_V710_MY2023_Tx" SG_ 2610054360 OTAPhysGWM_ECGtoTCU 1;
BA_ "GenSigSendType" SG_ 2612151512 PARSEDPushFcGWM_ECGtoTCU 3;
BA_ "ECGUsedTxSignal" SG_ 2612151512 PARSEDPushFcGWM_ECGtoTCU 1;
BA_ "U_V713N_MY2022_Tx" SG_ 2612151512 PARSEDPushFcGWM_ECGtoTCU 1;
BA_ "U_V713AV_MY2022_Tx" SG_ 2612151512 PARSEDPushFcGWM_ECGtoTCU 1;
BA_ "U_P708_MY2023_Tx" SG_ 2612151512 PARSEDPushFcGWM_ECGtoTCU 1;
BA_ "U_CDX74X_MY2024_Tx" SG_ 2612151512 PARSEDPushFcGWM_ECGtoTCU 1;
BA_ "U_V710_MY2023_Tx" SG_ 2612151512 PARSEDPushFcGWM_ECGtoTCU 1;
BA_ "WakeupSignal" SG_ 945 DelvrAsstMsgTxt_D_Rq 1;
BA_ "GenSigSendType" SG_ 945 DelvrAsstMsgTxt_D_Rq 3;
BA_ "WakeupSignal" SG_ 945 AdasRelay_B_Stat2 1;
BA_ "WakeupSignal" SG_ 945 PrkLckCtlMsgTxt_D2_Rq 1;
BA_ "WakeupSignal" SG_ 945 PwLoApim_T_Actl 1;
BA_ "U_V713N_MY2022_Rx" SG_ 945 KeyOffMde_D_Actl 1;
BA_ "U_V713AV_MY2022_Rx" SG_ 945 KeyOffMde_D_Actl 1;
BA_ "U_P708_MY2023_Rx" SG_ 945 KeyOffMde_D_Actl 1;
BA_ "U_CDX74X_MY2024_Rx" SG_ 945 KeyOffMde_D_Actl 1;
BA_ "U_V710_MY2023_Rx" SG_ 945 KeyOffMde_D_Actl 1;
BA_ "WakeupSignal" SG_ 945 KeyPadCodeDgt6_D_Dsply 1;
BA_ "WakeupSignal" SG_ 945 KeyPadCodeDgt5_D_Dsply 1;
BA_ "WakeupSignal" SG_ 945 KeyPadCodeDgt4_D_Dsply 1;
BA_ "WakeupSignal" SG_ 945 KeyPadCodeDgt3_D_Dsply 1;
BA_ "WakeupSignal" SG_ 945 KeyPadCodeDgt2_D_Dsply 1;
BA_ "WakeupSignal" SG_ 945 KeyPadCodeDgt1_D_Dsply 1;
BA_ "U_V713N_MY2022_Rx" SG_ 290 WifiHtsptFqBand_D_Rq 1;
BA_ "U_V713AV_MY2022_Rx" SG_ 290 WifiHtsptFqBand_D_Rq 1;
BA_ "U_P708_MY2023_Rx" SG_ 290 WifiHtsptFqBand_D_Rq 1;
BA_ "U_CDX74X_MY2024_Rx" SG_ 290 WifiHtsptFqBand_D_Rq 1;
BA_ "U_V710_MY2023_Rx" SG_ 290 WifiHtsptFqBand_D_Rq 1;
BA_ "U_V713N_MY2022_Rx" SG_ 290 WifiHtsptTrial_D_RqDrv 1;
BA_ "U_V713AV_MY2022_Rx" SG_ 290 WifiHtsptTrial_D_RqDrv 1;
BA_ "U_P708_MY2023_Rx" SG_ 290 WifiHtsptTrial_D_RqDrv 1;
BA_ "U_CDX74X_MY2024_Rx" SG_ 290 WifiHtsptTrial_D_RqDrv 1;
BA_ "U_V710_MY2023_Rx" SG_ 290 WifiHtsptTrial_D_RqDrv 1;
BA_ "U_V713N_MY2022_Rx" SG_ 290 WifiHtsptEnbl_D_Rq 1;
BA_ "U_V713AV_MY2022_Rx" SG_ 290 WifiHtsptEnbl_D_Rq 1;
BA_ "U_P708_MY2023_Rx" SG_ 290 WifiHtsptEnbl_D_Rq 1;
BA_ "U_CDX74X_MY2024_Rx" SG_ 290 WifiHtsptEnbl_D_Rq 1;
BA_ "U_V710_MY2023_Rx" SG_ 290 WifiHtsptEnbl_D_Rq 1;
BA_ "GenSigStartValue" SG_ 290 WifiRemoveIndx_No_Rq 20;
BA_ "U_V713N_MY2022_Rx" SG_ 290 WifiRemoveIndx_No_Rq 1;
BA_ "U_V713AV_MY2022_Rx" SG_ 290 WifiRemoveIndx_No_Rq 1;
BA_ "U_P708_MY2023_Rx" SG_ 290 WifiRemoveIndx_No_Rq 1;
BA_ "U_CDX74X_MY2024_Rx" SG_ 290 WifiRemoveIndx_No_Rq 1;
BA_ "U_V710_MY2023_Rx" SG_ 290 WifiRemoveIndx_No_Rq 1;
BA_ "U_V713N_MY2022_Rx" SG_ 290 WifiRemoveDevc_D_Rq 1;
BA_ "U_V713AV_MY2022_Rx" SG_ 290 WifiRemoveDevc_D_Rq 1;
BA_ "U_P708_MY2023_Rx" SG_ 290 WifiRemoveDevc_D_Rq 1;
BA_ "U_CDX74X_MY2024_Rx" SG_ 290 WifiRemoveDevc_D_Rq 1;
BA_ "U_V710_MY2023_Rx" SG_ 290 WifiRemoveDevc_D_Rq 1;
BA_ "U_V713N_MY2022_Rx" SG_ 290 WifiHtsptVisbl_D_Rq 1;
BA_ "U_V713AV_MY2022_Rx" SG_ 290 WifiHtsptVisbl_D_Rq 1;
BA_ "U_P708_MY2023_Rx" SG_ 290 WifiHtsptVisbl_D_Rq 1;
BA_ "U_CDX74X_MY2024_Rx" SG_ 290 WifiHtsptVisbl_D_Rq 1;
BA_ "U_V710_MY2023_Rx" SG_ 290 WifiHtsptVisbl_D_Rq 1;
BA_ "U_V713N_MY2022_Rx" SG_ 290 WifiHtsptMacAddr_B_Rq 1;
BA_ "U_V713AV_MY2022_Rx" SG_ 290 WifiHtsptMacAddr_B_Rq 1;
BA_ "U_P708_MY2023_Rx" SG_ 290 WifiHtsptMacAddr_B_Rq 1;
BA_ "U_CDX74X_MY2024_Rx" SG_ 290 WifiHtsptMacAddr_B_Rq 1;
BA_ "U_V710_MY2023_Rx" SG_ 290 WifiHtsptMacAddr_B_Rq 1;
BA_ "U_V713N_MY2022_Rx" SG_ 290 WifiDevcListSize_D_Rq 1;
BA_ "U_V713AV_MY2022_Rx" SG_ 290 WifiDevcListSize_D_Rq 1;
BA_ "U_P708_MY2023_Rx" SG_ 290 WifiDevcListSize_D_Rq 1;
BA_ "U_CDX74X_MY2024_Rx" SG_ 290 WifiDevcListSize_D_Rq 1;
BA_ "U_V710_MY2023_Rx" SG_ 290 WifiDevcListSize_D_Rq 1;
BA_ "GenSigStartValue" SG_ 290 WifiDevcListIndx_No_Rq 22;
BA_ "U_V713N_MY2022_Rx" SG_ 290 WifiDevcListIndx_No_Rq 1;
BA_ "U_V713AV_MY2022_Rx" SG_ 290 WifiDevcListIndx_No_Rq 1;
BA_ "U_P708_MY2023_Rx" SG_ 290 WifiDevcListIndx_No_Rq 1;
BA_ "U_CDX74X_MY2024_Rx" SG_ 290 WifiDevcListIndx_No_Rq 1;
BA_ "U_V710_MY2023_Rx" SG_ 290 WifiDevcListIndx_No_Rq 1;
BA_ "U_V713N_MY2022_Rx" SG_ 290 WifiDevcList_D_Rq 1;
BA_ "U_V713AV_MY2022_Rx" SG_ 290 WifiDevcList_D_Rq 1;
BA_ "U_P708_MY2023_Rx" SG_ 290 WifiDevcList_D_Rq 1;
BA_ "U_CDX74X_MY2024_Rx" SG_ 290 WifiDevcList_D_Rq 1;
BA_ "U_V710_MY2023_Rx" SG_ 290 WifiDevcList_D_Rq 1;
BA_ "U_V713N_MY2022_Rx" SG_ 290 WifiDataUsage_D_Rq 1;
BA_ "U_V713AV_MY2022_Rx" SG_ 290 WifiDataUsage_D_Rq 1;
BA_ "U_P708_MY2023_Rx" SG_ 290 WifiDataUsage_D_Rq 1;
BA_ "U_CDX74X_MY2024_Rx" SG_ 290 WifiDataUsage_D_Rq 1;
BA_ "U_V710_MY2023_Rx" SG_ 290 WifiDataUsage_D_Rq 1;
BA_ "U_V713N_MY2022_Rx" SG_ 290 WifiCarrierInfo_B_Rq 1;
BA_ "U_V713AV_MY2022_Rx" SG_ 290 WifiCarrierInfo_B_Rq 1;
BA_ "U_P708_MY2023_Rx" SG_ 290 WifiCarrierInfo_B_Rq 1;
BA_ "U_CDX74X_MY2024_Rx" SG_ 290 WifiCarrierInfo_B_Rq 1;
BA_ "U_V710_MY2023_Rx" SG_ 290 WifiCarrierInfo_B_Rq 1;
BA_ "U_V713N_MY2022_Rx" SG_ 290 WifiHtsptScrty_D_Rq 1;
BA_ "U_V713AV_MY2022_Rx" SG_ 290 WifiHtsptScrty_D_Rq 1;
BA_ "GenSigSendType" SG_ 542 LocationServices_3 3;
BA_ "U_V713AV_MY2022_Rx" SG_ 542 LocationServices_3 1;
BA_ "U_V713N_MY2022_Tx" SG_ 542 LocationServices_3 1;
BA_ "U_V713AV_MY2022_Tx" SG_ 542 LocationServices_3 1;
BA_ "U_P708_MY2023_Tx" SG_ 542 LocationServices_3 1;
BA_ "U_CDX74X_MY2024_Tx" SG_ 542 LocationServices_3 1;
BA_ "U_V710_MY2023_Tx" SG_ 542 LocationServices_3 1;
BA_ "GenSigSendType" SG_ 636 WifiHtsptFqBand_D_Stat 3;
BA_ "U_V713N_MY2022_Tx" SG_ 636 WifiHtsptFqBand_D_Stat 1;
BA_ "U_V713AV_MY2022_Tx" SG_ 636 WifiHtsptFqBand_D_Stat 1;
BA_ "U_P708_MY2023_Tx" SG_ 636 WifiHtsptFqBand_D_Stat 1;
BA_ "U_CDX74X_MY2024_Tx" SG_ 636 WifiHtsptFqBand_D_Stat 1;
BA_ "U_V710_MY2023_Tx" SG_ 636 WifiHtsptFqBand_D_Stat 1;
BA_ "GenSigSendType" SG_ 636 WifiHtspt_D_Falt 3;
BA_ "U_V713N_MY2022_Tx" SG_ 636 WifiHtspt_D_Falt 1;
BA_ "U_V713AV_MY2022_Tx" SG_ 636 WifiHtspt_D_Falt 1;
BA_ "U_P708_MY2023_Tx" SG_ 636 WifiHtspt_D_Falt 1;
BA_ "U_CDX74X_MY2024_Tx" SG_ 636 WifiHtspt_D_Falt 1;
BA_ "U_V710_MY2023_Tx" SG_ 636 WifiHtspt_D_Falt 1;
BA_ "U_V713N_MY2022_Tx" SG_ 636 WifiNoDevcCnnct_No_Actl 1;
BA_ "U_V713AV_MY2022_Tx" SG_ 636 WifiNoDevcCnnct_No_Actl 1;
BA_ "U_P708_MY2023_Tx" SG_ 636 WifiNoDevcCnnct_No_Actl 1;
BA_ "U_CDX74X_MY2024_Tx" SG_ 636 WifiNoDevcCnnct_No_Actl 1;
BA_ "U_V710_MY2023_Tx" SG_ 636 WifiNoDevcCnnct_No_Actl 1;
BA_ "GenSigSendType" SG_ 636 WifiHtsptCnnct_D_Stat 3;
BA_ "U_V713N_MY2022_Tx" SG_ 636 WifiHtsptCnnct_D_Stat 1;
BA_ "U_V713AV_MY2022_Tx" SG_ 636 WifiHtsptCnnct_D_Stat 1;
BA_ "U_P708_MY2023_Tx" SG_ 636 WifiHtsptCnnct_D_Stat 1;
BA_ "U_CDX74X_MY2024_Tx" SG_ 636 WifiHtsptCnnct_D_Stat 1;
BA_ "U_V710_MY2023_Tx" SG_ 636 WifiHtsptCnnct_D_Stat 1;
BA_ "GenSigSendType" SG_ 636 Telematics_D_Falt 3;
BA_ "U_V713N_MY2022_Tx" SG_ 636 Telematics_D_Falt 1;
BA_ "U_V713AV_MY2022_Tx" SG_ 636 Telematics_D_Falt 1;
BA_ "U_P708_MY2023_Tx" SG_ 636 Telematics_D_Falt 1;
BA_ "U_CDX74X_MY2024_Tx" SG_ 636 Telematics_D_Falt 1;
BA_ "U_V710_MY2023_Tx" SG_ 636 Telematics_D_Falt 1;
BA_ "GenSigSendType" SG_ 636 WifiEnbl_D_Stat 3;
BA_ "U_V713N_MY2022_Tx" SG_ 636 WifiEnbl_D_Stat 1;
BA_ "U_V713AV_MY2022_Tx" SG_ 636 WifiEnbl_D_Stat 1;
BA_ "U_P708_MY2023_Tx" SG_ 636 WifiEnbl_D_Stat 1;
BA_ "U_CDX74X_MY2024_Tx" SG_ 636 WifiEnbl_D_Stat 1;
BA_ "U_V710_MY2023_Tx" SG_ 636 WifiEnbl_D_Stat 1;
BA_ "GenSigSendType" SG_ 636 WifiHtsptVisbl_D_Stat 3;
BA_ "U_V713N_MY2022_Tx" SG_ 636 WifiHtsptVisbl_D_Stat 1;
BA_ "U_V713AV_MY2022_Tx" SG_ 636 WifiHtsptVisbl_D_Stat 1;
BA_ "U_P708_MY2023_Tx" SG_ 636 WifiHtsptVisbl_D_Stat 1;
BA_ "U_CDX74X_MY2024_Tx" SG_ 636 WifiHtsptVisbl_D_Stat 1;
BA_ "U_V710_MY2023_Tx" SG_ 636 WifiHtsptVisbl_D_Stat 1;
BA_ "GenSigSendType" SG_ 636 WifiHtsptScrty_D_Stat 3;
BA_ "U_V713N_MY2022_Tx" SG_ 636 WifiHtsptScrty_D_Stat 1;
BA_ "U_V713AV_MY2022_Tx" SG_ 636 WifiHtsptScrty_D_Stat 1;
BA_ "U_P708_MY2023_Tx" SG_ 636 WifiHtsptScrty_D_Stat 1;
BA_ "U_CDX74X_MY2024_Tx" SG_ 636 WifiHtsptScrty_D_Stat 1;
BA_ "U_V710_MY2023_Tx" SG_ 636 WifiHtsptScrty_D_Stat 1;
BA_ "GenSigSendType" SG_ 636 WifiHtsptEnbl_D_Stat 3;
BA_ "U_V713N_MY2022_Tx" SG_ 636 WifiHtsptEnbl_D_Stat 1;
BA_ "U_V713AV_MY2022_Tx" SG_ 636 WifiHtsptEnbl_D_Stat 1;
BA_ "U_P708_MY2023_Tx" SG_ 636 WifiHtsptEnbl_D_Stat 1;
BA_ "U_CDX74X_MY2024_Tx" SG_ 636 WifiHtsptEnbl_D_Stat 1;
BA_ "U_V710_MY2023_Tx" SG_ 636 WifiHtsptEnbl_D_Stat 1;
BA_ "GenSigSendType" SG_ 636 WifiDevcListNew_B_Stat 3;
BA_ "U_V713N_MY2022_Tx" SG_ 636 WifiDevcListNew_B_Stat 1;
BA_ "U_V713AV_MY2022_Tx" SG_ 636 WifiDevcListNew_B_Stat 1;
BA_ "U_P708_MY2023_Tx" SG_ 636 WifiDevcListNew_B_Stat 1;
BA_ "U_CDX74X_MY2024_Tx" SG_ 636 WifiDevcListNew_B_Stat 1;
BA_ "U_V710_MY2023_Tx" SG_ 636 WifiDevcListNew_B_Stat 1;
BA_ "U_V713N_MY2022_Tx" SG_ 636 WifiDataUsage_Pc_Actl 1;
BA_ "U_V713AV_MY2022_Tx" SG_ 636 WifiDataUsage_Pc_Actl 1;
BA_ "U_P708_MY2023_Tx" SG_ 636 WifiDataUsage_Pc_Actl 1;
BA_ "U_CDX74X_MY2024_Tx" SG_ 636 WifiDataUsage_Pc_Actl 1;
BA_ "U_V710_MY2023_Tx" SG_ 636 WifiDataUsage_Pc_Actl 1;
BA_ "GenSigSendType" SG_ 636 WifiDataUsage_D_Stat 3;
BA_ "U_V713N_MY2022_Tx" SG_ 636 WifiDataUsage_D_Stat 1;
BA_ "U_V713AV_MY2022_Tx" SG_ 636 WifiDataUsage_D_Stat 1;
BA_ "U_P708_MY2023_Tx" SG_ 636 WifiDataUsage_D_Stat 1;
BA_ "U_CDX74X_MY2024_Tx" SG_ 636 WifiDataUsage_D_Stat 1;
BA_ "U_V710_MY2023_Tx" SG_ 636 WifiDataUsage_D_Stat 1;
BA_ "GenSigStartValue" SG_ 636 ModemSigStren_D_Stat 6;
BA_ "GenSigSendType" SG_ 636 ModemSigStren_D_Stat 3;
BA_ "U_V713N_MY2022_Tx" SG_ 636 ModemSigStren_D_Stat 1;
BA_ "U_V713AV_MY2022_Tx" SG_ 636 ModemSigStren_D_Stat 1;
BA_ "U_P708_MY2023_Tx" SG_ 636 ModemSigStren_D_Stat 1;
BA_ "U_CDX74X_MY2024_Tx" SG_ 636 ModemSigStren_D_Stat 1;
BA_ "U_V710_MY2023_Tx" SG_ 636 ModemSigStren_D_Stat 1;
BA_ "GenSigSendType" SG_ 636 WifiHtsptCrdntl_B_Stat 3;
BA_ "U_V713N_MY2022_Tx" SG_ 636 WifiHtsptCrdntl_B_Stat 1;
BA_ "U_V713AV_MY2022_Tx" SG_ 636 WifiHtsptCrdntl_B_Stat 1;
BA_ "U_P708_MY2023_Tx" SG_ 636 WifiHtsptCrdntl_B_Stat 1;
BA_ "U_CDX74X_MY2024_Tx" SG_ 636 WifiHtsptCrdntl_B_Stat 1;
BA_ "U_V710_MY2023_Tx" SG_ 636 WifiHtsptCrdntl_B_Stat 1;
BA_ "GenSigSendType" SG_ 636 WifiHtsptFq_D_Avail 3;
BA_ "U_V713N_MY2022_Tx" SG_ 636 WifiHtsptFq_D_Avail 1;
BA_ "U_V713AV_MY2022_Tx" SG_ 636 WifiHtsptFq_D_Avail 1;
BA_ "U_P708_MY2023_Tx" SG_ 636 WifiHtsptFq_D_Avail 1;
BA_ "U_CDX74X_MY2024_Tx" SG_ 636 WifiHtsptFq_D_Avail 1;
BA_ "U_V710_MY2023_Tx" SG_ 636 WifiHtsptFq_D_Avail 1;
BA_ "GenSigSendType" SG_ 636 WifiDataUsageOn_D_Stat 3;
BA_ "U_V713N_MY2022_Tx" SG_ 636 WifiDataUsageOn_D_Stat 1;
BA_ "U_V713AV_MY2022_Tx" SG_ 636 WifiDataUsageOn_D_Stat 1;
BA_ "U_P708_MY2023_Tx" SG_ 636 WifiDataUsageOn_D_Stat 1;
BA_ "U_CDX74X_MY2024_Tx" SG_ 636 WifiDataUsageOn_D_Stat 1;
BA_ "U_V710_MY2023_Tx" SG_ 636 WifiDataUsageOn_D_Stat 1;
BA_ "GenSigSendType" SG_ 636 ModemTechnology_D2_Stat 3;
BA_ "U_V713N_MY2022_Tx" SG_ 636 ModemTechnology_D2_Stat 1;
BA_ "U_V713AV_MY2022_Tx" SG_ 636 ModemTechnology_D2_Stat 1;
BA_ "U_P708_MY2023_Tx" SG_ 636 ModemTechnology_D2_Stat 1;
BA_ "U_CDX74X_MY2024_Tx" SG_ 636 ModemTechnology_D2_Stat 1;
BA_ "U_V710_MY2023_Tx" SG_ 636 ModemTechnology_D2_Stat 1;
BA_ "GenSigSendType" SG_ 1087 CrnkInhbtActv_B_Stat 3;
BA_ "GenSigStartValue" SG_ 1087 CrnkInhbtActv_B_Stat 1;
BA_ "ECGUsedRxSignal" SG_ 1087 CrnkInhbtActv_B_Stat 1;
BA_ "WakeupSignal" SG_ 831 RearPassWindowCmd 1;
BA_ "WakeupSignal" SG_ 831 PassWindowCmd 1;
BA_ "WakeupSignal" SG_ 831 PassMirrorCmd 1;
BA_ "WakeupSignal" SG_ 831 RearDriverWindowPos 1;
BA_ "WakeupSignal" SG_ 831 DriverWindowPosition 1;
BA_REL_ "SC_Verification" BU_SG_REL_ RFA_BLEM SG_ 932 RmtCtlBattMntr_B_Falt 1;
BA_REL_ "SC_Verification" BU_SG_REL_ RFA_BLEM SG_ 1045 Veh_V_ActlBrk 1;
BA_REL_ "SC_Verification" BU_SG_REL_ RFA_BLEM SG_ 1045 VehVActlBrk_D_Qf 1;
BA_REL_ "SC_Verification" BU_SG_REL_ RFA_BLEM SG_ 947 Ignition_Status 1;
BA_REL_ "SC_Verification" BU_SG_REL_ RFA_BLEM SG_ 947 Remote_Start_Status 1;
BA_REL_ "SC_Verification" BU_SG_REL_ RFA_BLEM SG_ 947 DrStatHood_B_Actl 1;
BA_REL_ "SC_Verification" BU_SG_REL_ RFA_BLEM SG_ 622 FobCtlType_D_Stat 1;
BA_REL_ "SC_Verification" BU_SG_REL_ RFA_BLEM SG_ 622 FobCtlRollCode_No_Stat 1;
BA_REL_ "SC_Verification" BU_SG_REL_ RFA_BLEM SG_ 622 FobCtlPssvData_No_Actl 1;
BA_REL_ "SC_Verification" BU_SG_REL_ TCU SG_ 154 TronTripCnt_No_Actl 1;
BA_REL_ "SC_Verification" BU_SG_REL_ RFA_BLEM SG_ 154 TronTripCnt_No_Actl 1;
BA_REL_ "SC_Verification" BU_SG_REL_ TCU SG_ 154 TronResetCnt_No_Actl 1;
BA_REL_ "SC_Verification" BU_SG_REL_ RFA_BLEM SG_ 154 TronResetCnt_No_Actl 1;
VAL_ 966 NfcDevcAuthrzT_B_Rq 1 "Valid" 0 "Null" ;
VAL_ 966 NfcDevc_D_Dsply 15 "Message 15" 14 "Message 14" 13 "Message 13" 12 "Message 12" 11 "Message 11" 10 "Message 10" 9 "Message 9" 8 "Message 8" 7 "Message 7" 6 "Message 6" 5 "Message 5" 4 "Message 4" 3 "Message 3" 2 "Message 2" 1 "Message 1" 0 "No message" ;
VAL_ 966 PwTrnkFrntRelay_B_Stat 1 "Inhibit" 0 "NoInhibit" ;
VAL_ 966 PwTrnkFrontRleas_D_Src 15 "NotUsed_5" 14 "NotUsed_4" 13 "NotUsed_3" 12 "NotUsed_2" 11 "NotUsed_1" 10 "SelfTest" 9 "Diagnostics" 8 "EmergencyReleaseSwitch" 7 "ManualCinch" 6 "ExteriorSwitch" 5 "IpSwitch" 4 "Cpp" 3 "Sync" 2 "Keypad" 1 "Remote" 0 "PowerOff" ;
VAL_ 966 TrnkFrontScnd_B_Falt 1 "Fault" 0 "NoFault" ;
VAL_ 966 ExtLghtRear_D_RqBody 3 "NotUsed" 2 "On" 1 "Off" 0 "Null" ;
VAL_ 966 TrnkFrontInhbt_B_Stat 1 "Inhibit" 0 "NoInhibit" ;
VAL_ 966 TrnkFrontRleas_D_Src 7 "NotUsed_3" 6 "NotUsed_2" 5 "NotUsed_1" 4 "Cpp" 3 "Sync" 2 "Keypad" 1 "Remote" 0 "Null" ;
VAL_ 966 ScrtyHornActv_B_Rq 1 "Active" 0 "Inactive" ;
VAL_ 966 VehHorn_D_RqAlrt 3 "NotUsed" 2 "Null" 1 "On" 0 "Off" ;
VAL_ 966 VehHorn_D_Rq 15 "NotUsed_7" 14 "NotUsed_6" 13 "NotUsed_5" 12 "NotUsed_4" 11 "NotUsed_3" 10 "NotUsed_2" 9 "NotUsed_1" 8 "Chirp_3" 7 "ManualOn" 6 "Honk" 5 "ChirpHonk" 4 "Chirp_2H" 3 "Chirp_2" 2 "Chirp_1" 1 "Null" 0 "Off" ;
VAL_ 119 VehTrvlDir_D_Stat 7 "Faulty" 6 "NoDataExists" 5 "NotUsed2" 4 "NotUsed1" 3 "Reverse" 2 "LikelyReverse" 1 "Forward" 0 "LikelyForward" ;
VAL_ 119 VehOverGnd_V_Est 65535 "Invalid" 65534 "Unknown" ;
VAL_ 119 VehLongComp_A_Actl 1023 "Fault" 1022 "NoDataExists" ;
VAL_ 119 VehLatComp_A_Actl 1023 "Fault" 1022 "NoDataExists" ;
VAL_ 119 VehYawComp_W_Actl 4095 "Fault" 4094 "NoDataExists" ;
VAL_ 517 FapLc_B_Err 1 "Yes" 0 "No" ;
VAL_ 985 ClrExitAsst_D_Stat 3 "NotUsed" 2 "Enabled" 1 "Disabled" 0 "Null" ;
VAL_ 985 ClrExitAsstMsgTxt_D_Rq 15 "NotUsed_8" 14 "NotUsed_7" 13 "NotUsed_6" 12 "NotUsed_5" 11 "NotUsed_4" 10 "NotUsed_3" 9 "NotUsed_2" 8 "NotUsed_1" 7 "SystemFault" 6 "ChildLockMaintained" 5 "WarningRight" 4 "WarningLeft" 3 "InformationRight" 2 "InformationLeft" 1 "Shutdown" 0 "NoMessage" ;
VAL_ 985 ClrExitAsstChime_D_Rq 7 "NotUsed_4" 6 "NotUsed_3" 5 "NotUsed_2" 4 "NotUsed_1" 3 "WarningChimeFront" 2 "WarningChimeRear" 1 "InformationChime" 0 "Off" ;
VAL_ 985 PwSustnAdas_B_Rq 1 "Active" 0 "Inactive" ;
VAL_ 985 AdbDrvSide_B_Stat 1 "Left_Hand_Traffic" 0 "Right_Hand_Traffic" ;
VAL_ 985 LcwaMsgTxt_D_Stat 3 "SodXFaulty" 2 "SodXBlocked" 1 "TrailerConnected" 0 "NoMessage" ;
VAL_ 985 AdbDividedRoad_B_Stat 1 "Yes" 0 "No" ;
VAL_ 985 IsaVLimUnit_D_Rq 3 "NoDataExists" 2 "Mph" 1 "Kph" 0 "Null" ;
VAL_ 985 SblmYieldScnr_B_Stat 1 "Yes" 0 "No" ;
VAL_ 985 SblmStopScnr_B_Stat 1 "Yes" 0 "No" ;
VAL_ 985 IsaVLim_D_Rq 252 "NotUsed_2" 250 "LimitSpeed_250" 240 "LimitSpeed_240" 230 "LimitSpeed_230" 220 "LimitSpeed_220" 210 "LimitSpeed_210" 200 "LimitSpeed_200" 190 "LimitSpeed_190" 150 "LimitSpeed_150" 140 "LimitSpeed_140" 130 "LimitSpeed_130" 120 "LimitSpeed_120" 110 "LimitSpeed_110" 100 "LimitSpeed_100" 90 "LimitSpeed_90" 80 "LimitSpeed_80" 70 "LimitSpeed_70" 60 "LimitSpeed_60" 50 "LimitSpeed_50" 40 "LimitSpeed_40" 30 "LimitSpeed_30" 20 "LimtSpeed_20" 251 "NotUsed_1" 255 "Faulty" 254 "NoDataExists" 253 "NotUsed_3" 180 "LimitSpeed_180" 179 "LimitSpeed_179" 178 "LimitSpeed_178" 177 "LimitSpeed_177" 176 "LimitSpeed_176" 175 "LimitSpeed_175" 174 "LimitSpeed_174" 173 "LimitSpeed_173" 172 "LimitSpeed_172" 171 "LimitSpeed_171" 170 "LimitSpeed_170" 169 "LimitSpeed_169" 168 "LimitSpeed_168" 167 "LimitSpeed_167" 166 "LimitSpeed_166" 165 "LimitSpeed_165" 164 "LimitSpeed_164" 163 "LimitSpeed_163" 162 "LimitSpeed_162" 161 "LimitSpeed_161" 160 "LimitSpeed_160" 15 "LimitSpeed_15" 14 "LimitSpeed_14" 13 "LimitSpeed_13" 12 "LimitSpeed_12" 11 "LimitSpeed_11" 10 "LimitSpeed_10" 9 "LimitSpeed_9" 8 "LimitSpeed_8" 7 "LimitSpeed_7" 6 "LimitSpeed_6" 5 "LimitSpeed_5" 4 "LimitSpeed_4" 3 "LimitSpeed_3" 2 "LimitSpeed_2" 1 "LimitSpeed_1" 0 "LimitSpeed_0" ;
VAL_ 985 IaccVLimUnit_D_Rq 3 "NoDataExists" 2 "Mph" 1 "Kph" 0 "Null" ;
VAL_ 985 IaccVLim_D_Rq 252 "NotUsed_2" 250 "LimitSpeed_250" 240 "LimitSpeed_240" 230 "LimitSpeed_230" 220 "LimitSpeed_220" 210 "LimitSpeed_210" 200 "LimitSpeed_200" 190 "LimitSpeed_190" 150 "LimitSpeed_150" 140 "LimitSpeed_140" 130 "LimitSpeed_130" 120 "LimitSpeed_120" 110 "LimitSpeed_110" 100 "LimitSpeed_100" 90 "LimitSpeed_90" 80 "LimitSpeed_80" 70 "LimitSpeed_70" 60 "LimitSpeed_60" 50 "LimitSpeed_50" 40 "LimitSpeed_40" 30 "LimitSpeed_30" 20 "LimtSpeed_20" 251 "NotUsed_1" 255 "Faulty" 254 "NoDataExists" 253 "NotUsed_3" 180 "LimitSpeed_180" 179 "LimitSpeed_179" 178 "LimitSpeed_178" 177 "LimitSpeed_177" 176 "LimitSpeed_176" 175 "LimitSpeed_175" 174 "LimitSpeed_174" 173 "LimitSpeed_173" 172 "LimitSpeed_172" 171 "LimitSpeed_171" 170 "LimitSpeed_170" 169 "LimitSpeed_169" 168 "LimitSpeed_168" 167 "LimitSpeed_167" 166 "LimitSpeed_166" 165 "LimitSpeed_165" 164 "LimitSpeed_164" 163 "LimitSpeed_163" 162 "LimitSpeed_162" 161 "LimitSpeed_161" 160 "LimitSpeed_160" 15 "LimitSpeed_15" 14 "LimitSpeed_14" 13 "LimitSpeed_13" 12 "LimitSpeed_12" 11 "LimitSpeed_11" 10 "LimitSpeed_10" 9 "LimitSpeed_9" 8 "LimitSpeed_8" 7 "LimitSpeed_7" 6 "LimitSpeed_6" 5 "LimitSpeed_5" 4 "LimitSpeed_4" 3 "LimitSpeed_3" 2 "LimitSpeed_2" 1 "LimitSpeed_1" 0 "LimitSpeed_0" ;
VAL_ 985 DasAlrtInfo_D_Dsply 3 "NotUsed" 2 "On" 1 "Off" 0 "Null" ;
VAL_ 985 SblmRndAbtScnr_B_Stat 1 "Yes" 0 "No" ;
VAL_ 985 LongCtrlEnbl_D_Rq 7 "Faulty" 6 "NotUsed_3" 5 "NotUsed_2" 4 "NotUsed_1" 3 "RemoteParking" 2 "Autohitch" 1 "AutomaticParking" 0 "None" ;
VAL_ 985 SblmPedCrossScnr_B_Stat 1 "Yes" 0 "No" ;
VAL_ 985 TsrRegionTxt_D_Stat 31 "Faulty" 30 "NotUsed_8" 29 "NotUsed_7" 28 "NotUsed_6" 27 "NotUsed_5" 26 "NotUsed_4" 25 "NotUsed_3" 24 "NotUsed_2" 23 "NotUsed_1" 22 "Region_22" 21 "Region_21" 20 "Region_20" 19 "Region_19" 18 "Region_18" 17 "Region_17" 16 "Region_16" 15 "Region_15" 14 "Region_14" 13 "Region_13" 12 "Region_12" 11 "Region_11" 10 "Region_10" 9 "Region_09" 8 "Region_08" 7 "Region_07" 6 "Region_06" 5 "Region_05" 4 "Region_04" 3 "Region_03" 2 "Region_02" 1 "Region_01" 0 "NotDetermined" ;
VAL_ 985 LongCtrlBrk_D_Rq 3 "NotUsed" 2 "LowDecel" 1 "HighDecel" 0 "NoRequest" ;
VAL_ 985 LdwChime_B_Rq 1 "On" 0 "Off" ;
VAL_ 942 ApaOffOptnSel_B_Avail 1 "Available" 0 "NotAvailable" ;
VAL_ 942 ApaSlotOption_B_Avail 1 "Available" 0 "NotAvailable" ;
VAL_ 942 ApaSlotAlrtSet_B_Stat 1 "Enable" 0 "Disable" ;
VAL_ 942 ApaSlotAlrt_B_Rq 1 "True" 0 "False" ;
VAL_ 942 ApaRmtFeatSel_B_Avail 1 "Available" 0 "NotAvailable" ;
VAL_ 942 ApaParkOutSel_B_Avail 1 "Available" 0 "NotAvailable" ;
VAL_ 942 ApaSys_D2_Stat 15 "NotUsed_5" 14 "NotUsed_4" 13 "NotUsed_3" 12 "NotUsed_2" 11 "NotUsed_1" 10 "NoSideSelectable" 9 "RightSideSelectable" 8 "LeftSideSelectable" 7 "BothSidesSelectable" 6 "Faulty" 5 "Finished" 4 "Cancelled" 3 "NotAvailable" 2 "Overspeed" 1 "Pause" 0 "NormalOperation" ;
VAL_ 942 ApaSlotTrgt_D_Stat 15 "NotUsed_7" 14 "NotUsed_6" 13 "NotUsed_5" 12 "NotUsed_4" 11 "NotUsed_3" 10 "NotUsed_2" 9 "NotUsed_1" 8 "Front" 7 "Rear" 6 "Right3" 5 "Right2" 4 "Right1" 3 "Left3" 2 "Left2" 1 "Left1" 0 "None" ;
VAL_ 942 ApaParkInSel_B_Avail 1 "Available" 0 "NotAvailable" ;
VAL_ 942 ApaMsgTxt_D2_Stat 15 "ReducedFunction" 14 "TrailerFeatureNotAvailable" 13 "AcceleratorPedalInactive" 12 "SensorsBlocked" 11 "TrailerAttached" 10 "TcsDeactivated" 9 "WheelSlip" 8 "HighInclination" 7 "DoorOpen" 6 "SteeringInteraction" 5 "WrongDirection" 4 "SpeedLimitExceeded" 3 "BrakeEvent" 2 "ObstacleInPath" 1 "WaitForSteering" 0 "None" ;
VAL_ 942 ApaDynmcSlot_B_Stat 1 "On" 0 "Off" ;
VAL_ 942 ApaDisplayMode_D_Stat 3 "NotUsed" 2 "FullScreen" 1 "Menu" 0 "Off" ;
VAL_ 942 ApaControlMode_D_Stat 1 "Active" 0 "Inactive" ;
VAL_ 942 PrkBrkElRleas_B_RqApa 1 "Yes" 0 "No" ;
VAL_ 942 PrkAidAcsyRear_D_Stat 3 "NotUsed" 2 "On" 1 "Off" 0 "Null" ;
VAL_ 942 PrkAidAcsyFront_D_Stat 3 "NotUsed" 2 "On" 1 "Off" 0 "Null" ;
VAL_ 942 PrkAidDrvDir_D_Stat 7 "NotUsed_2" 6 "NotUsed_1" 5 "BackwardNegative" 4 "ForwardNegative" 3 "BackwardPositive" 2 "ForwardPositive" 1 "NoMotion" 0 "DirectionNotKnown" ;
VAL_ 942 ApaDrvRq2MsgTxt_D_Rq 15 "NotUsed_7" 14 "NotUsed_6" 13 "NotUsed_5" 12 "NotUsed_4" 11 "NotUsed_3" 10 "NotUsed_2" 9 "NotUsed_1" 8 "CloseDoor" 7 "TakeControl" 6 "ReleaseEpb" 5 "ReleaseSteering" 4 "ReleaseBrake" 3 "DriveBackward" 2 "DriveForward" 1 "Stop" 0 "NoRequest" ;
VAL_ 942 ApaDrvRq1MsgTxt_D_Rq 7 "NotUsed" 6 "ExitVehicle" 5 "PressApaButton" 4 "ShiftToP" 3 "ShiftToN" 2 "ShiftToD" 1 "ShiftToR" 0 "NoRequest" ;
VAL_ 367 AuthctnInfoLoc_D_Stat 7 "NotUsed_1" 6 "Approach" 5 "RearInterior" 4 "RearExterior" 3 "Passenger" 2 "Driver" 1 "Interior" 0 "Null" ;
VAL_ 367 AuthctnInfo_D_Stat 3 "Authenticated" 2 "AuthenticationFailed" 1 "NotAuthenticated" 0 "Null" ;
VAL_ 367 HashIndx_D_Stat 3 "Success" 2 "NotValid" 1 "Failed" 0 "Null" ;
VAL_ 367 ApnlPsswrdType_D_Stat 15 "NotUsed_3" 14 "NotUsed_2" 13 "NotUsed_1" 12 "ElevatedVehicleBackup" 11 "Elevated" 10 "DriverVehicleBackup" 9 "Driver" 8 "ServiceVehicleBackup" 7 "Service" 6 "UnloaderBackup" 5 "Unloader" 4 "LoaderBackup" 3 "Loader" 2 "RiderBackup" 1 "Rider" 0 "Null" ;
VAL_ 367 AuthctnStatChnl_D_Stat 15 "NotUsed_7" 14 "NotUsed_6" 13 "NotUsed_5" 12 "NotUsed_4" 11 "NotUsed_3" 10 "NotUsed_2" 9 "NotUsed_1" 8 "Sync" 7 "SDM_D" 6 "SDM_C" 5 "SDM_B" 4 "SDM_A" 3 "DAP_R" 2 "DAP_L" 1 "Mobile" 0 "Null" ;
VAL_ 367 AuthctnStat_D_Stat 3 "Authenticated" 2 "AuthenticationFailed" 1 "NotAuthenticated" 0 "Null" ;
VAL_ 948 TlghtTestPrecnd_D2_Stat 7 "TrailerNotConnected" 6 "NotStationary" 5 "InteractionPresent" 4 "PreconditionsPassed" 3 "BattSocLessThan75Percent" 2 "TailLightsOn" 1 "IgnitionNotOn" 0 "Null" ;
VAL_ 948 TlghtTestLght_D2_Stat 7 "TestingRearFogLights" 6 "AllOff" 5 "TestingReverseLights" 4 "TestingBrakeLights" 3 "TestingLeftTurnSignal" 2 "TestingRightTurnSignal" 1 "ParkingLightsIlluminated" 0 "Null" ;
VAL_ 948 Tire_Press_ILR_Stat 4 "Alert" 15 "Not_Supported" 3 "Fault" 2 "Low" 1 "Normal" 0 "Unknown" ;
VAL_ 948 Tire_Press_IRR_Stat 4 "Alert" 15 "Not_Supported" 3 "Fault" 2 "Low" 1 "Normal" 0 "Unknown" ;
VAL_ 948 Tire_Press_LR_OLR_Stat 4 "Alert" 15 "Not_Supported" 3 "Fault" 2 "Low" 1 "Normal" 0 "Unknown" ;
VAL_ 948 Tire_Press_RR_ORR_Stat 4 "Alert" 15 "Not_Supported" 3 "Fault" 2 "Low" 1 "Normal" 0 "Unknown" ;
VAL_ 948 Tire_Press_RF_Stat 4 "Alert" 15 "Not_Supported" 3 "Fault" 2 "Low" 1 "Normal" 0 "Unknown" ;
VAL_ 948 Tire_Press_LF_Stat 4 "Alert" 15 "Not_Supported" 3 "Fault" 2 "Low" 1 "Normal" 0 "Unknown" ;
VAL_ 948 Tire_Press_System_Stat 13 "Training_Complete" 12 "Train_InsideLeftRear_tire" 11 "Train_OutsideLeftRear_tire" 10 "Train_LeftRear_tire" 9 "Train_InsideRtRear_tire" 8 "Train_OutsideRtRear_tire" 7 "Train_RightRear_tire" 14 "Tires_not_trained" 6 "Train_RightFront_tire" 5 "Train_LeftFront_tire" 4 "Systm_Activ_Composite_Stat" 3 "Low_Composite_Stat" 2 "Sensr_Fault_Composite_Stat" 1 "Systm_Fault_Composite_Stat" 0 "Unknown_Composite_Stat" ;
VAL_ 948 Tire_Press_Telltale 3 "Not_Used" 2 "Flash" 1 "On" 0 "Off" ;
VAL_ 948 TirePReset_D_Stat 3 "Not_Used" 2 "Nack" 1 "Ack" 0 "Null" ;
VAL_ 131 TurnLghtSwtch_D_Arb 0 "Idle" 1 "LeftPreLc" 2 "RightPreLc" 3 "LeftLaneChange" 4 "RightLaneChange" 5 "LeftLcCancelled" 6 "RightLcCancelled" 7 "LeftTurn" 8 "RightTurn" 9 "LeftTurnCancelled" 10 "RightTurnCancelled" 11 "NotUsed_1" 12 "NotUsed_2" 13 "NotUsed_3" 14 "NotUsed_4" 15 "Faulty" ;
VAL_ 131 ElPwAsstSte_B_RqDactv 1 "Request" 0 "NoRequest" ;
VAL_ 131 HeadLghtHiCtrl_D_RqAhb 7 "NotUsed2" 6 "NotUsed1" 5 "Auto_HiBeam" 4 "Auto_LoBeam" 3 "Flash" 2 "Man_HiBeam" 1 "Man_LoBeam" 0 "Null" ;
VAL_ 131 AhbStat_B_Dsply 1 "On" 0 "Off" ;
VAL_ 131 WiprFrontSwtch_D_Stat 15 "NotUsed6" 14 "NotUsed5" 13 "NotUsed4" 12 "NotUsed3" 11 "NotUsed2" 10 "NotUsed1" 9 "PositionNotDetermined" 8 "High" 7 "Low" 6 "Position6" 5 "Position5" 4 "Position4" 3 "Position3" 2 "Position2" 1 "Position1" 0 "Off" ;
VAL_ 131 HeadLghtHiOn_B_StatAhb 1 "On" 0 "Off" ;
VAL_ 131 HeadLghtHiFlash_D_Actl 3 "NotUsed" 2 "High" 1 "Flash_to_Pass" 0 "Null" ;
VAL_ 131 TjaButtnOnOffPress 1 "Pressed" 0 "Not_Pressed" ;
VAL_ 131 AccButtnGapTogglePress 1 "Pressed" 0 "Not_Pressed" ;
VAL_ 131 WiprFront_D_Stat 15 "NO_DATA_EXISTS" 14 "STALLED" 13 "RESERVED" 12 "AUTO_ADJUST" 11 "COURTESYWIPE" 10 "AUTO_HIGH" 9 "AUTO_LOW" 8 "WASH" 7 "MIST_FLICK" 6 "MAN_HIGH" 5 "MAN_LOW" 4 "MAN_INT_ON" 3 "MAN_INT_OFF" 2 "OFF_MOVING" 1 "AUTO_OFF" 0 "OFF" ;
VAL_ 131 TurnLghtSwtch_D_Stat 3 "Unused_Treat_As_Off" 2 "Right" 1 "Left" 0 "Off" ;
VAL_ 131 LghtAmb_D_Sns 7 "No_Data_Exists" 6 "Unused2" 5 "Unused1" 4 "Tunnel_Off" 3 "Tunnel_On" 2 "Twilight" 1 "Light" 0 "Dark" ;
VAL_ 131 AccButtnGapIncPress 1 "Button_Pressed" 0 "Button_Not_Pressed" ;
VAL_ 131 AccButtnGapDecPress 1 "Button_Pressed" 0 "Button_Not_Pressed" ;
VAL_ 131 AslButtnOnOffPress 1 "Button_Pressed" 0 "Button_Not_Pressed" ;
VAL_ 131 AslButtnOnOffCnclPress 1 "Button_Pressed" 0 "Button_Not_Pressed" ;
VAL_ 131 CcButtnOnPress 1 "Button_Pressed" 0 "Button_Not_Pressed" ;
VAL_ 131 CcButtnOnOffPress 1 "Button_Pressed" 0 "Button_Not_Pressed" ;
VAL_ 131 CcButtnOnOffCnclPress 1 "Button_Pressed" 0 "Button_Not_Pressed" ;
VAL_ 131 CcButtnOffPress 1 "Button_Pressed" 0 "Button_Not_Pressed" ;
VAL_ 131 CcAsllButtnResPress 1 "Button_Pressed" 0 "Button_Not_Pressed" ;
VAL_ 131 CcAslButtnSetPress 1 "Button_Pressed" 0 "Button_Not_Pressed" ;
VAL_ 131 CcAslButtnSetIncPress 1 "Button_Pressed" 0 "Button_Not_Pressed" ;
VAL_ 131 CcAslButtnSetDecPress 1 "Button_Pressed" 0 "Button_Not_Pressed" ;
VAL_ 131 CcAslButtnResIncPress 1 "Button_Pressed" 0 "Button_Not_Pressed" ;
VAL_ 131 CcAslButtnResDecPress 1 "Button_Pressed" 0 "Button_Not_Pressed" ;
VAL_ 131 CcAslButtnOnPress 1 "Button_Pressed" 0 "Button_Not_Pressed" ;
VAL_ 131 CcAslButtnOnOffCncl 1 "Button_Pressed" 0 "Button_Not_Pressed" ;
VAL_ 131 CcAslButtnOffCnclPress 1 "Button_Pressed" 0 "Button_Not_Pressed" ;
VAL_ 131 CcAslButtnIndxIncPress 1 "Button_Pressed" 0 "Button_Not_Pressed" ;
VAL_ 131 CcAslButtnIndxDecPress 1 "Button_Pressed" 0 "Button_Not_Pressed" ;
VAL_ 131 CcAslButtnDeny_B_Actl 1 "Yes" 0 "No" ;
VAL_ 131 CcAslButtnCnclResPress 1 "Button_Pressed" 0 "Button_Not_Pressed" ;
VAL_ 131 CcAslButtnCnclPress 1 "Button_Pressed" 0 "Button_Not_Pressed" ;
VAL_ 131 LaSwtchPos_D_Stat 3 "Fault" 2 "Unused" 1 "Pressed" 0 "Open" ;
VAL_ 963 Illuminated_Entry_Stat 3 "Invalid" 2 "Unknown" 1 "On" 0 "Off" ;
VAL_ 963 Dr_Courtesy_Light_Stat 3 "Invalid" 2 "Unknown" 1 "On" 0 "Off" ;
VAL_ 963 Courtesy_Delay_Status 3 "Invalid" 2 "Unknown" 1 "On" 0 "Off" ;
VAL_ 963 ImpactEvntFdbck_D_Stat 3 "NotUsed" 2 "EventComplete" 1 "EventInProgress" 0 "Normal" ;
VAL_ 963 WrlssAcsyChrgInhbt_B_Rq 1 "Yes" 0 "No" ;
VAL_ 963 PudLampPsngr_D_Rq 3 "Ramp_Down" 2 "Ramp_Up" 1 "On" 0 "Off" ;
VAL_ 963 HeadLampLoOut_B_Stat 1 "Out" 0 "Null" ;
VAL_ 963 HeadLghtHiFdbck_D_Stat 3 "NotUsed" 2 "Cancel" 1 "Hold" 0 "Allow_Change" ;
VAL_ 963 PudLampDrv_D_Rq 3 "Ramp_Down" 2 "Ramp_Up" 1 "On" 0 "Off" ;
VAL_ 963 TrnNotInPrkChime_B_Rq 1 "On" 0 "Off" ;
VAL_ 963 PrkLightChime_B_Rq 1 "On" 0 "Off" ;
VAL_ 963 KeyInIgnWarn_B_Cmd 1 "On" 0 "Off" ;
VAL_ 963 HomeSafeLtChime_B_Rq 1 "On" 0 "Off" ;
VAL_ 963 StopLghtOn_B_Stat 1 "On" 0 "Off" ;
VAL_ 963 RvrseLghtOn_B_Stat 1 "On" 0 "Off" ;
VAL_ 963 PrkLght_D_Stat 3 "Park_Both" 2 "Park_Right" 1 "Park_Left" 0 "Off" ;
VAL_ 963 HeadLghtSwtch_D_Stat 3 "Autolamp" 2 "Headlamp" 1 "Parklamp" 0 "Off" ;
VAL_ 963 HeadLampLoFrOn_B_Stat 1 "Low" 0 "Not_Low" ;
VAL_ 963 HeadLampLoFlOn_B_Stat 1 "Low" 0 "Not_Low" ;
VAL_ 963 HeadLampLoActv_B_Stat 1 "On" 0 "Off" ;
VAL_ 963 Headlamp_On_Wrning_Cmd 1 "On" 0 "Off" ;
VAL_ 963 Park_Brake_Chime_Rqst 1 "On" 0 "Off" ;
VAL_ 963 HeadLghtHiOn_B_Stat 1 "On" 0 "Off" ;
VAL_ 963 BrkWarnInd_B_Rq 1 "On" 0 "Off" ;
VAL_ 963 Brk_Fluid_Lvl_Low 3 "Invalid" 2 "Unknown" 1 "Low" 0 "OK" ;
VAL_ 963 ReducedGuard_D_Stat 3 "NotUsed" 2 "Alarm_On" 1 "Alarm_Off_Previously_On" 0 "Alarm_Off" ;
VAL_ 963 Perimeter_Alarm_Status 3 "Activated" 2 "Armed" 1 "Prearmed" 0 "Disarmed" ;
VAL_ 963 Courtesy_BSave_Stat 3 "Invalid" 2 "Unknown" 1 "No_Effect" 0 "Off" ;
VAL_ 963 DrTgateLck_D_Stat 3 "NotUsed" 2 "Unlock" 1 "Lock" 0 "Null" ;
VAL_ 963 WndwGlbl_D_Cmd 7 "NotUsed3" 6 "NotUsed2" 5 "NotUsed1" 4 "GLEARN" 3 "GCLOSE" 2 "GOPEN" 1 "GSTOP" 0 "Null" ;
VAL_ 963 PudLamp_D_Rq 3 "RAMP_DOWN" 2 "RAMP_UP" 1 "ON" 0 "OFF" ;
VAL_ 963 DayRnngLampOn_B_Stat 1 "On" 0 "Off" ;
VAL_ 963 PerimeterAlarmChimeRq 1 "On" 0 "Off" ;
VAL_ 932 RmtCtlBattMntr_B_Falt 1 "Yes" 0 "No" ;
VAL_ 932 VehStrtInhbt_D_Stat 1 "Inhibit" 0 "NoInhibit" ;
VAL_ 932 VehOnCtl_D_Stat 3 "NotUsed" 2 "On" 1 "Off" 0 "Null" ;
VAL_ 932 VehOnSrc2_D_Stat 15 "NotUsed_11" 14 "NotUsed_10" 13 "NotUsed_9" 12 "NotUsed_8" 11 "NotUsed_7" 10 "NotUsed_6" 9 "EsclRssd" 8 "AutonomousVehicle" 7 "SecureIdle" 6 "FleetVehicleInhibit" 5 "StolenVehicleInhibit" 4 "OverTheAir" 3 "RemoteParkAssist" 2 "RemoteStart" 1 "Manual" 0 "Off" ;
VAL_ 932 VehInhbtMde_D_Stat 7 "NotUsed_3" 6 "NotUsed_2" 5 "NotUsed_1" 4 "FullVehicleOta" 3 "Iviota" 2 "SyncOta" 1 "NoOtaSupport" 0 "Unconfigured" ;
VAL_ 932 ChildLck_D_Dsply 3 "NOT_SUPPORTED" 2 "ERROR" 1 "CHILD_UNLOCK" 0 "CHILD_LOCK" ;
VAL_ 118 BrkCtrFnd_B_Stat 1 "Yes" 0 "No" ;
VAL_ 118 BrkTerrMdeChng_D_Rdy 7 "Fault" 6 "Undefined_2" 5 "Undefined_1" 4 "ModeUnavailDrInputRqd" 3 "SpOpModes_NotSupported" 2 "ModeUnavailDynamicCond" 1 "Module_In_Initialization" 0 "Mode_Change_Available" ;
VAL_ 118 BrkTerrMde_D_Actl 7 "Fail_Safe_Default" 6 "Dynamic_Mode" 5 "Rock_Crawl_Mode" 4 "Mud_Ruts_Mode" 3 "Sand_Mode" 2 "Undefined" 1 "Low_Mu_Mode" 0 "Special_Operating_Mode_Off" ;
VAL_ 118 DrvSte_D_Stat 15 "NotUsed10" 14 "NotUsed9" 13 "NotUsed8" 12 "NotUsed7" 11 "NotUsed6" 10 "NotUsed5" 9 "NotUsed4" 8 "NotUsed3" 7 "NotUsed2" 6 "NotUsed1" 5 "Request_Active" 4 "Ignition_Off" 3 "DSR_in_Normal_Idle_Mode" 2 "EPAS_Comm_Disturbed" 1 "DSR_Request_Not_Applicable" 0 "DSR_Deactivated" ;
VAL_ 118 DrvSte_Tq_Rq 255 "Invalid" 254 "Unknown" ;
VAL_ 118 EmgcyBrkLamp_D_Rq 3 "NotUsed" 2 "Active_at_standstill" 1 "Active_at_speed" 0 "Inactive" ;
VAL_ 118 StopLamp_B_RqBrk 1 "Active" 0 "Inactive" ;
VAL_ 118 SteWhlCompAnEst_D_Qf 3 "OK" 2 "Not_Within_Specifications" 1 "No_Data_Exists" 0 "Faulty" ;
VAL_ 1045 VehStab_D_Stat 15 "Faulty" 14 "No_Data_Exists" 13 "NotUsed6" 12 "NotUsed5" 11 "NotUsed4" 10 "NotUsed3" 9 "NotUsed2" 8 "Combined_OS_and_US" 7 "High_SSRA_no_OS" 6 "Straight" 5 "Post_Oversteer" 4 "Post_Transition" 3 "Countersteer" 2 "Understeer" 1 "Oversteer" 0 "Linear" ;
VAL_ 1045 BrkFluidLvl_D_Stat 3 "Invalid" 2 "Unknown" 1 "Low" 0 "OK" ;
VAL_ 1045 LsmcBrkDecel_D_Stat 7 "NotUsed_3" 6 "NotUsed_2" 5 "NotUsed_1" 4 "Denied" 3 "FaultDegraded" 2 "FaultExt" 1 "On" 0 "Off" ;
VAL_ 1045 VehYawNonLin_W_Rq 4095 "Fault" 4094 "Unknown" ;
VAL_ 1045 VehYawLin_W_Rq 4095 "Fault" 4094 "Unknown" ;
VAL_ 1045 VehVActlBrk_D_Qf 3 "OK" 2 "Not_Within_Specifications" 1 "No_Data_Exists" 0 "Faulty" ;
VAL_ 947 ValetMode_D_Mem 1 "On" 0 "Off" ;
VAL_ 947 DrStatDrvErrCnt_B_Stat 1 "Yes" 0 "No" ;
VAL_ 947 TurnLghtRight_D_Rq 3 "Seq" 2 "On" 1 "Off" 0 "Null" ;
VAL_ 947 TurnLghtRightOn_B_Stat 1 "On" 0 "Off" ;
VAL_ 947 TurnLghtLeftOn_B_Stat 1 "On" 0 "Off" ;
VAL_ 947 FogLghtRearOn_B_Stat 1 "On" 0 "Off" ;
VAL_ 947 Backlit_LED_Status 15 "Unused3" 14 "Unused2" 13 "Unused1" 12 "Night_12" 11 "Night_11" 10 "Night_10" 9 "Night_9" 8 "Night_8" 7 "Night_7" 6 "Night_6" 5 "Night_5" 4 "Night_4" 3 "Night_3" 2 "Night_2" 1 "Night_1" 0 "Off" ;
VAL_ 947 TurnLghtLeft_D_Rq 3 "Seq" 2 "On" 1 "Off" 0 "Null" ;
VAL_ 947 FogLghtFrontOn_B_Stat 1 "On" 0 "Off" ;
VAL_ 947 IgnKeyType_D_Actl 15 "Invalid" 14 "Unknown" 3 "Key_Not_Prgrm_Read_Failure" 2 "Key_In_Ign_My_Key" 1 "Key_In_Ign_Standard_Key" 0 "Key_Read_In_Progress" ;
VAL_ 947 Parklamp_Status 3 "Invalid" 2 "Unknown" 1 "On" 0 "Off" ;
VAL_ 947 Litval 255 "Invalid" 254 "Unknown" 5 "Day" 4 "Twilight_4" 3 "Twilight_3" 2 "Twilight_2" 1 "Twilight_1" 0 "Night" ;
VAL_ 947 Key_In_Ignition_Stat 1 "In" 0 "Out" ;
VAL_ 947 Ignition_Status 0 "Unknown" 1 "Off" 15 "Invalid" 8 "Start" 4 "Run" 2 "Accessory" ;
VAL_ 947 Dimming_Lvl 255 "Invalid" 254 "Unknown" 18 "Day_6" 17 "Day_5" 16 "Day_4" 15 "Day_3" 14 "Day_2" 13 "Day_1" 12 "Night_12" 11 "Night_11" 10 "Night_10" 9 "Night_9" 8 "Night_8" 7 "Night_7" 6 "Night_6" 5 "Night_5" 4 "Night_4" 3 "Night_3" 2 "Night_2" 1 "Night_1" 0 "Off" ;
VAL_ 947 Day_Night_Status 3 "NotUsed" 2 "Night" 1 "Day" 0 "Null" ;
VAL_ 947 Remote_Start_Status 3 "Invalid" 2 "Unknown" 1 "Remote" 0 "Null" ;
VAL_ 947 DrStatTgate_B_Actl 1 "Ajar" 0 "Closed" ;
VAL_ 947 DrStatRr_B_Actl 1 "Ajar" 0 "Closed" ;
VAL_ 947 DrStatRl_B_Actl 1 "Ajar" 0 "Closed" ;
VAL_ 947 DrStatPsngr_B_Actl 1 "Ajar" 0 "Closed" ;
VAL_ 947 DrStatInnrTgate_B_Actl 1 "Ajar" 0 "Closed" ;
VAL_ 947 DrStatHood_B_Actl 1 "Ajar" 0 "Closed" ;
VAL_ 947 DrStatDrv_B_Actl 1 "Ajar" 0 "Closed" ;
VAL_ 947 PrkBrkActv_B_Actl 1 "Active" 0 "Inactive" ;
VAL_ 947 LifeCycMde_D_Actl 3 "Transport" 2 "NotUsed" 1 "Factory" 0 "Normal" ;
VAL_ 947 Delay_Accy 1 "On" 0 "Off" ;
VAL_ 947 CrashEvnt_D_Stat 3 "Invalid" 2 "Fuel_Cutoff_Event" 1 "Deploy_Event" 0 "No_Event" ;
VAL_ 947 FuelPmpInhbt_B_Stat 1 "Inhibit" 0 "No_Inibit" ;
VAL_ 947 BodySrvcRqd_B_Rq 1 "Yes" 0 "No" ;
VAL_ 126 StePw_B_Rq 1 "Yes" 0 "No" ;
VAL_ 126 StePinRelInit_An_Sns 65535 "Faulty" 65534 "NoDataExists" ;
VAL_ 126 StePinCompAnEst_D_Qf 3 "OK" 2 "Degraded" 1 "No_Data_Exists" 0 "Faulty" ;
VAL_ 357 BPedDrvAppl_D_Qf 3 "OK" 2 "Not_Within_Specifications" 1 "No_Data_Exists" 0 "Faulty" ;
VAL_ 357 CmbbDeny_B_ActlPrpl 1 "Yes" 0 "No" ;
VAL_ 357 PrplTqMnSat_B_Actl 1 "Yes" 0 "No" ;
VAL_ 357 VehStrtStop_D_Rq 3 "NotUsed" 2 "Vehicle_Start_Request" 1 "Vehicle_Stop_Request" 0 "NoRequest" ;
VAL_ 357 BpedDrvAppl_D_Actl 3 "_Not_Allowed" 2 "Driver_Braking" 1 "Driver_Not_Braking" 0 "Not_Allowed" ;
VAL_ 357 CmbbEngTqMn_B_Actl 1 "Yes" 0 "No" ;
VAL_ 357 Veh_V_DsplyCcSet 255 "Fault" 254 "Unknown" ;
VAL_ 357 AccEngStat_D_Actl 7 "Undefined_2" 6 "Undefined_1" 5 "ACCSoonCancel_due_Low_Spd" 4 "Shift_Down_Recommendation" 3 "Shift_Up_Recommendation" 2 "ACCNotAllowedToBeActivated" 1 "ACCStandby_due_Auto_Cancel" 0 "Normal_Operation" ;
VAL_ 357 CcMde_D_Actl 7 "TapDownWaiting" 6 "TapUpWaiting" 5 "Resuming_Low" 4 "Resuming_High" 3 "Decelerating" 2 "Accelerating" 1 "Keeping_Speed" 0 "Not_Active" ;
VAL_ 357 CcStat_D_Actl 7 "Undefined_2" 6 "Undefined_1" 5 "Active" 4 "Active_Que_Assist" 3 "Standby" 2 "Standby_Denied" 1 "Denied" 0 "Off" ;
VAL_ 357 CcOvrrdActv_B_Actl 1 "Cruise_Overridden" 0 "Cruise_Req_Not_Overridden" ;
VAL_ 357 AccStopMde_D_Rq 3 "Stop_Mode_Active" 2 "EPBApplyOrBrakeReleaseWarn" 1 "Limit_Rolling_Speed" 0 "Stop_Mode_Not_Active" ;
VAL_ 651 CrnkInhbtSrvcHlth_B_St 0 "Not_Ok" 1 "Ok" ;
VAL_ 651 TelematicsSrvc_D_St 7 "NotUsed" 6 "NotifyNotActivatedYet" 5 "NotActivatedYet" 4 "NotifyExpired" 3 "Expired" 2 "ExpiringSoon" 1 "Active" 0 "Null" ;
VAL_ 651 EmgcyCallMute_D_Stat 7 "NotUsed4" 6 "NotUsed3" 5 "NotUsed2" 4 "NotUsed1" 3 "ManualEmergencyCallMute" 2 "AutomaticEmergencyCallMute" 1 "EmergencyCallUnmute" 0 "Null" ;
VAL_ 261 AudioToneTouchY_D_Rq 255 "Value254" 2 "Value1_up_to_0xFE_Value253" 1 "Value0" 0 "Null" ;
VAL_ 261 AudioToneTouchX_D_Rq 255 "Value254" 2 "Value1_up_to_0xFE_Value253" 1 "Value0" 0 "Null" ;
VAL_ 261 AudioToneTouch_D_Rq 3 "NotUsed" 2 "Enabled" 1 "Disabled" 0 "Null" ;
VAL_ 261 ChrgStatDsply_D_Rq 3 "NotUsed_2" 2 "NotUsed_1" 1 "On" 0 "Off" ;
VAL_ 261 NextUsageTimeToggle_Rq 0 "Inactive" 2 "Disable" 1 "Enable" ;
VAL_ 261 LongTermParking_Rq 2 "On" 1 "Off" 0 "Inactive" ;
VAL_ 261 ModemReset_D_Rq 15 "NotUsed_11" 14 "NotUsed_10" 13 "NotUsed_9" 12 "NotUsed_8" 11 "NotUsed_7" 10 "NotUsed_6" 9 "NotUsed_5" 8 "NotUsed_4" 7 "NotUsed_3" 6 "BrandConnectReset2" 5 "BrandConnectReset1" 4 "CcsReset" 3 "OnlineTrafficReset" 2 "PaakReset" 1 "WifiHotspotReset" 0 "Null" ;
VAL_ 261 StopStrtDrvMde_B_RqBtn3 1 "Pressed" 0 "Not_Pressed" ;
VAL_ 261 TCU_ESN_D_Rq 3 "NotUsed" 2 "TCU_ESN_Request" 1 "NoRequest" 0 "Inactive" ;
VAL_ 261 FactoryReset_Rq 1 "ResetFactoryDefaults" 0 "Inactive" ;
VAL_ 261 OffPeakTimeSetType_Rq 4 "WeekendEnd" 3 "WeekendStart" 2 "WeekdayEnd" 1 "WeekdayStart" 0 "Inactive" ;
VAL_ 625 NfcSerial_D_Rq 3 "PresentAndProvisioned" 2 "PresentAndProvAlertAck" 1 "PresentAndUnprovisioned" 0 "NotPresent" ;
VAL_ 625 ModemAuthrz_D_Stat2 3 "Null" 2 "RemoveKeys" 1 "Authorized" 0 "NotAuthorized" ;
VAL_ 625 PaakSerial_D2_Rq2 7 "NotUsed_3" 6 "NotUsed_1" 5 "NotUsed_1" 4 "PresentKeyDelivered" 3 "PresentReadyForKeyDelivery" 2 "PresentBlemProvAlertAck" 1 "PresentUnprovisioned" 0 "NotPresent" ;
VAL_ 616 PaakTrgtPreAuthrz_B_Rq 1 "Enable" 0 "Disable" ;
VAL_ 616 KeyPadCodeProg_D_Stat 7 "NotUsed_2" 6 "Duplicate" 5 "ProgrammingFailure" 4 "DeleteAll" 3 "Delete" 2 "Add" 1 "LearningMode" 0 "NormalMode" ;
VAL_ 616 PaakTrgtData_D_Rq 5 "NotUsed_2" 4 "Not_Used1" 3 "Target1_IdBlock2" 2 "Target1_IdBlock1" 1 "Challenge" 0 "Idle" 7 "NotUsed_4" 6 "NotUsed_3" ;
VAL_ 616 PaakTrgtType_D_Rq 7 "NotUsed_4" 6 "NotUsed_3" 5 "NotUsed_2" 4 "NotUsed_1" 3 "Polling" 2 "Registry" 1 "Crypto" 0 "Null" ;
VAL_ 616 PaakTrgtZone_D_Rq 15 "NotUsed_9" 14 "NotUsed_8" 13 "NotUsed_7" 12 "NotUsed_6" 11 "NotUsed_5" 10 "NotUsed_4" 9 "NotUsed_3" 8 "NotUsed_2" 7 "NotUsed_1" 6 "Approach" 5 "RearInterior" 4 "RearExterior" 3 "Passenger" 2 "Driver" 1 "Interior" 0 "Null" ;
VAL_ 617 PaaKMyKeyChng_D_Stat 3 "NotUsed" 2 "ClearAll" 1 "MyKey" 0 "Null" ;
VAL_ 617 PaakAddErase_D_Stat 3 "EraseAll" 2 "Erase" 1 "Add" 0 "Null" ;
VAL_ 622 FobCtlType_D_Stat 3 "NotUsed" 2 "Valid" 1 "Invalid" 0 "Null" ;
VAL_ 895 TurnLght_D_RqRmtCtl 3 "NotUsed" 2 "Right" 1 "Left" 0 "Null" ;
VAL_ 895 RmtCtlRngSet_D_Rq 3 "NotUsed" 2 "RangeSetB" 1 "RangeSetA" 0 "None" ;
VAL_ 895 RmtCtlKeyPoll_D_Rq 3 "NotUsed" 2 "Polling" 1 "NoPolling" 0 "Null" ;
VAL_ 895 RmtCtlCntnsIn_B_Stat 1 "Available" 0 "NotAvailable" ;
VAL_ 895 RmtCtl_D_Stat 15 "Faulty" 14 "NotUsed_5" 13 "NotUsed_4" 12 "NotUsed_3" 11 "NotUsed_2" 10 "NotUsed_1" 9 "Shutdown" 8 "ManeuverFinished" 7 "ReadyForResume" 6 "Pause" 5 "Maneuvering" 4 "ReadyForManeuvering" 3 "Activation" 2 "Initialize" 1 "Preparation" 0 "Disabled" ;
VAL_ 624 PaakAddErase_D_Rq 3 "EraseAll" 2 "Erase" 1 "Add" 0 "Null" ;
VAL_ 621 IgnPsswrdActv_B_Stat 1 "Active" 0 "Inactive" ;
VAL_ 621 FobTrgtZone_D_Rq 15 "NotUsed_9" 14 "NotUsed_8" 13 "NotUsed_7" 12 "NotUsed_6" 11 "NotUsed_5" 10 "NotUsed_4" 9 "NotUsed_3" 8 "NotUsed_2" 7 "NotUsed_1" 6 "Approach" 5 "RearInterior" 4 "RearExterior" 3 "Passenger" 2 "Driver" 1 "Interior" 0 "Null" ;
VAL_ 621 FobTrgtType_D_Rq 7 "NotUsed_4" 6 "NotUsed_3" 5 "NotUsed_2" 4 "NotUsed_1" 3 "Polling" 2 "Registry" 1 "Crypto" 0 "Null" ;
VAL_ 621 RmtCtlRjctAutoCfg_B_Rq 1 "Yes" 0 "No" ;
VAL_ 621 RmtCtlSelSlot_D_Rq 7 "NotUsed_3" 6 "NotUsed_2" 5 "NotUsed_1" 4 "Right" 3 "Left" 2 "Rear" 1 "Front" 0 "None" ;
VAL_ 621 RmtCtlSelPrkMde_D_Rq 3 "NotUsed" 2 "FreeDrive" 1 "ParkIn" 0 "None" ;
VAL_ 621 RmtCtlSelMoveDir_D_Rq 3 "NotUsed" 2 "Backward" 1 "Forward" 0 "None" ;
VAL_ 619 KeyPadCodeProg_D_Rq 7 "NotUsed_3" 6 "NotUsed_2" 5 "NotUsed_1" 4 "DeleteAll" 3 "Delete" 2 "Add" 1 "ProgrammingMode" 0 "Null" ;
VAL_ 619 PaakCnnct_D_Stat 3 "NotUsed" 2 "Connected" 1 "NotConnected" 0 "Null" ;
VAL_ 619 PaakCtlActv_D_Rq 31 "NotUsed_13" 30 "NotUsed_12" 29 "NotUsed_11" 28 "NotUsed_10" 27 "NotUsed_9" 26 "NotUsed_8" 25 "NotUsed_7" 24 "NotUsed_6" 23 "NotUsed_5" 22 "NotUsed_4" 21 "NotUsed_3" 20 "TrunkFrontRelease" 19 "RemoteStop" 18 "RemoteStart" 17 "PowerDecklid" 16 "RightPowerSlidingDoor" 15 "LeftPowerSlidingDoor" 14 "PowerLiftgate" 13 "GlobalClose" 12 "GlobalOpen" 11 "PanicOff" 10 "PanicOn" 9 "LiftgateGlassRelease" 8 "LiftgateRelease" 7 "DecklidRelease" 6 "DoubleLock" 5 "LockAll" 4 "UnlockAllDoorsPlusCargo" 3 "UnlockCargoDoor" 2 "UnlockAllDoors" 1 "UnlockDriverDoor" 0 "Null" ;
VAL_ 618 PaakLoclzd_D_Stat 15 "NotUsed_12" 14 "NotUsed_11" 13 "NotUsed_10" 12 "NotUsed_9" 11 "NotUsed_8" 10 "NotUsed_7" 9 "NotUsed_6" 8 "NotUsed_5" 7 "NotUsed_4" 6 "NotUsed_3" 5 "NotUsed_2" 4 "NotUsed_1" 3 "FullLoc" 2 "PausedLoc" 1 "MaintainLink" 0 "BackgroundScan" ;
VAL_ 618 IgnPsswrdSetup_B_Rq 1 "Active" 0 "Inactive" ;
VAL_ 618 IgnPsswrdLckout_B_Stat 1 "Active" 0 "Inactive" ;
VAL_ 618 PaakCtlType_D_Stat 3 "NotUsed" 2 "Valid" 1 "Invalid" 0 "Null" ;
VAL_ 618 PaakCtlData_D_Stat 7 "NotUsed_3" 6 "NotUsed_2" 5 "NotUsed_1" 4 "Response" 3 "EchoTargetIdBlock1" 2 "RequestTargetIdBlock2" 1 "RequestTargetIdBlock1" 0 "Idle" ;
VAL_ 154 TronTripCnt_No_Actl 8388607 "Faulty" 8388606 "NoDataExists" ;
VAL_ 154 TronResetCnt_No_Actl 4194303 "Faulty" 4194302 "NoDataExists" ;
VAL_ 145 VehYawWActl_D_Qf 3 "OK" 2 "Not_Within_Specifications" 1 "No_Data_Exists" 0 "Faulty" ;
VAL_ 145 VehRolWActl_D_Qf 3 "OK" 2 "Not_Within_Specifications" 1 "No_Data_Exists" 0 "Faulty" ;
VAL_ 145 VehYaw_W_Actl 65535 "Faulty" 65534 "NoDataExists" ;
VAL_ 145 VehRol_W_Actl 65535 "Faulty" 65534 "NoDataExists" ;
VAL_ 1090 VehElRnge_L_Dsply 4094 "NoDataExists" 4095 "Fault" ;
VAL_ 1090 Mtr2State_D_ActlMntr 7 "Faulty" 6 "NoDataExists" 5 "NotUsed_1" 4 "ReadinessState" 3 "DeactivationState" 2 "PowerGeneration" 1 "PowerConsumption" 0 "Null" ;
VAL_ 1090 Inv1Ain_I_ActlMntr 32767 "Faulty" 32766 "NoDataExists" ;
VAL_ 1090 HybVehMde_D_ActlMntr 7 "Faulty" 6 "NoDataExists" 5 "NotUsed_2" 4 "NotUsed_1" 3 "Fuel" 2 "HybridElectric" 1 "AllElectric" 0 "Null" ;
VAL_ 1090 ChrgStat_D_ActlMntr 7 "Faulty" 6 "NoDataExists" 5 "NotUsed" 4 "ChargingCompleted" 3 "NotCharging" 2 "ChargingInDrivingState" 1 "ChargingInParkingState" 0 "Null" ;
VAL_ 945 PaseKeySearch_Stat 0 "Inactive" 1 "Active" ;
VAL_ 945 DelvrAsstMsgTxt_D_Rq 0 "NoMessage" 1 "Message1" 2 "Message2" 3 "Message3" 4 "Message4" 5 "Message5" 6 "Message6" 7 "Message7" 8 "Message8" 9 "Message9" 10 "Message10" 11 "Message11" 12 "Message12" 13 "Message13" 14 "Message14" 15 "Message15" ;
VAL_ 945 AdasRelay_B_Stat2 1 "On" 0 "Off" ;
VAL_ 945 StrtrMtrCtlMsgTxt_D_Rq2 15 "Not_Used_12" 14 "Not_Used_11" 13 "Not_Used_10" 12 "Not_Used_9" 11 "Not_Used_8" 10 "Not_Used_7" 9 "Not_Used_6" 8 "Not_Used_5" 7 "Not_Used_4" 6 "Not_Used_3" 5 "Not_Used_2" 4 "Not_Used_1" 3 "Fault_UnableToStrtOrStop" 2 "PressTwiceToStart" 1 "Fault_GoToDealer" 0 "NoMessage" ;
VAL_ 945 PrkLckCtlMsgTxt_D2_Rq 7 "Message7" 6 "Message6" 5 "Message5" 4 "Message4" 3 "Message3" 2 "Message2" 1 "Message1" 0 "NoMessage" ;
VAL_ 945 KeyOffMde_D_Actl 15 "NotUsed_11" 14 "NotUsed_10" 13 "NotUsed_9" 12 "NotUsed_8" 11 "NotUsed_7" 10 "NotUsed_6" 9 "NotUsed_5" 8 "NotUsed_4" 7 "NotUsed_3" 6 "NotUsed_2" 5 "NotUsed_1" 4 "CriticalBattery" 3 "Hibernate" 2 "Transport" 1 "Factory" 0 "Normal" ;
VAL_ 945 PrkLckCtlLatch_B_Rq 1 "On" 0 "Off" ;
VAL_ 945 KeyPadCodeDgt7_D_Dsply 15 "NotUsed_4" 14 "NotUsed_3" 13 "NotUsed_2" 12 "NotUsed_1" 11 "Button7_8and9_0" 10 "Button0" 9 "Button9_0or9" 8 "Button8" 7 "Button7_8or7" 6 "Button6" 5 "Button5_6or5" 4 "Button4" 3 "Button3_4or3" 2 "Button2" 1 "Button1_2or1" 0 "EndofString" ;
VAL_ 945 KeyPadCodeDgt6_D_Dsply 15 "NotUsed_4" 14 "NotUsed_3" 13 "NotUsed_2" 12 "NotUsed_1" 11 "Button7_8and9_0" 10 "Button0" 9 "Button9_0or9" 8 "Button8" 7 "Button7_8or7" 6 "Button6" 5 "Button5_6or5" 4 "Button4" 3 "Button3_4or3" 2 "Button2" 1 "Button1_2or1" 0 "EndofString" ;
VAL_ 945 KeyPadCodeDgt5_D_Dsply 15 "NotUsed_4" 14 "NotUsed_3" 13 "NotUsed_2" 12 "NotUsed_1" 11 "Button7_8and9_0" 10 "Button0" 9 "Button9_0or9" 8 "Button8" 7 "Button7_8or7" 6 "Button6" 5 "Button5_6or5" 4 "Button4" 3 "Button3_4or3" 2 "Button2" 1 "Button1_2or1" 0 "EndofString" ;
VAL_ 945 KeyPadCodeDgt4_D_Dsply 15 "NotUsed_4" 14 "NotUsed_3" 13 "NotUsed_2" 12 "NotUsed_1" 11 "Button7_8and9_0" 10 "Button0" 9 "Button9_0or9" 8 "Button8" 7 "Button7_8or7" 6 "Button6" 5 "Button5_6or5" 4 "Button4" 3 "Button3_4or3" 2 "Button2" 1 "Button1_2or1" 0 "EndofString" ;
VAL_ 945 KeyPadCodeDgt3_D_Dsply 15 "NotUsed_4" 14 "NotUsed_3" 13 "NotUsed_2" 12 "NotUsed_1" 11 "Button7_8and9_0" 10 "Button0" 9 "Button9_0or9" 8 "Button8" 7 "Button7_8or7" 6 "Button6" 5 "Button5_6or5" 4 "Button4" 3 "Button3_4or3" 2 "Button2" 1 "Button1_2or1" 0 "EndofString" ;
VAL_ 945 KeyPadCodeDgt2_D_Dsply 15 "NotUsed_4" 14 "NotUsed_3" 13 "NotUsed_2" 12 "NotUsed_1" 11 "Button7_8and9_0" 10 "Button0" 9 "Button9_0or9" 8 "Button8" 7 "Button7_8or7" 6 "Button6" 5 "Button5_6or5" 4 "Button4" 3 "Button3_4or3" 2 "Button2" 1 "Button1_2or1" 0 "EndofString" ;
VAL_ 945 KeyPadCodeDgt1_D_Dsply 15 "NotUsed_4" 14 "NotUsed_3" 13 "NotUsed_2" 12 "NotUsed_1" 11 "Button7_8and9_0" 10 "Button0" 9 "Button9_0or9" 8 "Button8" 7 "Button7_8or7" 6 "Button6" 5 "Button5_6or5" 4 "Button4" 3 "Button3_4or3" 2 "Button2" 1 "Button1_2or1" 0 "EndofString" ;
VAL_ 290 WifiHtsptFqBand_D_Rq 3 "NotUsed_1" 2 "Band_2" 1 "Band_1" 0 "Null" ;
VAL_ 290 WifiHtsptTrial_D_RqDrv 3 "NotUsed_1" 2 "StopReminders" 1 "RemindMeLater" 0 "Null" ;
VAL_ 290 WifiHtsptEnbl_D_Rq 3 "Not used" 2 "On" 1 "Off" 0 "Null" ;
VAL_ 290 WifiRemoveDevc_D_Rq 3 "NotUsed_1" 2 "FromBlockedList" 1 "FromConnectedList" 0 "Null" ;
VAL_ 290 WifiHtsptVisbl_D_Rq 3 "Not used" 2 "On" 1 "Off" 0 "Null" ;
VAL_ 290 WifiHtsptMacAddr_B_Rq 1 "Request" 0 "No request" ;
VAL_ 290 WifiDevcList_D_Rq 3 "NoEntry" 2 "BlockedList" 1 "ConnectedList" 0 "Null" ;
VAL_ 290 WifiDataUsage_D_Rq 3 "RetriveDataFromBackend" 2 "RefreshData" 1 "CurrentData" 0 "Null" ;
VAL_ 290 WifiCarrierInfo_B_Rq 1 "Request" 0 "No  request" ;
VAL_ 290 WifiHtsptScrty_D_Rq 3 "NotUsed_1" 2 "Wapi" 1 "Wpa2_Wpa" 0 "Null" ;
VAL_ 636 WifiHtsptFqBand_D_Stat 3 "NotUsed_1" 2 "Band_2" 1 "Band_1" 0 "Null" ;
VAL_ 636 WifiHtspt_D_Falt 15 "Error15" 14 "Error14" 13 "Error13" 12 "Error12" 11 "Error11" 10 "Error10" 9 "Error9" 8 "Error8" 7 "Error7" 6 "Error6" 5 "Error5" 4 "Error4" 3 "Error3" 2 "Error2" 1 "Error1" 0 "Null" ;
VAL_ 636 WifiHtsptCnnct_D_Stat 3 "NotUsed" 2 "Connected" 1 "NotConnected" 0 "Null" ;
VAL_ 636 Telematics_D_Falt 7 "NotUsed_5" 6 "NotUsed_4" 5 "NotUsed_3" 4 "NotUsed_2" 3 "NotUsed_1" 2 "RunTimeError" 1 "ChipsetInitializationFailu" 0 "Null" ;
VAL_ 636 WifiEnbl_D_Stat 3 "NotUsed" 2 "Enable" 1 "Disable" 0 "Null" ;
VAL_ 636 WifiHtsptVisbl_D_Stat 3 "Not  used" 2 "On" 1 "Off" 0 "Null" ;
VAL_ 636 WifiHtsptScrty_D_Stat 3 "NotUsed_1" 2 "Wapi" 1 "Wpa2_Wpa" 0 "Null" ;
VAL_ 636 WifiHtsptEnbl_D_Stat 3 "OnDisabled" 2 "On" 1 "Off" 0 "Null" ;
VAL_ 636 WifiDevcListNew_B_Stat 1 "Available" 0 "NotAvailable" ;
VAL_ 636 WifiDataUsage_D_Stat 3 "PercentDataUsed" 2 "DataPlanExpired" 1 "FreeTrialPeriodWaiting" 0 "Null" ;
VAL_ 636 ModemSigStren_D_Stat 7 "NotUsed_1" 6 "NotDetermined" 5 "FiveBars" 4 "FourBars" 3 "ThreeBars" 2 "TwoBars" 1 "OneBar" 0 "ZeroBars" ;
VAL_ 636 WifiHtsptCrdntl_B_Stat 1 "Available" 0 "NotAvailable" ;
VAL_ 636 WifiHtsptFq_D_Avail 7 "NotUsed_3" 6 "NotUsed_2" 5 "NotUsed_1" 4 "AllAvailable" 3 "Band_2_Only" 2 "Band_1_Only" 1 "AllRestricted" 0 "Null" ;
VAL_ 636 WifiDataUsageOn_D_Stat 3 "NotUsed" 2 "On" 1 "Off" 0 "Null" ;
VAL_ 636 ModemTechnology_D2_Stat 7 "Lte" 6 "HspaPlus" 5 "Umts" 4 "Edge" 3 "Gprs" 2 "Gsm" 1 "NoNetwork" 0 "Null" ;
VAL_ 1087 CrnkInhbtActv_B_Stat 0 "No" 1 "Yes" ;
VAL_ 1087 CrnkInhbtHlthRate_B_Rq 0 "Fast" 1 "Slow" ;
VAL_ 1087 TrlrRngeDsply_B_Stat 1 "On" 0 "Off" ;
VAL_ 1087 StopStrtImccTxt_D_Dspl 15 "Message15" 14 "Message14" 13 "Message13" 12 "Message12" 11 "Message11" 10 "Message10" 9 "Message9" 8 "Message8" 7 "Message7" 6 "Message6" 5 "Message5" 4 "Message4" 3 "Message3" 2 "Message2" 1 "Message1" 0 "NoMessage" ;
VAL_ 1087 StopStrtImccTxt_D_Rq 7 "Message7" 6 "Message6" 5 "Message5" 4 "Message4" 3 "Message3" 2 "Message2" 1 "Message1" 0 "NoMessage" ;
VAL_ 1087 StopStrtImccActv_D_St 7 "NotUsed_3" 6 "NotUsed_2" 5 "NotUsed_1" 4 "Deactivated" 3 "OnSuspended" 2 "OnActive" 1 "OnNotActive" 0 "Off" ;
VAL_ 1087 EngIdlShutDownT_D_Stat 255 "NotUsed_13" 254 "NotUsed_12" 253 "NotUsed_11" 252 "NotUsed_10" 251 "NotUsed_9" 250 "NotUsed_8" 249 "NotUsed_7" 248 "NotUsed_6" 247 "NotUsed_5" 246 "NotUsed_4" 245 "NotUsed_3" 244 "NotUsed_2" 243 "NotUsed_1" 242 "Indefinite_Idle" 241 "Selectable_Idle_Not_Active" 240 "IdleMinutes_240" 239 "IdleMinutes_239" 238 "IdleMinutes_238" 237 "IdleMinutes_237" 236 "IdleMinutes_236" 235 "IdleMinutes_235" 234 "IdleMinutes_234" 233 "IdleMinutes_233" 232 "IdleMinutes_232" 231 "IdleMinutes_231" 230 "IdleMinutes_230" 229 "IdleMinutes_229" 228 "IdleMinutes_228" 227 "IdleMinutes_227" 226 "IdleMinutes_226" 225 "IdleMinutes_225" 224 "IdleMinutes_224" 223 "IdleMinutes_223" 222 "IdleMinutes_222" 221 "IdleMinutes_221" 220 "IdleMinutes_220" 219 "IdleMinutes_219" 218 "IdleMinutes_218" 217 "IdleMinutes_217" 216 "IdleMinutes_216" 215 "IdleMinutes_215" 214 "IdleMinutes_214" 213 "IdleMinutes_213" 212 "IdleMinutes_212" 211 "IdleMinutes_211" 210 "IdleMinutes_210" 209 "IdleMinutes_209" 208 "IdleMinutes_208" 207 "IdleMinutes_207" 206 "IdleMinutes_206" 205 "IdleMinutes_205" 204 "IdleMinutes_204" 203 "IdleMinutes_203" 202 "IdleMinutes_202" 201 "IdleMinutes_201" 200 "IdleMinutes_200" 199 "IdleMinutes_199" 198 "IdleMinutes_198" 197 "IdleMinutes_197" 196 "IdleMinutes_196" 195 "IdleMinutes_195" 194 "IdleMinutes_194" 193 "IdleMinutes_193" 192 "IdleMinutes_192" 191 "IdleMinutes_191" 190 "IdleMinutes_190" 189 "IdleMinutes_189" 188 "IdleMinutes_188" 187 "IdleMinutes_187" 186 "IdleMinutes_186" 185 "IdleMinutes_185" 184 "IdleMinutes_184" 183 "IdleMinutes_183" 182 "IdleMinutes_182" 181 "IdleMinutes_181" 180 "IdleMinutes_180" 179 "IdleMinutes_179" 178 "IdleMinutes_178" 177 "IdleMinutes_177" 176 "IdleMinutes_176" 175 "IdleMinutes_175" 174 "IdleMinutes_174" 173 "IdleMinutes_173" 172 "IdleMinutes_172" 171 "IdleMinutes_171" 170 "IdleMinutes_170" 169 "IdleMinutes_169" 168 "IdleMinutes_168" 167 "IdleMinutes_167" 166 "IdleMinutes_166" 165 "IdleMinutes_165" 164 "IdleMinutes_164" 163 "IdleMinutes_163" 162 "IdleMinutes_162" 161 "IdleMinutes_161" 160 "IdleMinutes_160" 159 "IdleMinutes_159" 158 "IdleMinutes_158" 157 "IdleMinutes_157" 156 "IdleMinutes_156" 155 "IdleMinutes_155" 154 "IdleMinutes_154" 153 "IdleMinutes_153" 152 "IdleMinutes_152" 151 "IdleMinutes_151" 150 "IdleMinutes_150" 149 "IdleMinutes_149" 148 "IdleMinutes_148" 147 "IdleMinutes_147" 146 "IdleMinutes_146" 145 "IdleMinutes_145" 144 "IdleMinutes_144" 143 "IdleMinutes_143" 142 "IdleMinutes_142" 141 "IdleMinutes_141" 140 "IdleMinutes_140" 139 "IdleMinutes_139" 138 "IdleMinutes_138" 137 "IdleMinutes_137" 136 "IdleMinutes_136" 135 "IdleMinutes_135" 134 "IdleMinutes_134" 133 "IdleMinutes_133" 132 "IdleMinutes_132" 131 "IdleMinutes_131" 130 "IdleMinutes_130" 129 "IdleMinutes_129" 128 "IdleMinutes_128" 127 "IdleMinutes_127" 126 "IdleMinutes_126" 125 "IdleMinutes_125" 124 "IdleMinutes_124" 123 "IdleMinutes_123" 122 "IdleMinutes_122" 121 "IdleMinutes_121" 120 "IdleMinutes_120" 119 "IdleMinutes_119" 118 "IdleMinutes_118" 117 "IdleMinutes_117" 116 "IdleMinutes_116" 115 "IdleMinutes_115" 114 "IdleMinutes_114" 113 "IdleMinutes_113" 112 "IdleMinutes_112" 111 "IdleMinutes_111" 110 "IdleMinutes_110" 109 "IdleMinutes_109" 108 "IdleMinutes_108" 107 "IdleMinutes_107" 106 "IdleMinutes_106" 105 "IdleMinutes_105" 104 "IdleMinutes_104" 103 "IdleMinutes_103" 102 "IdleMinutes_102" 101 "IdleMinutes_101" 100 "IdleMinutes_100" 99 "IdleMinutes_99" 98 "IdleMinutes_98" 97 "IdleMinutes_97" 96 "IdleMinutes_96" 95 "IdleMinutes_95" 94 "IdleMinutes_94" 93 "IdleMinutes_93" 92 "IdleMinutes_92" 91 "IdleMinutes_91" 90 "IdleMinutes_90" 89 "IdleMinutes_89" 88 "IdleMinutes_88" 87 "IdleMinutes_87" 86 "IdleMinutes_86" 85 "IdleMinutes_85" 84 "IdleMinutes_84" 83 "IdleMinutes_83" 82 "IdleMinutes_82" 81 "IdleMinutes_81" 80 "IdleMinutes_80" 79 "IdleMinutes_79" 78 "IdleMinutes_78" 77 "IdleMinutes_77" 76 "IdleMinutes_76" 75 "IdleMinutes_75" 74 "IdleMinutes_74" 73 "IdleMinutes_73" 72 "IdleMinutes_72" 71 "IdleMinutes_71" 70 "IdleMinutes_70" 69 "IdleMinutes_69" 68 "IdleMinutes_68" 67 "IdleMinutes_67" 66 "IdleMinutes_66" 65 "IdleMinutes_65" 64 "IdleMinutes_64" 63 "IdleMinutes_63" 62 "IdleMinutes_62" 61 "IdleMinutes_61" 60 "IdleMinutes_60" 59 "IdleMinutes_59" 58 "IdleMinutes_58" 57 "IdleMinutes_57" 56 "IdleMinutes_56" 55 "IdleMinutes_55" 54 "IdleMinutes_54" 53 "IdleMinutes_53" 52 "IdleMinutes_52" 51 "IdleMinutes_51" 50 "IdleMinutes_50" 49 "IdleMinutes_49" 48 "IdleMinutes_48" 47 "IdleMinutes_47" 46 "IdleMinutes_46" 45 "IdleMinutes_45" 44 "IdleMinutes_44" 43 "IdleMinutes_43" 42 "IdleMinutes_42" 41 "IdleMinutes_41" 40 "IdleMinutes_40" 39 "IdleMinutes_39" 38 "IdleMinutes_38" 37 "IdleMinutes_37" 36 "IdleMinutes_36" 35 "IdleMinutes_35" 34 "IdleMinutes_34" 33 "IdleMinutes_33" 32 "IdleMinutes_32" 31 "IdleMinutes_31" 30 "IdleMinutes_30" 29 "IdleMinutes_29" 28 "IdleMinutes_28" 27 "IdleMinutes_27" 26 "IdleMinutes_26" 25 "IdleMinutes_25" 24 "IdleMinutes_24" 23 "IdleMinutes_23" 22 "IdleMinutes_22" 21 "IdleMinutes_21" 20 "IdleMinutes_20" 19 "IdleMinutes_19" 18 "IdleMinutes_18" 17 "IdleMinutes_17" 16 "IdleMinutes_16" 15 "IdleMinutes_15" 14 "IdleMinutes_14" 13 "IdleMinutes_13" 12 "IdleMinutes_12" 11 "IdleMinutes_11" 10 "IdleMinutes_10" 9 "IdleMinutes_9" 8 "IdleMinutes_8" 7 "IdleMinutes_7" 6 "IdleMinutes_6" 5 "IdleMinutes_5" 4 "IdleMinutes_4" 3 "IdleMinutes_3" 2 "IdleMinutes_2" 1 "IdleMinute_1" 0 "Null" ;
VAL_ 1087 StopStrtCstm_D_Stat 3 "Faulty" 2 "On" 1 "Off" 0 "NotAvailable" ;
VAL_ 1087 SelDrvMdeCstmPt_D_Stat 31 "Faulty" 30 "NotUsed15" 29 "NotUsed14" 28 "NotUsed13" 27 "NotUsed12" 26 "NotUsed11" 25 "NotUsed10" 24 "NotUsed9" 23 "NotUsed8" 22 "NotUsed7" 21 "CustomMode" 20 "TrackMode" 19 "OnePedalDrive" 18 "EvLaterChargerMode" 17 "EvNowMode" 16 "DragMode" 15 "HighSpeedDesertMode_Baja" 14 "SportAdaptiveMode" 13 "NotAvailable_13" 12 "NotAvailable_12" 11 "NotAvailable_11" 10 "NotAvailable_10" 9 "RockCrawlMode" 8 "MudRutsMode" 7 "SandMode" 6 "EconomyMode" 5 "GrassGravelSnow" 4 "NotAvailable_04" 3 "TowHaulMode" 2 "NotAvailable_02" 1 "SportMode" 0 "NormalMode" ;
VAL_ 1087 RepaLcGrdInhbt_B_Stat 1 "Yes" 0 "No" ;
VAL_ 1087 FapLcInhbt_B_Rq 1 "Yes" 0 "No" ;
VAL_ 1087 StrtInGearMsgTxt_D_Rq 15 "Message15" 14 "Message14" 13 "Message13" 12 "Message12" 11 "Message11" 10 "Message10" 9 "Message9" 8 "Message8" 7 "Message7" 6 "Message6" 5 "Message5" 4 "Message4" 3 "Message3" 2 "Message2" 1 "Message1" 0 "NoMessage" ;
VAL_ 1087 IgnOffInhbt_B_Stat 1 "Yes" 0 "No" ;
VAL_ 1087 FapLcStopHold_B_Rq 1 "Yes" 0 "No" ;
VAL_ 1087 FapLcPrchgBrk_B_Rq 1 "Yes" 0 "No" ;
VAL_ 1087 FapLcObstcl_B_Stat 1 "Yes" 0 "No" ;
VAL_ 1087 FapLcMaxGrdInhbt_B_Stat 1 "Yes" 0 "No" ;
VAL_ 1087 FapLcMaxGrdAbrt_B_Stat 1 "Yes" 0 "No" ;
VAL_ 1087 FapLcActv_B_Stat 1 "Yes" 0 "No" ;
VAL_ 1087 BattRgenLoDChrg_D_RqEng 3 "Disable" 2 "Retain" 1 "Closed" 0 "Open" ;
VAL_ 1087 BattRgenLoChrg_D_RqEng 3 "Disable" 2 "Retain" 1 "Closed" 0 "Open" ;
VAL_ 1087 AdasLcObtclAbrt_B_Stat 1 "Yes" 0 "No" ;
VAL_ 831 MirrorTelescopic_D_Rq 3 "NotUsed" 2 "Retract" 1 "Extend" 0 "Null" ;
VAL_ 831 RearPassWindowLockCmd 1 "Enable" 0 "Disable" ;
VAL_ 831 RearPassWindowCmd 7 "Unused2" 6 "Unused1" 5 "NotDefined" 4 "Audo_Down" 3 "Manual_Down" 2 "Auto_Up" 1 "Manual_Up" 0 "Idle" ;
VAL_ 831 PassWindowCmd 7 "Unused2" 6 "Unused1" 5 "NotDefined" 4 "Audo_Down" 3 "Manual_Down" 2 "Auto_Up" 1 "Manual_Up" 0 "Idle" ;
VAL_ 831 PassMirrorCmd 7 "Unused" 6 "Unfold" 5 "Fold" 4 "Right" 3 "Left" 2 "Down" 1 "Up" 0 "Idle" ;
VAL_ 831 DipMirrorPosPassenger 1 "Dipped" 0 "Off" ;
VAL_ 831 ActiveStoragePassenger 7 "Unused3" 6 "Unused2" 5 "Unused1" 4 "StoreDipMemoryButton4" 3 "StoreDipMemoryButton3" 2 "StoreDipMemoryButton2" 1 "StoreDipMemoryButton1" 0 "Off" ;
VAL_ 831 RearDriverWindowPos 7 "Unused2" 6 "Unused1" 5 "Fully_Open" 4 "Bet60Percent_FullyOpen" 3 "Bet10Percent_60Percent" 2 "BetFully_10PercentOpen" 1 "Fully_Closed" 0 "Undefined" ;
VAL_ 831 DriverWindowPosition 7 "Unused2" 6 "Unused1" 5 "Fully_Open" 4 "Bet60Percent_FullyOpen" 3 "Bet10Percent_60Percent" 2 "BetFully_10PercentOpen" 1 "Fully_Closed" 0 "Undefined" ;
SIG_GROUP_ 932 Profile1A_SigGroup_FD1_3A4 1 : VehOnSrc2_D_Stat VehOnCtl_D_Stat VehStrtInhbt_D_Stat CanMsg3A4_No_Cnt VehInhbtMde_D_Stat CanMsg3A4_No_Crc;
SIG_GROUP_ 932 Profile1A_SigGroup_FD2_3A4 1 : VehOnSrc2_D_Stat VehOnCtl_D_Stat VehStrtInhbt_D_Stat CanMsg3A4_No_Cnt VehInhbtMde_D_Stat CanMsg3A4_No_Crc;
